VERSION "HNNBNNNYNNNNNNNNNNNNNNNNNNNNNNNNNNNNNNNNNN/4/%%%/4/'%**4NNN///"

NS_ :

BS_:

BU_: BAP_Tester BMS_NV_12V Gateway_Max Klima

BO_ 958 Motor_14: 8 Gateway_Max
 SG_ Motor_14_CRC : 0|8@1+ (1,0) [0|255] ""  Vector__XXX
 SG_ Motor_14_BZ : 8|4@1+ (1,0) [0|15] ""  Vector__XXX
 SG_ MO_StartStopp_Status : 12|2@1+ (1.0,0.0) [0.0|3] ""  Klima
 SG_ MO_StartStopp_Wiederstart : 14|1@1+ (1.0,0.0) [0.0|1] ""  Klima
 SG_ MO_StartStopp_Motorstopp : 15|1@1+ (1.0,0.0) [0.0|1] ""  Klima
 SG_ MO_Freig_Reku : 16|2@1+ (1.0,0.0) [0.0|3] ""  Vector__XXX
 SG_ MO_Kl_75 : 18|1@1+ (1.0,0.0) [0.0|1] ""  Klima
 SG_ MO_Kl_50 : 19|1@1+ (1.0,0.0) [0.0|1] ""  Vector__XXX
 SG_ MO_Gangposition : 20|4@1+ (1.0,0.0) [0.0|15] ""  Vector__XXX
 SG_ MO_StartStopp_Fahrerwunsch : 24|2@1+ (1.0,0.0) [0.0|3] ""  Klima
 SG_ MO_HYB_Fahrbereitschaft : 26|1@1+ (1.0,0.0) [0.0|1] ""  Klima
 SG_ MO_Ext_E_Fahrt_aktiv : 27|1@1+ (1.0,0.0) [0.0|1] ""  Klima
 SG_ MO_Fahrer_bremst : 28|1@1+ (1.0,0.0) [0.0|1] ""  Vector__XXX
 SG_ MO_QBit_Fahrer_bremst : 29|1@1+ (1.0,0.0) [0.0|1] ""  Vector__XXX
 SG_ MO_BLS : 30|1@1+ (1.0,0.0) [0.0|1] ""  Vector__XXX
 SG_ MO_Konsistenz_Bremsped : 31|1@1+ (1.0,0.0) [0.0|1] ""  Vector__XXX
 SG_ MO_Timeout_ESP : 32|1@1+ (1.0,0.0) [0.0|1] ""  Vector__XXX
 SG_ MO_Klima_Eingr : 33|2@1+ (1.0,0.0) [0.0|3] ""  Klima
 SG_ MO_Aussp_Anlass : 35|1@1+ (1.0,0.0) [0.0|1] ""  Vector__XXX
 SG_ MO_Freig_Anlass : 36|1@1+ (1.0,0.0) [0.0|1] ""  Vector__XXX
 SG_ MO_Kuppl_schalter : 37|1@1+ (1.0,0.0) [0.0|1] ""  Vector__XXX
 SG_ MO_Interlock : 38|1@1+ (1.0,0.0) [0.0|1] ""  Vector__XXX
 SG_ MO_Motor_laeuft : 39|1@1+ (1.0,0.0) [0.0|1] ""  Klima
 SG_ MO_Kickdown : 40|1@1+ (1.0,0.0) [0.0|1] ""  Vector__XXX
 SG_ MO_QBit_KL_75 : 41|1@1+ (1.0,0.0) [0.0|1] ""  Vector__XXX
 SG_ MO_EKlKomLeiRed : 42|2@1+ (1.0,0.0) [0.0|3] ""  Klima
 SG_ MO_Handshake_STH : 44|1@1+ (1.0,0.0) [0.0|1] ""  Vector__XXX
 SG_ MO_BKV_Unterdruckwarnung : 45|1@1+ (1.0,0.0) [0.0|1] ""  Vector__XXX
 SG_ MO_Freigabe_Segeln : 46|1@1+ (1.0,0.0) [0.0|1] ""  Vector__XXX
 SG_ MO_PTC_Status : 47|3@1+ (1.0,0.0) [0.0|7] ""  Vector__XXX
 SG_ MO_QBit_Gangposition : 50|1@1+ (1.0,0.0) [0.0|1] ""  Vector__XXX
 SG_ MO_Signalquelle_Gangposition : 51|1@1+ (1.0,0.0) [0.0|1] ""  Vector__XXX
 SG_ MO_Remotestart_Betrieb : 52|1@1+ (1.0,0.0) [0.0|1] ""  Vector__XXX
 SG_ MO_Remotestart_moeglich : 53|1@1+ (1.0,0.0) [0.0|1] ""  Vector__XXX
 SG_ MO_FMAus_aktiv : 55|1@1+ (1.0,0.0) [0.0|1] ""  Vector__XXX
 SG_ MO_FMAus_Startvariante : 56|2@1+ (1.0,0.0) [0.0|3] ""  Vector__XXX
 SG_ MO_BMS_NV_Anf_stuetzen : 58|1@1+ (1.0,0.0) [0.0|1] ""  Vector__XXX
 SG_ MO_Zylinderabschaltung : 59|2@1+ (1.0,0.0) [0.0|3] ""  Vector__XXX
 SG_ MO_HYB_VM_aktiv : 61|1@1+ (1.0,0.0) [0.0|1] ""  Klima
 SG_ MO_StartVorauss_erfuellt : 62|2@1+ (1.0,0.0) [0.0|3] ""  Vector__XXX

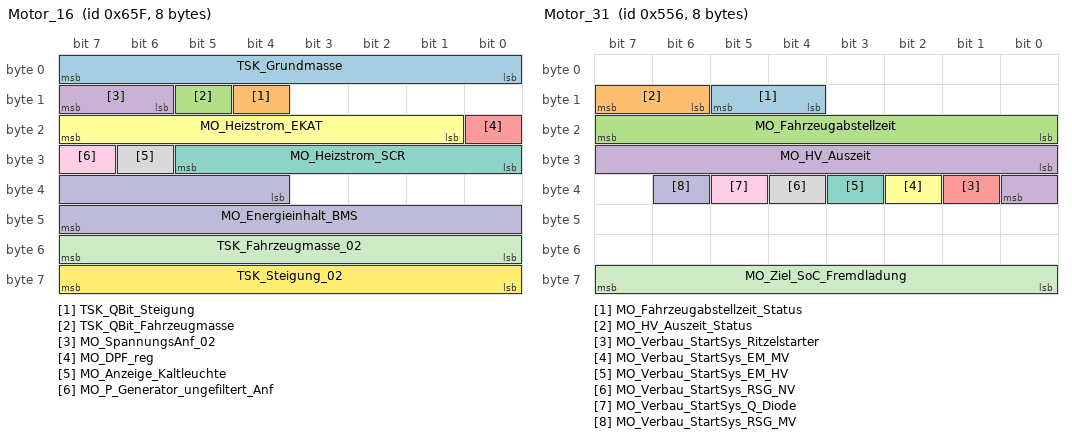
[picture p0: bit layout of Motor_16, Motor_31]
BO_ 1631 Motor_16: 8 Gateway_Max
 SG_ TSK_Grundmasse : 0|8@1+ (32,0) [0|8128] "Unit_KiloGram"  Vector__XXX
 SG_ TSK_QBit_Steigung : 12|1@1+ (1.0,0.0) [0.0|1] ""  Klima
 SG_ TSK_QBit_Fahrzeugmasse : 13|1@1+ (1.0,0.0) [0.0|1] ""  Vector__XXX
 SG_ MO_SpannungsAnf_02 : 14|2@1+ (1.0,0.0) [0.0|3] ""  Vector__XXX
 SG_ MO_DPF_reg : 16|1@1+ (1.0,0.0) [0.0|1] ""  Vector__XXX
 SG_ MO_Heizstrom_EKAT : 17|7@1+ (1,0) [0|126] "Unit_Amper"  Vector__XXX
 SG_ MO_Heizstrom_SCR : 24|6@1+ (1,0) [0|62] "Unit_Amper"  Vector__XXX
 SG_ MO_Anzeige_Kaltleuchte : 30|1@1+ (1.0,0.0) [0.0|1] ""  Vector__XXX
 SG_ MO_P_Generator_ungefiltert_Anf : 31|1@1+ (1.0,0.0) [0.0|1] ""  Vector__XXX
 SG_ MO_Energieinhalt_BMS : 36|12@1+ (25,0) [0|102325] "Unit_WattHour"  Vector__XXX
 SG_ TSK_Fahrzeugmasse_02 : 48|8@1+ (32,0) [0|8128] "Unit_KiloGram"  Vector__XXX
 SG_ TSK_Steigung_02 : 56|8@1+ (0.8,-101.6) [-100.8|101.6] "Unit_PerCent"  Klima

BO_ 1648 Motor_18: 8 Gateway_Max
 SG_ MO_max_Ladedruck : 0|6@1+ (0.1,0) [0.0|6.3] "Unit_Bar"  Vector__XXX
 SG_ MO_ANC_Kennfeld_Anf : 6|2@1+ (1.0,0.0) [0.0|3] ""  Vector__XXX
 SG_ MO_Bremslicht_Reku : 8|1@1+ (1.0,0.0) [0.0|1] ""  Vector__XXX
 SG_ MO_StartStopp_PopUp : 9|2@1+ (1.0,0.0) [0.0|3] ""  Vector__XXX
 SG_ MO1_Sperr_Info_WFS : 11|1@1+ (1.0,0.0) [0.0|1] ""  Vector__XXX
 SG_ MO1_Freigabe_Info_WFS : 12|1@1+ (1.0,0.0) [0.0|1] ""  Vector__XXX
 SG_ MO_EPCL : 13|3@1+ (1.0,0.0) [0.0|7] ""  Vector__XXX
 SG_ MO_Zylabsch_Texte_02 : 16|4@1+ (1.0,0.0) [0.0|15] ""  Vector__XXX
 SG_ MO_Fahrzeugtyp : 20|3@1+ (1.0,0.0) [0.0|7] ""  Vector__XXX
 SG_ MO_NMAX_Schaltanzeige : 23|9@1+ (25,0) [0|12775] "Unit_MinutInver"  Vector__XXX
 SG_ MO_Abstellzeit : 32|8@1+ (8,0) [0|2024] "Unit_Minut"  BMS_NV_12V
 SG_ MO_Abstellzeit_Status : 40|2@1+ (1.0,0.0) [0.0|3] ""  BMS_NV_12V
 SG_ MO1_Freigabe_Verfallsinfo_WFS : 42|1@1+ (1.0,0.0) [0.0|1] ""  Vector__XXX
 SG_ MO_Hybrid_StartStopp_LED : 43|2@1+ (1.0,0.0) [0.0|3] ""  Vector__XXX
 SG_ MO_Fehler_Zylabsch : 45|2@1+ (1.0,0.0) [0.0|3] ""  Vector__XXX
 SG_ MO_Anzahl_Abgesch_Zyl : 47|3@1+ (1.0,0.0) [0.0|7] ""  Vector__XXX
 SG_ MO_Zylabsch_Texte : 50|2@1+ (1.0,0.0) [0.0|3] ""  Vector__XXX
 SG_ MO_Ethanol_BS_Texte : 52|3@1+ (1.0,0.0) [0.0|7] ""  Vector__XXX
 SG_ MO_Drehzahl_Warnung : 55|1@1+ (1.0,0.0) [0.0|1] ""  Vector__XXX
 SG_ MO_obere_Drehzahlgrenze : 56|8@1+ (50,0) [50|12750] "Unit_MinutInver"  Vector__XXX

BO_ 967 Motor_26: 8 Gateway_Max
 SG_ MO_Kuehlerluefter_MUX M  : 0|1@1+ (1.0,0.0) [0.0|1] ""  Klima
 SG_ MO_Kuehlerluefter_1 m0  : 1|7@1+ (1,0) [0|100] "Unit_PerCent"  Klima
 SG_ MO_Kuehlerluefter_2 m1  : 1|7@1+ (1,0) [0|100] "Unit_PerCent"  Klima
 SG_ MO_EFLEX_Lampe : 8|2@1+ (1.0,0.0) [0.0|3] ""  Vector__XXX
 SG_ MO_KJS_nicht_bereit : 10|1@1+ (1.0,0.0) [0.0|1] ""  Vector__XXX
 SG_ MO_ITM_Warnung_Pumpe : 11|1@1+ (1.0,0.0) [0.0|1] ""  Vector__XXX
 SG_ WIV_Anzeige_aktiv : 12|1@1+ (1.0,0.0) [0.0|1] ""  Vector__XXX
 SG_ WIV_Oelmin_Warn : 13|1@1+ (1.0,0.0) [0.0|1] ""  Vector__XXX
 SG_ WIV_Sensorfehler : 14|1@1+ (1.0,0.0) [0.0|1] ""  Vector__XXX
 SG_ WIV_Schieflage : 15|1@1+ (1.0,0.0) [0.0|1] ""  Vector__XXX
 SG_ WIV_Oelstand : 16|4@1+ (12.5,0) [0.0|100.0] "Unit_PerCent"  Vector__XXX
 SG_ MO_Zustand_HWP : 20|2@1+ (1.0,0.0) [0.0|3] ""  Klima
 SG_ OLEV_Systemstoerung : 22|1@1+ (1.0,0.0) [0.0|1] ""  Vector__XXX
 SG_ MO_Oelwarnung_max : 23|1@1+ (1.0,0.0) [0.0|1] ""  Vector__XXX
 SG_ WIV_Oelsystem_aktiv : 24|1@1+ (1.0,0.0) [0.0|1] ""  Vector__XXX
 SG_ WIV_nicht_betriebswarm : 25|1@1+ (1.0,0.0) [0.0|1] ""  Vector__XXX
 SG_ WIV_Ueberfuell_Warn : 26|1@1+ (1.0,0.0) [0.0|1] ""  Vector__XXX
 SG_ WIV_laufender_Motor : 27|1@1+ (1.0,0.0) [0.0|1] ""  Vector__XXX
 SG_ MO_E_Warnungen : 28|4@1+ (1.0,0.0) [0.0|15] ""  Vector__XXX
 SG_ MO_Text_Motorstart : 32|4@1+ (1.0,0.0) [0.0|15] ""  Vector__XXX
 SG_ MO_E_Texte : 36|4@1+ (1.0,0.0) [0.0|15] ""  Vector__XXX
 SG_ WIV_Oeldyn_avl : 40|1@1+ (1.0,0.0) [0.0|1] ""  Vector__XXX
 SG_ MO_Text_Partikelfil_Reg : 41|1@1+ (1,0) [0|1] ""  Vector__XXX
 SG_ OLEV_Oelstand_nicht_vorhanden : 42|1@1+ (1.0,0.0) [0.0|1] ""  Vector__XXX
 SG_ WIV_Oelmenge : 43|5@1+ (125,0) [0|3875] "Unit_MilliLiter"  Vector__XXX
 SG_ MO_Systemlampe : 48|1@1+ (1.0,0.0) [0.0|1] ""  Vector__XXX
 SG_ MO_OBD2_Lampe : 49|1@1+ (1.0,0.0) [0.0|1] ""  Vector__XXX
 SG_ MO_Heissleuchte : 50|1@1+ (1.0,0.0) [0.0|1] ""  Vector__XXX
 SG_ MO_Partikel_Lampe : 51|1@1+ (1.0,0.0) [0.0|1] ""  Vector__XXX
 SG_ MO_RedFahrleistung_Lampe : 52|1@1+ (1.0,0.0) [0.0|1] ""  Klima
 SG_ WIV_Oelstand_nicht_vorhanden : 53|1@1+ (1.0,0.0) [0.0|1] ""  Vector__XXX
 SG_ WIV_nachfuellanzeige_ein : 54|1@1+ (1.0,0.0) [0.0|1] ""  Vector__XXX
 SG_ WIV_Ueberfuell_deaktiv : 55|1@1+ (1.0,0.0) [0.0|1] ""  Vector__XXX
 SG_ WIV_Unterfuell_Warn : 56|1@1+ (1.0,0.0) [0.0|1] ""  Vector__XXX
 SG_ MO_Tankdeckel_Lampe : 57|1@1+ (1.0,0.0) [0.0|1] ""  Vector__XXX
 SG_ MO_Text_Tankdeckelwarn : 58|1@1+ (1.0,0.0) [0.0|1] ""  Vector__XXX
 SG_ MO_Vorglueh_Lampe : 59|1@1+ (1.0,0.0) [0.0|1] ""  Vector__XXX
 SG_ WIV_Oeldr_Warn_Motor : 60|1@1+ (1.0,0.0) [0.0|1] ""  Vector__XXX
 SG_ MO_E_Mode : 61|3@1+ (1.0,0.0) [0.0|7] ""  Vector__XXX

BO_ 1366 Motor_31: 8 Gateway_Max
 SG_ MO_Fahrzeugabstellzeit_Status : 12|2@1+ (1.0,0.0) [0.0|3] ""  Klima
 SG_ MO_HV_Auszeit_Status : 14|2@1+ (1.0,0.0) [0.0|3] ""  Klima
 SG_ MO_Fahrzeugabstellzeit : 16|8@1+ (8,0) [0|2024] "Unit_Minut"  Klima
 SG_ MO_HV_Auszeit : 24|9@1+ (4,0) [0|2036] "Unit_Minut"  Klima
 SG_ MO_Verbau_StartSys_Ritzelstarter : 33|1@1+ (1.0,0.0) [0.0|1] ""  Vector__XXX
 SG_ MO_Verbau_StartSys_EM_MV : 34|1@1+ (1.0,0.0) [0.0|1] ""  Vector__XXX
 SG_ MO_Verbau_StartSys_EM_HV : 35|1@1+ (1.0,0.0) [0.0|1] ""  Vector__XXX
 SG_ MO_Verbau_StartSys_RSG_NV : 36|1@1+ (1.0,0.0) [0.0|1] ""  Vector__XXX
 SG_ MO_Verbau_StartSys_Q_Diode : 37|1@1+ (1.0,0.0) [0.0|1] ""  Vector__XXX
 SG_ MO_Verbau_StartSys_RSG_MV : 38|1@1+ (1.0,0.0) [0.0|1] ""  Vector__XXX
 SG_ MO_Ziel_SoC_Fremdladung : 56|8@1+ (0.4,0) [0.0|100.0] "Unit_PerCent"  Vector__XXX

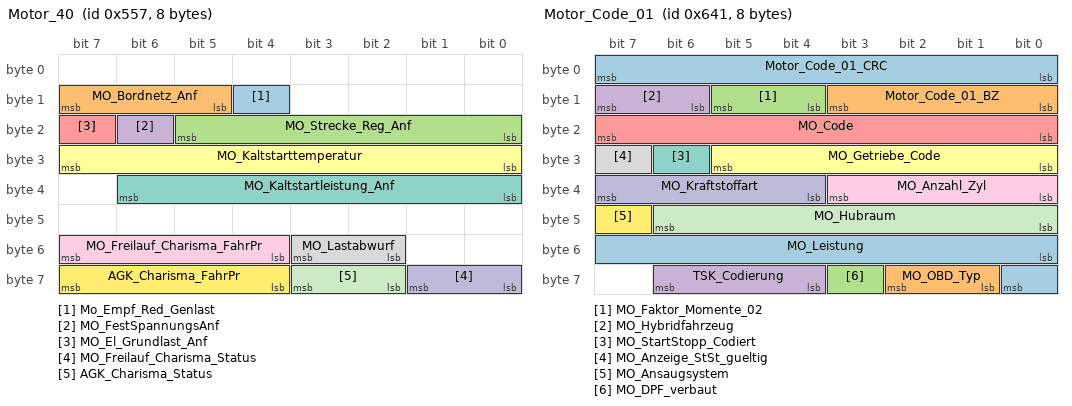
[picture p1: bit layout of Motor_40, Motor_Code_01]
BO_ 1367 Motor_40: 8 Gateway_Max
 SG_ Mo_Empf_Red_Genlast : 12|1@1+ (1.0,0.0) [0.0|1] ""  Vector__XXX
 SG_ MO_Bordnetz_Anf : 13|3@1+ (1.0,0.0) [0.0|7] ""  Vector__XXX
 SG_ MO_Strecke_Reg_Anf : 16|6@1+ (1,0) [0|62] "Unit_KiloMeter"  Vector__XXX
 SG_ MO_FestSpannungsAnf : 22|1@1+ (1.0,0.0) [0.0|1] ""  Vector__XXX
 SG_ MO_El_Grundlast_Anf : 23|1@1+ (1.0,0.0) [0.0|1] ""  Vector__XXX
 SG_ MO_Kaltstarttemperatur : 24|8@1+ (0.5,-40) [-40.0|86.5] "Unit_DegreCelsi"  Vector__XXX
 SG_ MO_Kaltstartleistung_Anf : 32|7@1+ (100,0) [0|12500] "Unit_Watt"  Vector__XXX
 SG_ MO_Lastabwurf : 50|2@1+ (1.0,0.0) [0.0|3] ""  Vector__XXX
 SG_ MO_Freilauf_Charisma_FahrPr : 52|4@1+ (1.0,0.0) [0.0|15] ""  Vector__XXX
 SG_ MO_Freilauf_Charisma_Status : 56|2@1+ (1.0,0.0) [0.0|3] ""  Vector__XXX
 SG_ AGK_Charisma_Status : 58|2@1+ (1.0,0.0) [0.0|3] ""  Vector__XXX
 SG_ AGK_Charisma_FahrPr : 60|4@1+ (1.0,0.0) [0.0|15] ""  Vector__XXX

BO_ 269 Motor_50: 48 Gateway_Max
 SG_ Motor_50_CRC : 0|8@1+ (1,0) [0|255] ""  Vector__XXX
 SG_ Motor_50_BZ : 8|4@1+ (1,0) [0|15] ""  Vector__XXX
 SG_ MO_Mom_Soll_Roh : 12|10@1+ (1,-509) [-509|509] ""  Vector__XXX
 SG_ MO_Mom_Ist_Summe : 22|10@1+ (1,-509) [-509|509] ""  Vector__XXX
 SG_ MO_Mom_Traegheit_Summe : 32|10@1+ (1,-509) [-509|509] ""  Vector__XXX
 SG_ MO_Mom_Soll_gefiltert : 42|10@1+ (1,-509) [-509|509] ""  Vector__XXX
 SG_ MO_Mom_Schub : 52|9@1+ (1,-509) [-509|0] ""  Vector__XXX
 SG_ MO_Status_Normalbetrieb_01 : 61|1@1+ (1.0,0.0) [0.0|1] ""  Vector__XXX
 SG_ MO_erste_Ungenauschwelle : 62|1@1+ (1.0,0.0) [0.0|1] ""  Vector__XXX
 SG_ MO_QBit_Motormomente : 63|1@1+ (1.0,0.0) [0.0|1] ""  Vector__XXX
 SG_ MO_Mom_neg_verfuegbar : 76|9@1+ (1,-509) [-509|0] ""  Vector__XXX
 SG_ MO_Mom_Begr_Fahr : 85|9@1+ (1,0) [0|509] ""  Vector__XXX
 SG_ MO_Mom_Begr_Schalt : 94|10@1+ (1,-509) [-509|509] ""  Vector__XXX
 SG_ MO_Momentenintegral_02 : 104|7@1+ (1,0) [0|100] "Unit_PerCent"  Vector__XXX
 SG_ MO_QBit_Drehzahl_01 : 111|1@1+ (1.0,0.0) [0.0|1] ""  Vector__XXX
 SG_ MO_Drehzahl_01 : 112|16@1+ (0.25,0) [0.00|16383.00] "Unit_MinutInver"  Klima
 SG_ MO_HYB_EMode_Info : 142|2@1+ (1.0,0.0) [0.0|3] ""  Vector__XXX
 SG_ MO_HYB_max_ind_VM_Mom_02 : 144|8@1+ (1.186,0) [0.000|300.058] "Unit_NewtoMeter"  Vector__XXX
 SG_ MO_HYB_Zielzustand : 152|3@1+ (1.0,0.0) [0.0|7] ""  Vector__XXX
 SG_ MO_HYB_Modus_Ankopplung_VM : 155|1@1+ (1.0,0.0) [0.0|1] ""  Vector__XXX
 SG_ MO_HYB_Freigabe_VM_Eingr : 156|2@1+ (1.0,0.0) [0.0|3] ""  Vector__XXX
 SG_ MO_HYB_Sollstatus_K0 : 158|1@1+ (1.0,0.0) [0.0|1] ""  Vector__XXX
 SG_ MO_HYB_Komfortstufe : 159|1@1+ (1.0,0.0) [0.0|1] ""  Vector__XXX
 SG_ MO_HYB_VM_bereit : 160|1@1+ (1.0,0.0) [0.0|1] ""  Vector__XXX
 SG_ MO_HYB_Stoppmodus : 161|1@1+ (1.0,0.0) [0.0|1] ""  Vector__XXX
 SG_ MO_HYB_LowSpeedModus : 162|1@1+ (1.0,0.0) [0.0|1] ""  Vector__XXX
 SG_ MO_HYB_Schaltverhinderung : 163|1@1+ (1.0,0.0) [0.0|1] ""  Vector__XXX
 SG_ MO_HYB_E_Faktor : 164|4@1+ (1.0,0.0) [0.0|15] ""  Vector__XXX
 SG_ MO_HYB_VM_Mom_oE_02 : 168|8@1+ (1.186,-50) [-50.000|250.058] "Unit_NewtoMeter"  Vector__XXX
 SG_ MO_Drehzahl_VM : 176|16@1+ (0.25,0) [0.00|16383.00] "Unit_MinutInver"  Klima
 SG_ MO_EM1_SollDrehzahl : 192|15@1+ (1,-10000) [-10000|22766] "Unit_MinutInver"  Vector__XXX
 SG_ MO_Luftpfad_Verzugszeit_praed : 207|5@1+ (10,0) [10|310] "Unit_MilliSecon"  Vector__XXX
 SG_ MO_EM2_SollDrehzahl : 212|15@1+ (1,-10000) [-10000|22766] "Unit_MinutInver"  Vector__XXX
 SG_ MO_TNW_Min_Strom_Lim : 227|13@1+ (0.5,-2047) [-2047.0|2047.5] "Unit_Amper"  Vector__XXX
 SG_ MO_TNW_Max_Strom_Lim : 240|13@1+ (0.5,-2047) [-2047.0|2047.5] "Unit_Amper"  Vector__XXX

BO_ 332 Motor_54: 32 Gateway_Max
 SG_ Motor_54_CRC : 0|8@1+ (1,0) [0|255] ""  Vector__XXX
 SG_ Motor_54_BZ : 8|4@1+ (1,0) [0|15] ""  Vector__XXX
 SG_ MO_Anforderung_HMS : 12|3@1+ (1.0,0.0) [0.0|7] ""  Vector__XXX
 SG_ FoD_DTC_TSK_GRA : 15|1@1+ (1.0,0.0) [0.0|1] ""  Vector__XXX
 SG_ TSK_vMax_aktuell : 16|8@1+ (1,0) [0|253] "Unit_KiloMeterPerHour"  Vector__XXX
 SG_ ISA_Status : 24|3@1+ (1.0,0.0) [0.0|7] ""  Vector__XXX
 SG_ ISA_Regelung_aktiv : 27|1@1+ (1.0,0.0) [0.0|1] ""  Vector__XXX
 SG_ ISA_Tempolimitwarnung : 28|1@1+ (1.0,0.0) [0.0|1] ""  Vector__XXX
 SG_ MO_Red_El_Fahrleistung : 29|3@1+ (1.0,0.0) [0.0|7] ""  Vector__XXX
 SG_ TSK_Status_EA : 32|3@1+ (1.0,0.0) [0.0|7] ""  Vector__XXX
 SG_ FoD_DTC_TSK_ACC : 35|1@1+ (1.0,0.0) [0.0|1] ""  Vector__XXX
 SG_ TSK_ACC_FoD_Status : 36|2@1+ (1.0,0.0) [0.0|3] ""  Vector__XXX
 SG_ TSK_GRA_FoD_Status : 38|2@1+ (1.0,0.0) [0.0|3] ""  Vector__XXX
 SG_ TSK_vMax_Fahrerassistenz : 40|9@1+ (1,0) [0|510] ""  Vector__XXX
 SG_ TSK_Einheit_vMax_Fahrerassistenz : 49|1@1+ (1.0,0.0) [0.0|1] ""  Vector__XXX
 SG_ TSK_Status_PLA : 50|3@1+ (1.0,0.0) [0.0|7] ""  Vector__XXX
 SG_ TSK_aktives_System : 53|3@1+ (1.0,0.0) [0.0|7] ""  Vector__XXX
 SG_ TSK_erhoehter_Fahrwiderstand : 56|1@1+ (1.0,0.0) [0.0|1] ""  Vector__XXX
 SG_ TSK_Anf_Antriebsmoment : 57|1@1+ (1.0,0.0) [0.0|1] ""  Vector__XXX
 SG_ TSK_Status_ARA : 58|3@1+ (1.0,0.0) [0.0|7] ""  Vector__XXX
 SG_ TSK_Status_IPA : 61|3@1+ (1.0,0.0) [0.0|7] ""  Vector__XXX
 SG_ TSK_aktives_System_02 : 64|4@1+ (1.0,0.0) [0.0|15] ""  Vector__XXX
 SG_ TSK_Status_RHP : 68|3@1+ (1.0,0.0) [0.0|7] ""  Vector__XXX
 SG_ MO_Kuppl_betaetigt : 72|1@1+ (1.0,0.0) [0.0|1] ""  Vector__XXX
 SG_ MO_QBit_Kuppl_betaetigt : 73|1@1+ (1.0,0.0) [0.0|1] ""  Vector__XXX
 SG_ MO_Klima_Regelmodus : 74|2@1+ (1.0,0.0) [0.0|3] ""  Klima
 SG_ MO_Fahrbereitschaft : 76|2@1+ (1.0,0.0) [0.0|3] ""  Vector__XXX
 SG_ MO_Freilauf_Info : 78|2@1+ (1.0,0.0) [0.0|3] ""  Vector__XXX
 SG_ CE_FlgLnchCtlPreCnd : 80|1@1+ (1.0,0.0) [0.0|1] ""  Vector__XXX
 SG_ MO_Krit_Heckobjekt : 81|3@1+ (1.0,0.0) [0.0|7] ""  Vector__XXX
 SG_ MO_NGS_Gangpos : 84|3@1+ (1.0,0.0) [0.0|7] ""  Vector__XXX
 SG_ MO_Freilauf_Status : 87|3@1+ (1.0,0.0) [0.0|7] ""  Vector__XXX
 SG_ MO_EBoost_verf_praed : 90|2@1+ (1.0,0.0) [0.0|3] ""  Vector__XXX
 SG_ MO_Heckspoiler_Anf : 92|1@1+ (1.0,0.0) [0.0|1] ""  Vector__XXX
 SG_ MO_eLaunch_verf : 93|2@1+ (1.0,0.0) [0.0|3] ""  Vector__XXX
 SG_ MO_Positionierung_aktiv : 95|1@1+ (1.0,0.0) [0.0|1] ""  Vector__XXX
 SG_ MO_Veto_Launchcontrol : 96|1@1+ (1.0,0.0) [0.0|1] ""  Vector__XXX
 SG_ MO_Startwunsch : 100|1@1+ (1.0,0.0) [0.0|1] ""  Vector__XXX
 SG_ MO_LaunchControl : 101|1@1+ (1.0,0.0) [0.0|1] ""  Vector__XXX
 SG_ MO_UBE_Hybrid_Reserve : 102|10@1+ (5,0) [0|5110] "Unit_WattHour"  Vector__XXX
 SG_ OBDProtocol_req : 112|8@1+ (1.0,0.0) [0.0|255] ""  BMS_NV_12V,Klima
 SG_ OBD_Calc_Load_Val : 128|8@1+ (0.39215686274509803,0) [0E-17|99.99999999999999765] "Unit_PerCent"  BMS_NV_12V,Klima
 SG_ OBD_Eng_Cool_Temp : 136|8@1+ (1,-40) [-40|215] "Unit_DegreCelsi"  BMS_NV_12V,Klima
 SG_ OBD_Abs_Throttle_Pos : 144|8@1+ (0.39215686274509803,0) [0E-17|99.99999999999999765] "Unit_PerCent"  BMS_NV_12V,Klima
 SG_ OBD_Abs_Load_Val : 152|16@1+ (0.39215686274509803,0) [0E-17|25699.99999999999939605] "Unit_PerCent"  BMS_NV_12V,Klima
 SG_ OBD_Abs_Pedal_Pos : 168|8@1+ (0.39215686274509803,0) [0E-17|99.99999999999999765] "Unit_PerCent"  BMS_NV_12V,Klima
 SG_ MO_Servicemodus : 176|4@1+ (1.0,0.0) [0.0|15] ""  Vector__XXX
 SG_ OBD_ClearMem_Inhibit : 183|1@1+ (1.0,0.0) [0.0|1] ""  BMS_NV_12V
 SG_ OBD_Sperrung_Kaltstart_Denom : 184|1@1+ (1.0,0.0) [0.0|1] ""  BMS_NV_12V
 SG_ MO_QBit_Aussen_Temp : 185|1@1+ (1.0,0.0) [0.0|1] ""  Klima
 SG_ OBD_Sperrung_IUMPR : 186|1@1+ (1.0,0.0) [0.0|1] ""  BMS_NV_12V,Klima
 SG_ OBD_Kaltstart_Denominator : 187|1@1+ (1.0,0.0) [0.0|1] ""  BMS_NV_12V,Klima
 SG_ OBD_Minimum_Trip : 188|1@1+ (1.0,0.0) [0.0|1] ""  BMS_NV_12V,Klima
 SG_ OBD_Driving_Cycle : 189|1@1+ (1.0,0.0) [0.0|1] ""  BMS_NV_12V,Klima
 SG_ OBD_Warm_Up_Cycle : 190|1@1+ (1.0,0.0) [0.0|1] ""  BMS_NV_12V,Klima
 SG_ OBD_Normed_Trip : 191|1@1+ (1.0,0.0) [0.0|1] ""  BMS_NV_12V,Klima
 SG_ MO_EMG_Min_Leistung : 192|11@1+ (100,-102200) [-102200|102300] "Unit_Watt"  Vector__XXX
 SG_ MO_EMG_Max_Leistung : 203|11@1+ (100,-102200) [-102200|102300] "Unit_Watt"  Vector__XXX
 SG_ MO_MVEM_MinLeistung_MVVerbrauch : 214|10@1+ (50,-10500) [-10500|40500] "Unit_Watt"  Vector__XXX
 SG_ MO_MVEM_MaxLeistung_MVVerbrauch : 224|10@1+ (50,-10500) [-10500|40500] "Unit_Watt"  Vector__XXX
 SG_ MO_UBE_Reserve : 238|10@1+ (5,0) [0|5110] "Unit_WattHour"  Vector__XXX
 SG_ OBD_Aussen_Temp_gef : 248|8@1+ (1,-40) [-40|213] "Unit_DegreCelsi"  BMS_NV_12V

BO_ 553 Motor_54_SOK_Signatur: 4 Gateway_Max
 SG_ SOK_Motor_54_Signatur : 0|32@1+ (1,0) [0|4294967295] ""  Klima

BO_ 190 Motor_56: 48 Gateway_Max
 SG_ Motor_56_CRC : 0|8@1+ (1,0) [0|255] ""  Vector__XXX
 SG_ Motor_56_BZ : 8|4@1+ (1,0) [0|15] ""  Vector__XXX
 SG_ MO_EM1_MinDrehzahl : 12|14@1+ (2,-10000) [-10000|22764] "Unit_MinutInver"  Vector__XXX
 SG_ MO_EM1_MaxDrehzahl : 26|14@1+ (2,-10000) [-10000|22764] "Unit_MinutInver"  Vector__XXX
 SG_ MO_EM1_DynLimit_AR : 40|8@1+ (1,0) [0|254] "Unit_NewtoMeter"  Vector__XXX
 SG_ MO_EM1_Periode_AR : 48|8@1+ (0.001953125,0) [0E-9|0.496093750] "Unit_Secon"  Vector__XXX
 SG_ MO_EM1_SollMoment : 56|12@1+ (0.5,-1023) [-1023.0|1023.5] "Unit_NewtoMeter"  Vector__XXX
 SG_ MO_EM1_Sollmodus : 68|4@1+ (1.0,0.0) [0.0|15] ""  Vector__XXX
 SG_ MO_EM1_Min_Leistung : 72|14@1+ (100,-819000) [-819000|819100] "Unit_Watt"  Vector__XXX
 SG_ MO_EM1_Max_Leistung : 86|14@1+ (100,-819000) [-819000|819100] "Unit_Watt"  Vector__XXX
 SG_ MO_EM1_Min_Strom_Lim : 100|13@1+ (0.5,-2047) [-2047.0|2047.5] "Unit_Amper"  Vector__XXX
 SG_ MO_EM1_Max_Strom_Lim : 113|13@1+ (0.5,-2047) [-2047.0|2047.5] "Unit_Amper"  Vector__XXX
 SG_ MO_EM1_AR_Anf : 126|3@1+ (1.0,0.0) [0.0|7] ""  Vector__XXX
 SG_ MO_EM1_Kp_AR : 129|9@1+ (0.00390625,0) [0E-8|1.99218750] "Unit_NewtoMeterPerRPM"  Vector__XXX
 SG_ MO_EM1_SollSpannung : 138|12@1+ (0.5,0) [0.0|2047.0] "Unit_Volt"  Vector__XXX
 SG_ MO_CluEng_Set : 150|2@1+ (1.0,0.0) [0.0|3] ""  Vector__XXX
 SG_ MO_EM2_MinDrehzahl : 156|14@1+ (2,-10000) [-10000|22764] "Unit_MinutInver"  Vector__XXX
 SG_ MO_EM2_MaxDrehzahl : 170|14@1+ (2,-10000) [-10000|22764] "Unit_MinutInver"  Vector__XXX
 SG_ MO_EM2_DynLimit_AR : 184|8@1+ (1,0) [0|254] "Unit_NewtoMeter"  Vector__XXX
 SG_ MO_EM2_Periode_AR : 192|8@1+ (0.001953125,0) [0E-9|0.496093750] "Unit_Secon"  Vector__XXX
 SG_ MO_EM2_SollMoment : 200|12@1+ (0.5,-1023) [-1023.0|1023.5] "Unit_NewtoMeter"  Vector__XXX
 SG_ MO_EM2_Sollmodus : 212|4@1+ (1.0,0.0) [0.0|15] ""  Vector__XXX
 SG_ MO_EM2_Min_Leistung : 216|14@1+ (100,-819000) [-819000|819100] "Unit_Watt"  Vector__XXX
 SG_ MO_EM2_Max_Leistung : 230|14@1+ (100,-819000) [-819000|819100] "Unit_Watt"  Vector__XXX
 SG_ MO_EM2_Min_Strom_Lim : 244|13@1+ (0.5,-2047) [-2047.0|2047.5] "Unit_Amper"  Vector__XXX
 SG_ MO_EM2_Max_Strom_Lim : 257|13@1+ (0.5,-2047) [-2047.0|2047.5] "Unit_Amper"  Vector__XXX
 SG_ MO_EM2_AR_Anf : 270|3@1+ (1.0,0.0) [0.0|7] ""  Vector__XXX
 SG_ MO_EM2_Kp_AR : 273|9@1+ (0.00390625,0) [0E-8|1.99218750] "Unit_NewtoMeterPerRPM"  Vector__XXX
 SG_ MO_EM2_SollSpannung : 282|12@1+ (0.5,0) [0.0|2047.0] "Unit_Volt"  Vector__XXX
 SG_ MO_CluAxs_Set : 294|2@1+ (1.0,0.0) [0.0|3] ""  Vector__XXX
 SG_ MO_DC_Max_Strom_HV : 296|8@1+ (0.2,0) [0.0|50.8] "Unit_Amper"  Vector__XXX
 SG_ MO_DC_SollSpannung_HV : 304|8@1+ (2,0) [0|508] "Unit_Volt"  Vector__XXX
 SG_ MO_EM1_Max_Moment : 312|12@1+ (0.5,-1023) [-1023.0|1023.5] "Unit_NewtoMeter"  Vector__XXX
 SG_ MO_EM1_Min_Moment : 324|12@1+ (0.5,-1023) [-1023.0|1023.5] "Unit_NewtoMeter"  Vector__XXX
 SG_ MO_EM2_Max_Moment : 336|12@1+ (0.5,-1023) [-1023.0|1023.5] "Unit_NewtoMeter"  Vector__XXX
 SG_ MO_EM2_Min_Moment : 348|12@1+ (0.5,-1023) [-1023.0|1023.5] "Unit_NewtoMeter"  Vector__XXX
 SG_ SOK_MO_SollMoment_Signatur : 360|24@1+ (1,0) [0|16777215] "Unit_None"  Vector__XXX

BO_ 1601 Motor_Code_01: 8 Gateway_Max
 SG_ Motor_Code_01_CRC : 0|8@1+ (1,0) [0|255] ""  Vector__XXX
 SG_ Motor_Code_01_BZ : 8|4@1+ (1,0) [0|15] ""  Vector__XXX
 SG_ MO_Faktor_Momente_02 : 12|2@1+ (1,0) [1|3] "Unit_NewtoMeter"  Vector__XXX
 SG_ MO_Hybridfahrzeug : 14|2@1+ (1.0,0.0) [0.0|3] ""  Klima
 SG_ MO_Code : 16|8@1+ (1,0) [0|255] ""  Vector__XXX
 SG_ MO_Getriebe_Code : 24|6@1+ (1.0,0.0) [0.0|63] ""  Vector__XXX
 SG_ MO_StartStopp_Codiert : 30|1@1+ (1.0,0.0) [0.0|1] ""  Vector__XXX
 SG_ MO_Anzeige_StSt_gueltig : 31|1@1+ (1.0,0.0) [0.0|1] ""  Vector__XXX
 SG_ MO_Anzahl_Zyl : 32|4@1+ (1.0,0.0) [0.0|15] ""  Vector__XXX
 SG_ MO_Kraftstoffart : 36|4@1+ (1.0,0.0) [0.0|15] ""  Vector__XXX
 SG_ MO_Hubraum : 40|7@1+ (0.1,0) [0.0|12.7] "Unit_Liter"  Vector__XXX
 SG_ MO_Ansaugsystem : 47|1@1+ (1.0,0.0) [0.0|1] ""  Vector__XXX
 SG_ MO_Leistung : 48|9@1+ (1,0) [0|511] "Unit_KiloWatt"  Vector__XXX
 SG_ MO_OBD_Typ : 57|2@1+ (1.0,0.0) [0.0|3] ""  BMS_NV_12V,Klima
 SG_ MO_DPF_verbaut : 59|1@1+ (1.0,0.0) [0.0|1] ""  Vector__XXX
 SG_ TSK_Codierung : 60|3@1+ (1.0,0.0) [0.0|7] ""  Vector__XXX

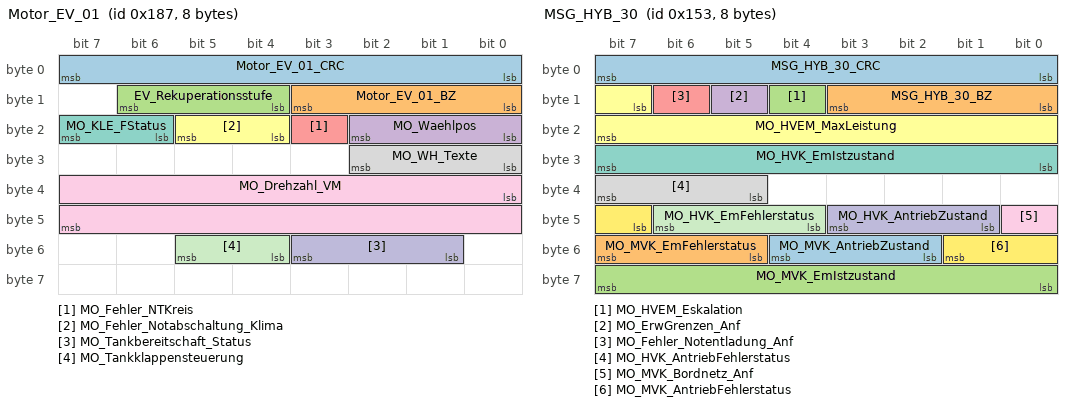
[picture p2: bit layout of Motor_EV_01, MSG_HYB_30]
BO_ 391 Motor_EV_01: 8 Gateway_Max
 SG_ Motor_EV_01_CRC : 0|8@1+ (1,0) [0|255] ""  Vector__XXX
 SG_ Motor_EV_01_BZ : 8|4@1+ (1,0) [0|15] ""  Vector__XXX
 SG_ EV_Rekuperationsstufe : 12|3@1+ (1.0,0.0) [0.0|7] ""  Vector__XXX
 SG_ MO_Waehlpos : 16|3@1+ (1.0,0.0) [0.0|7] ""  Vector__XXX
 SG_ MO_Fehler_NTKreis : 19|1@1+ (1.0,0.0) [0.0|1] ""  Vector__XXX
 SG_ MO_Fehler_Notabschaltung_Klima : 20|2@1+ (1.0,0.0) [0.0|3] ""  Vector__XXX
 SG_ MO_KLE_FStatus : 22|2@1+ (1.0,0.0) [0.0|3] ""  Klima
 SG_ MO_WH_Texte : 24|3@1+ (1.0,0.0) [0.0|7] ""  Vector__XXX
 SG_ MO_Drehzahl_VM : 32|16@1+ (0.25,0) [0.00|16383.00] "Unit_MinutInver"  BMS_NV_12V
 SG_ MO_Tankbereitschaft_Status : 49|3@1+ (1.0,0.0) [0.0|7] ""  Vector__XXX
 SG_ MO_Tankklappensteuerung : 52|2@1+ (1.0,0.0) [0.0|3] ""  Vector__XXX

BO_ 339 MSG_HYB_30: 8 Gateway_Max
 SG_ MSG_HYB_30_CRC : 0|8@1+ (1,0) [0|255] ""  Vector__XXX
 SG_ MSG_HYB_30_BZ : 8|4@1+ (1,0) [0|15] ""  Vector__XXX
 SG_ MO_HVEM_Eskalation : 12|1@1+ (1.0,0.0) [0.0|1] ""  Vector__XXX
 SG_ MO_ErwGrenzen_Anf : 13|1@1+ (1.0,0.0) [0.0|1] ""  Vector__XXX
 SG_ MO_Fehler_Notentladung_Anf : 14|1@1+ (1.0,0.0) [0.0|1] ""  Vector__XXX
 SG_ MO_HVEM_MaxLeistung : 15|9@1+ (50,0) [0|25450] "Unit_Watt"  Klima
 SG_ MO_HVK_EmIstzustand : 24|8@1+ (1.0,0.0) [0.0|255] ""  Vector__XXX
 SG_ MO_HVK_AntriebFehlerstatus : 37|3@1+ (1.0,0.0) [0.0|7] ""  Vector__XXX
 SG_ MO_MVK_Bordnetz_Anf : 40|1@1+ (1.0,0.0) [0.0|1] ""  Vector__XXX
 SG_ MO_HVK_AntriebZustand : 41|3@1+ (1.0,0.0) [0.0|7] ""  Vector__XXX
 SG_ MO_HVK_EmFehlerstatus : 44|3@1+ (1.0,0.0) [0.0|7] ""  Vector__XXX
 SG_ MO_MVK_AntriebFehlerstatus : 47|3@1+ (1.0,0.0) [0.0|7] ""  Vector__XXX
 SG_ MO_MVK_AntriebZustand : 50|3@1+ (1.0,0.0) [0.0|7] ""  Vector__XXX
 SG_ MO_MVK_EmFehlerstatus : 53|3@1+ (1.0,0.0) [0.0|7] ""  Vector__XXX
 SG_ MO_MVK_EmIstzustand : 56|8@1+ (1.0,0.0) [0.0|255] ""  Vector__XXX

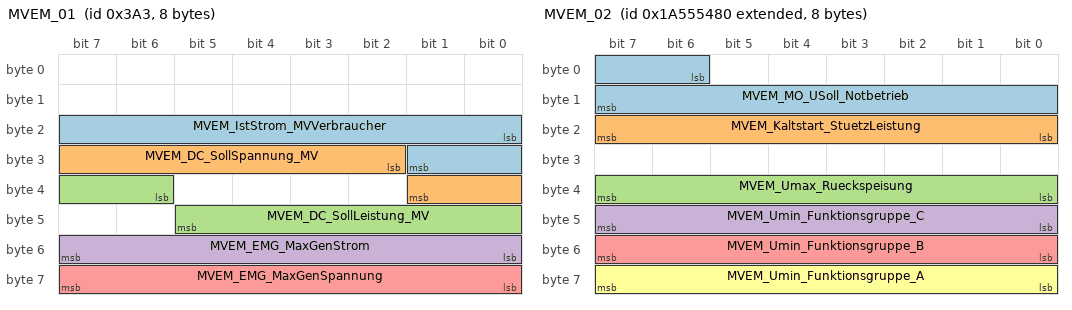
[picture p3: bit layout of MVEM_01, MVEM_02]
BO_ 931 MVEM_01: 8 Gateway_Max
 SG_ MVEM_IstStrom_MVVerbraucher : 16|10@1+ (1,-511) [-511|510] "Unit_Amper"  Vector__XXX
 SG_ MVEM_DC_SollSpannung_MV : 26|8@1+ (0.25,0) [0.00|63.25] "Unit_Volt"  Vector__XXX
 SG_ MVEM_DC_SollLeistung_MV : 38|8@1+ (25,-6325) [-6325|0] "Unit_Watt"  Vector__XXX
 SG_ MVEM_EMG_MaxGenStrom : 48|8@1+ (2,0) [0|506] "Unit_Amper"  Vector__XXX
 SG_ MVEM_EMG_MaxGenSpannung : 56|8@1+ (0.25,0) [0.00|63.25] "Unit_Volt"  Vector__XXX

BO_ 2589283456 MVEM_02: 8 Gateway_Max
 SG_ MVEM_MO_USoll_Notbetrieb : 6|10@1+ (0.0625,0) [0.0000|63.8125] "Unit_Volt"  Vector__XXX
 SG_ MVEM_Kaltstart_StuetzLeistung : 16|8@1+ (20,0) [0|5060] "Unit_Watt"  Vector__XXX
 SG_ MVEM_Umax_Rueckspeisung : 32|8@1+ (0.25,0) [0.00|63.25] "Unit_Volt"  Vector__XXX
 SG_ MVEM_Umin_Funktionsgruppe_C : 40|8@1+ (0.25,0) [0.00|63.25] "Unit_Volt"  Vector__XXX
 SG_ MVEM_Umin_Funktionsgruppe_B : 48|8@1+ (0.25,0) [0.00|63.25] "Unit_Volt"  Vector__XXX
 SG_ MVEM_Umin_Funktionsgruppe_A : 56|8@1+ (0.25,0) [0.00|63.25] "Unit_Volt"  Vector__XXX

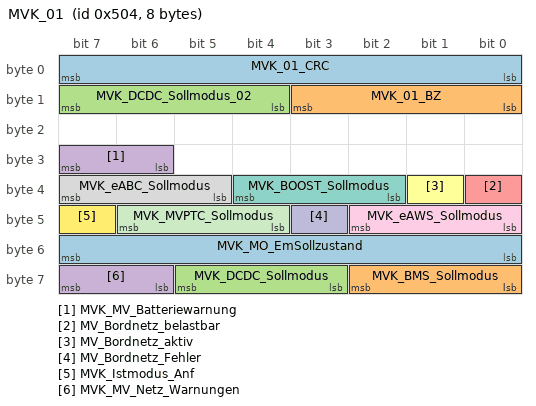
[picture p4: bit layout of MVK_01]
BO_ 1284 MVK_01: 8 Gateway_Max
 SG_ MVK_01_CRC : 0|8@1+ (1,0) [0|255] ""  Vector__XXX
 SG_ MVK_01_BZ : 8|4@1+ (1,0) [0|15] ""  Vector__XXX
 SG_ MVK_DCDC_Sollmodus_02 : 12|4@1+ (1.0,0.0) [0.0|15] ""  Vector__XXX
 SG_ MVK_MV_Batteriewarnung : 30|2@1+ (1.0,0.0) [0.0|3] ""  Vector__XXX
 SG_ MV_Bordnetz_belastbar : 32|1@1+ (1.0,0.0) [0.0|1] ""  Vector__XXX
 SG_ MV_Bordnetz_aktiv : 33|1@1+ (1.0,0.0) [0.0|1] ""  Vector__XXX
 SG_ MVK_BOOST_Sollmodus : 34|3@1+ (1.0,0.0) [0.0|7] ""  Vector__XXX
 SG_ MVK_eABC_Sollmodus : 37|3@1+ (1.0,0.0) [0.0|7] ""  Vector__XXX
 SG_ MVK_eAWS_Sollmodus : 40|3@1+ (1.0,0.0) [0.0|7] ""  Vector__XXX
 SG_ MV_Bordnetz_Fehler : 43|1@1+ (1.0,0.0) [0.0|1] ""  Vector__XXX
 SG_ MVK_MVPTC_Sollmodus : 44|3@1+ (1.0,0.0) [0.0|7] ""  Vector__XXX
 SG_ MVK_Istmodus_Anf : 47|1@1+ (1.0,0.0) [0.0|1] ""  Vector__XXX
 SG_ MVK_MO_EmSollzustand : 48|8@1+ (1.0,0.0) [0.0|255] ""  Vector__XXX
 SG_ MVK_BMS_Sollmodus : 56|3@1+ (1.0,0.0) [0.0|7] ""  Vector__XXX
 SG_ MVK_DCDC_Sollmodus : 59|3@1+ (1.0,0.0) [0.0|7] ""  Vector__XXX
 SG_ MVK_MV_Netz_Warnungen : 62|2@1+ (1.0,0.0) [0.0|3] ""  Vector__XXX

CM_ BO_ 1648 "Kombischnittstelle";
CM_ BO_ 967 "MQB - vorher Motor_06 / Umbenennung wg. ID-Wechsel";
CM_ BO_ 1601 "ab MQB mit CRC-8";
CM_ BO_ 339 "CAN-Botschaft";

CM_ SG_ 958 MO_Aussp_Anlass "Das Signal zeigt an, ob die Wiederholstartsperre aktiv ist. D. h. eine Ansteuerung des Anlassers wird auch bei erfüllten Startvoraussetzungen (HS: Interlock betätigt bzw. AT: P/N eingelegt und Bremse betätigt) nicht erfolgen.";
CM_ SG_ 958 MO_BKV_Unterdruckwarnung "Über die Unterdruckwarnung signalisiert das MSG dem ESP, dass kein ausreichender Unterdruck für den BKV zur Verfügung gestellt werden kann.";
CM_ SG_ 958 MO_BLS "Ungefiltertes Rohsignal des Bremslichtschalters, nur wenn HW-Eingang bestückt und ausgewertet wird. Bei Motoren ohne genutzten HW-Eingang wird kein Ersatzwert (bspw. SW-Signal über CAN) ausgegeben!
Bei AUDI muss das Signal wg. Bremslichtfunktion immer be";
CM_ SG_ 958 MO_BMS_NV_Anf_stuetzen "Garantierte Unterstützung des Zusatzspeichers ist erforderlich. Zusatzspeicher muss an das Versorgungsnezt angebunden werden. ";
CM_ SG_ 958 MO_EKlKomLeiRed "Anforderung an die Klimasteuerung, die Leistungsaufnahme des E-Kompressors bei schlechtem SOC und in bestimmten Fahrsituationen zu begrenzen. (Das bereits bestehende Signal 'Klimakompressor aus' als stets umzusetzende Anforderung bleibt unverändert besteh";
CM_ SG_ 958 MO_Ext_E_Fahrt_aktiv "Funktionsrückmeldung zum erw. E-Fahr-Betrieb über Lampe/LED im E-Mode-Taster";
CM_ SG_ 958 MO_Fahrer_bremst "Redundante Bremsinformation vom Motor.

MLB:
AUDI D4: Zykluszeit: 10ms (siehe Zykluszeit schnell/Cycletime Fast)
Im AUDI B8 wird in diesem Bit der Wert der ESP-CAN-Information 'ESP_Fahrer_bremst' ausgegeben.

Achtung:
Reduktion der Zykluszeit Motor";
CM_ SG_ 958 MO_FMAus_aktiv "Das Signal gibt Rückmeldung ob Freilauf Motor aus aktiv ist. Beleibt auch 0km/h (unterhalb der StartStopp Schwelle) weiterhin aktiv.";
CM_ SG_ 958 MO_FMAus_Startvariante "Startvariante beim Motorstart aus der Freilauf-Motor-AUS Phase";
CM_ SG_ 958 MO_Freig_Anlass "Bit wird gesetzt, wenn der Motor beim Automatikstart gestartet werden darf (Motorstillstand, Emissionsmaßnahmen sind erfüllt).";
CM_ SG_ 958 MO_Freig_Reku "Empfehlung des Motor-SG's zur Spannungsabsenkung/-anhebung für den Rekuperationsbetrieb";
CM_ SG_ 958 MO_Freigabe_Segeln "Freigabebit des Segelbetriebs im Getriebe. Bedingt durch bestimmte Diagnosen und Adaptionen des MSGs, die nur im Schub möglich sind, darf nicht jede Schubphase für einen Segelbetrieb genutzt werden. Eine Freigabe bleibt auch außerhalb einer Schubphase bes";
CM_ SG_ 958 MO_Gangposition "MLB:
Stellung des Wählhebels in der Schaltgasse des Handschaltgetriebes.
MLBevo: 
Ausweitung der Bedienung auch auf Automatikgetriebe;
Routing des Signals GE_Fahrstufe: 
1. Position_R (dez. 6) auf MO_Gangposition: Gang_R (dez. 13) wegen Entfall Signa";
CM_ SG_ 958 MO_Handshake_STH "Es gilt: Signalspec MO_Handshake v1.0

Handshake zwischen MSG und STH. Wenn das MSG die EKP aufgrund einer STH-Anforderung ansteuert und kein Fehlereintrag bzgl. EKP/KPE/NDR vorliegt, wird das Bit gesetzt.";
CM_ SG_ 958 MO_HYB_Fahrbereitschaft "Signal steuert u.a. in der Lenkhilfe zusammen mit weiteren Informationen den Modewechsel in den 'Drivemode'
Grüne Anzeige im Kombiinstrument zur Signalisierung der Bereitschaft des Hybridsystems.";
CM_ SG_ 958 MO_HYB_VM_aktiv "0 = VMotor wird nicht aktiv gehalten (nVM < n_min und keine LL-Regelung aktiv)
1 = VMotor aktiv (ab der ersten Einspritzung; gilt auch für Schubbetrieb, wenn VMotor spätestens durch LLRegelung befeuert würde)
Verwendet zur Bestimmung des Ist-Zustandes";
CM_ SG_ 958 MO_Interlock "Das Motorsteuergerät gibt die Information aus, ab wann der Kupplungsschalter durch das Motorsteuergerät als getreten gesehen wird.
Bei Systemen für Start Stopp muss das Interlocksignal für einen Start durch das MSG generiert werden, sobald der Schalthebe";
CM_ SG_ 958 MO_Kickdown "Es gilt: Signalspec MO_Kickdown v1.0";
CM_ SG_ 958 MO_Kl_50 "Klemme 50: Startausführung durch Ritzelstarter

MLB: nicht von allen Motoren gesendet
MQB/MLBevo: gesendet von allen Motoren";
CM_ SG_ 958 MO_Kl_75 "Klemme X
";
CM_ SG_ 958 MO_Klima_Eingr "Eingriffe des Motor bei der Klima";
CM_ SG_ 958 MO_Konsistenz_Bremsped "MLB:

AUDI D4: Zykluszeit: 10ms (siehe Zykluszeit schnell/Cycletime Fast)
Siehe 'Funktionsspezifikation Bremslichtinfo B8'

Achtung:
Reduktion der Zykluszeit Motor_03 auf 10ms geplant.
Projektabhängig soll künftig mit 10ms gesendet werden.
Empfäng";
CM_ SG_ 958 MO_Kuppl_schalter "MLB:
Das Motorsteuergerät gibt die Information aus, ab wann der Kupplungsschalter durch das Motorsteuergerät als getreten gesehen wird
0x0: Schalter sagt betätigt (Ausgekuppelt)
0x1: Schalter sagt nicht betätigt (Eingekuppelt)

MQB:
Nur Handschalter";
CM_ SG_ 958 MO_Motor_laeuft "Das Motorsteuergerät gibt die Information aus, ab wann der Motor verbrennungsbedingt autark läuft und durch zuschaltbare Nebenaggregate mechanisch belastbar ist (z.B. durch Generator, Klimakompressor, etc.).

Die 'Motor läuft' Information wird ausgegebe";
CM_ SG_ 958 MO_PTC_Status "Status-Rückmeldung vom MSG zum aktuellen PTC-Status (stufiges PTC, Relais am MSG). Bei Ansteuerung eines stufigen PTC durch ein anderes SG beschreibt das Signal die vom MSG freigegebene PTC-Stufe.";
CM_ SG_ 958 MO_QBit_Fahrer_bremst "MLB:
AUDI D4: Zykluszeit: 10ms (siehe Zykluszeit schnell/Cycletime Fast)

Achtung:
Reduktion der Zykluszeit Motor_03 auf 10ms geplant.
Projektabhängig soll künftig mit 10ms gesendet werden.
Empfänger die in weiteren Konzern-Projekten eingesetzt werd";
CM_ SG_ 958 MO_QBit_Gangposition "Qualitätsbit zum Signal MO_Gangposition";
CM_ SG_ 958 MO_QBit_KL_75 "Q - Bit für das KL 75 Signal zur Vermeidung der fehlerhaften Erkennung von Motorstarts. 
Wird auf 1 gesetzt, solange das Motorsteuergerät KL15 = AUS erkannt hat.";
CM_ SG_ 958 MO_Remotestart_Betrieb "Das MSG ist für den Remotestart-Betrieb bereit. Nach Empfang der Motorstartanforderung für RSt-Betrieb durch BCM wird der Fahrzeugmotor gestartet und solange der Motor läuft, bleibt dieses Bit aktiv. Dieses Signal ist nur zur Verwendung durch das BCM zur ";
CM_ SG_ 958 MO_Remotestart_moeglich "Wenn Bit gesetzt, würde das MSG bei entsprechender Anforderung durch das BCM den Remotestartbetrieb einleiten, d.h. das MSG ist remotestartfähig und es liegen aktuell keine relevanten Fehler oder andere Abbruchgründe vor.";
CM_ SG_ 958 MO_Signalquelle_Gangposition "Signalquelle des Signals MO_Gangposition
0: Signalquelle Gangpositionssensor
1: Signalquelle Modellwert (v/n)";
CM_ SG_ 958 MO_StartStopp_Fahrerwunsch "Fahreraktivität Start/Stop";
CM_ SG_ 958 MO_StartStopp_Motorstopp "Motor-Stopp durch Start/Stopp-Koordinator
HYBRID:
Wenn MO_Hybridfahrzeug = 1 gilt:
Verbrennungsmotor durch Hybrid-Koordinator im MSG ausgeschaltet. 
Die definierten Start/Stopp-Signale beziehen sich nur auf den Verbrennungsmotor!";
CM_ SG_ 958 MO_StartStopp_Status "Aktivitätsstatus Start/Stopp-Koordinator
HYBRID:
Wenn MO_Hybridfahrzeug = 1 gilt:
Signal bezieht sich nur auf den Verbrennungsmotor, nicht auf den Hybridantrieb
";
CM_ SG_ 958 MO_StartStopp_Wiederstart "Motorwiederstart durch Start/Stopp-Koordinator
HYBRID:
Wenn MO_Hybridfahrzeug =1 gilt:
Warnung vor Spannungseinbruch beim Zustart des Verbrennungsmotors. 
-nicht relevant, da derzeit kein Start über 12V-Starter geplant-
Dieses Signal wird nur vom Hyb";
CM_ SG_ 958 MO_StartVorauss_erfuellt "Dient der Fallunterscheidung bei ZAT-Betätigung im Zustand 'KL15 ein' (bei nicht gesetztem Signal folgt KL15 aus, bei gesetztem Signal folgt setzen KL50-Anf.)

0: Signal nicht bedient 
1: Voraussetzungen zur Antriebsstrangaktivierung / Startvoraussetzu";
CM_ SG_ 958 MO_Timeout_ESP "500 ms Timeout auf Bremsen-Botschaft ist >= 1 mal aufgelaufen, Löschen des Bits nach Neustart (KL15).

MLB:
AUDI D4: Zykluszeit: 10ms (siehe Zykluszeit schnell/Cycletime Fast)

Achtung:
Reduktion der Zykluszeit Motor_03 auf 10ms geplant.
Projektabh";
CM_ SG_ 958 MO_Zylinderabschaltung "Status Zylinderabschaltung Motor";
CM_ SG_ 958 Motor_14_CRC "Ab MQB und MLBevo:
'Berechnung siehe Lastenheft 'End-to-End Kommunikationsabsicherung'

Endwerte siehe Begleitdokument 'S-PDU Kennungsfolgen'";

CM_ SG_ 1631 MO_Anzeige_Kaltleuchte "Fahrleistungseinschänkungen aus dem Motor-Abgasmanagement zur Anzeige als Lampe ohne Hinweistext im Kombiinstrument";
CM_ SG_ 1631 MO_DPF_reg "Regeneration Diesel-Partikel-Filter";
CM_ SG_ 1631 MO_Energieinhalt_BMS "Restenergieinhalt der Traktionsbatterie, beeinflusst durch Fahrstrategie und weiteren Faktoren der Antriebssteuerung.";
CM_ SG_ 1631 MO_Heizstrom_EKAT "Aktuelle Gesamtstromaufnahme des E-Katalysators";
CM_ SG_ 1631 MO_Heizstrom_SCR "Aktuelle Gesamtstromaufnahme der Tank-, Fördermodul- und Leitungsheizung des SCR-Systems";
CM_ SG_ 1631 MO_P_Generator_ungefiltert_Anf "Bei Empfang der Anforderung soll der Sender BEM_P_Generator ungefiltert befüllen.";
CM_ SG_ 1631 MO_SpannungsAnf_02 "Forderung des Motor-SG's zur Spannungsanhebung";
CM_ SG_ 1631 TSK_Fahrzeugmasse_02 "Neue Definition ab D4
Fahrzeugmasse in kg. Das Signal dient der Anpassung der Sollbeschleunigung vom ACC


";
CM_ SG_ 1631 TSK_Grundmasse "Fahrzeuggrundmasse in kg. Das Signal dient der Anpassung der Sollbeschleunigung vom ACC

Hinweis: Ehemaliger Fehlerwert 0x7F wird senderseitig nicht unterstützt. Diesen Wert aus Kompatibilitätsgründen nicht neu belegen!";
CM_ SG_ 1631 TSK_Steigung_02 "Steigung in % Berg. Das Signal dient der Anpassung der Sollbeschleunigung vom ACC

Positive Werte > bergauf; 
Negative Werte < bergab

Fehler: Die Steigung aufgrund eines Fehlers (mit KD-Fehlereintrag) nicht mehr berechnet werden";

CM_ SG_ 1648 MO1_Freigabe_Info_WFS "WFS-Freigabeinformation";
CM_ SG_ 1648 MO1_Freigabe_Verfallsinfo_WFS "WFS-Freigabeverfallsinformation";
CM_ SG_ 1648 MO1_Sperr_Info_WFS "WFS-Sperrinformation";
CM_ SG_ 1648 MO_Abstellzeit "Abstelldauer nach letztem KL15 aus

Hinweis: 
Ehemaliger Fehlerwert 0xFF wird senderseitig nicht unterstützt. 
Diesen Wert aus Kompatibilitätsgründen nicht neu belegen!";
CM_ SG_ 1648 MO_Abstellzeit_Status "Statusinformation zur Abstellzeit
0: Die dem Status zugeordnete Variable konnte noch nicht berechnet werden. 
1: Die dem Status zugehörige Variable wurde korrekt berechnet. 
2: Der Wert der zugehörigen Variablen ist nur ein Minimalwert. 
3: Der Wert d";
CM_ SG_ 1648 MO_ANC_Kennfeld_Anf "Anforderung ANC Kennfeldumschaltung";
CM_ SG_ 1648 MO_Anzahl_Abgesch_Zyl "Gibt die Anzahl der abgeschalteten Zylinder an. In Übergangszuständen wird der Zielbetriebszustand angezeigt.";
CM_ SG_ 1648 MO_Bremslicht_Reku "Bremslicht (ggf. bei Rekuperation durch E-Motor) wird angesteuert";
CM_ SG_ 1648 MO_Drehzahl_Warnung "Warnhinweis zum Kombi im Fall einer fehlerbehafteten Drehzahlbegrenzung";
CM_ SG_ 1648 MO_EPCL "Die Anforderung der EPC-Lampe vom MSG ans Kombi soll durch das Bus-Signal MO_EPCL gemäß folgender Logik erfolgen:
MO_EPCL = 0 dez -> EPC Lampe aus, kein Text
MO_EPCL = 1 dez -> gelbe EPC-Symbolik, Text „Antrieb: Störung! Bitte Service aufsuchen“
MO_EPC";
CM_ SG_ 1648 MO_Ethanol_BS_Texte "Ethanol Brennstoff-Texte im Kombi

0 = kein Text
1 = E85 Warm_Up
2 = FlexFuel Warnung 3.Stufe (Too cold for ethanol)
3 = Warmfahrempfehlung MQB / FlexFuel Warnung 1.Stufe (Refuel with gasoline)
4 = FlexFuel Warnung 2. Stufe (Refuel with gasoline)
5";
CM_ SG_ 1648 MO_Fahrzeugtyp "Unterscheidet die Fahrzeugtypen bzgl. der Antriebsart";
CM_ SG_ 1648 MO_Fehler_Zylabsch "Fehlerstatus der Funktion Zylinderabschaltung ";
CM_ SG_ 1648 MO_Hybrid_StartStopp_LED "Ansteuerung der Funktions-LED der Hybrid Taste bzw. Start/Stop Deaktivierungstaste.
Der Start/Stopp-Master (derzeit im MSG) (oder ein künftiger Hybrid-Master) soll die Ansteuerung senden.";
CM_ SG_ 1648 MO_max_Ladedruck "maximal möglicher Ladedruck (zur Anpassung des Anzeigebereichs bei absoluter Ladedruckanzeige)";
CM_ SG_ 1648 MO_NMAX_Schaltanzeige "Maximaldrehzahl für Schaltanzeige";
CM_ SG_ 1648 MO_obere_Drehzahlgrenze "obere Drehzahlgrenze des Motors";
CM_ SG_ 1648 MO_StartStopp_PopUp "Das Signal zeigt an, ob der StSt-Status mittels Deaktivierungstaster geändert wurde. Ein Wechsel auf die Werte 01 oder 10 löst im Kombi ein entsprechendes PopUp aus. Bei einem Statuswechsel durch andere Signalquellen (z.B. Charisma, fehlerbedingte Abschal";
CM_ SG_ 1648 MO_Zylabsch_Texte "Zylinderabschaltung mode in Kombi, fuer Zylinderabschaltung";
CM_ SG_ 1648 MO_Zylabsch_Texte_02 "ZAS-Anzeige für den Fahrer im Kombi
0: kein ZAS (generell keinerlei ZAS-Anzeigen)  (Init für nicht ZAS-Motor)
1: ZAS im Vollmotorbetrieb  (Init für ZAS-Motor)
2: ZAS im Abschaltbetrieb: 1 Zyl aktiv
3: ZAS im Abschaltbetrieb: 2 Zyl aktiv
4: ZAS im Abs";

CM_ SG_ 967 MO_E_Mode "Anforderung der E-Mode Statusanzeige";
CM_ SG_ 967 MO_E_Texte "Anforderung von Hinweistexten des E-Systems separat für HEV/BEV bzw. erweiterbar für PHEV";
CM_ SG_ 967 MO_E_Warnungen "Anforderung von Warnanzeigen des E-Systems separat für HEV/BEV bzw. erweiterbar für PHEV";
CM_ SG_ 967 MO_EFLEX_Lampe "Um ein Starten mit E100 zu ermöglichen, wird Kraftstoff ggf. vorgeheizt. Das Signal dient der Anzeige des Heizungsstatus.

Heizung aus -> Lampe aus
Heizung ein -> Lampe ein
Heizung ein und Startversuch -> Lampe blinkend
Heizung nicht möglich -> Lampe";
CM_ SG_ 967 MO_Heissleuchte "Ansteuerung der Kühlwassertemperatur-Heißleuchte (Sensor nur noch am Motorsteuergerät): Temperaturschaltschwellen mit Hysterese (bei VW D1/Colorado Kombi derzeit noch nicht genutzt).";
CM_ SG_ 967 MO_ITM_Warnung_Pumpe "Textanzeige: 'Motor sofort abstellen, geschaltete Wasserpumpe defekt / klemmt'";
CM_ SG_ 967 MO_KJS_nicht_bereit "Dieses Signal zeigen einen Fehler der Kühlerjalousie mit unbekannter Stellung der Lamellen. ";
CM_ SG_ 967 MO_Kuehlerluefter_1 "Ansteuertastverhaeltnis (PWM) der Kuehlerluefterendstufe 1";
CM_ SG_ 967 MO_Kuehlerluefter_2 "Ansteuertastverhaeltnis (PWM) der Kuehlerluefterendstufe 2";
CM_ SG_ 967 MO_Kuehlerluefter_MUX "Multiplexer für das Signal 'MO_Kuehlerlüfter'";
CM_ SG_ 967 MO_OBD2_Lampe "OBD bzw. MIL-Lampe wird vom Motorsteuergerät angesteuert, die Information im Signal GE_OBD_Status wird vom Motorsteuergerät an das Kombi weitergereicht";
CM_ SG_ 967 MO_Oelwarnung_max "Ölstandswarnung mit der Aufforderung zum Ölwechsel.
Hintergrund: Bei Kraftstoffeintrag (B20) ins Öl verbleibt der RME-Anteil irreversibel im Öl.";
CM_ SG_ 967 MO_Partikel_Lampe "Partikelfilter-Lampe wird eingeschaltet";
CM_ SG_ 967 MO_RedFahrleistung_Lampe "Ansteuerung der Turtle-Mode Lampe für E-Traktion Fahrzeuge";
CM_ SG_ 967 MO_Systemlampe "EGas Systemlampe (EPC) oder Vorglühlampe im Kombi, Kombi steuert immer gleiche
LED an, nur über Ziffernblatt wird die EPC von der Vorglühlampe differenziert";
CM_ SG_ 967 MO_Tankdeckel_Lampe "Ansteuerung Tankdeckel-Warnlampe Kombiinstrument (nur Ottomotoren) z.Zt. Vorhalt VW";
CM_ SG_ 967 MO_Text_Motorstart "Anzeigetexte für Start/Stopp und Motor-Start
0xB Fehler_Kupplungsschalter nur für PAG-MLB";
CM_ SG_ 967 MO_Text_Partikelfil_Reg "Über dieses Bit im Kombi wird ein Klartextanzeige erzeugt werden: 'Partikelfilter benötigt Regeneration'.
";
CM_ SG_ 967 MO_Text_Tankdeckelwarn "Textbit der Tankdeckelwarnung, z.Zt. Vorhalt VW";
CM_ SG_ 967 MO_Vorglueh_Lampe "Vorglühlampe im Kombi, Kombi steuert immer gleiche LED an. 
Mit Einführung des Einheits-Kombis sind getrennte Signalwege für Vorglühlampe und EPCL notwendig.";
CM_ SG_ 967 MO_Zustand_HWP "Rückmeldung des  Ansteuerzustand der Hauptwasserpumpe an das Klima-SG .
Der Zustand 'HWP fördert' wird übermittelt, wenn die Schaufeln der Hauptwasserpumpe frei drehen können und die Motordrehzahl und damit die Wasserpumpendrehzahl größer als Null ist. B";
CM_ SG_ 967 OLEV_Oelstand_nicht_vorhanden "Kein aktueller Ölstand vorhanden";
CM_ SG_ 967 OLEV_Systemstoerung "Systemstörung im Ölsystem";
CM_ SG_ 967 WIV_Anzeige_aktiv "Peilstabsanzeigefunktion aktiv";
CM_ SG_ 967 WIV_laufender_Motor "Messung bei laufendem Motor nicht möglich";
CM_ SG_ 967 WIV_nachfuellanzeige_ein "Steuert das Aufblenden der Nachfüllanzeige im Kombi, nach Klemme 15 ein und geöffneter Motorhaube";
CM_ SG_ 967 WIV_nicht_betriebswarm "Motor nicht betriebswarm, Messung ungenau";
CM_ SG_ 967 WIV_Oeldr_Warn_Motor "Löst im Kombiinstrument die rote Prio1-Öldruckwarnung (inkl. 3xBeep) aus.
nur MLB: die Warnauslösung erfolgt nur bei gleichzeitig gesetztem 'WIV_Enable_Oeldr_Motor'";
CM_ SG_ 967 WIV_Oeldyn_avl "Ölstand aus dynamischer Messung vorhanden";
CM_ SG_ 967 WIV_Oelmenge "Ölmenge zwischen Min und Max";
CM_ SG_ 967 WIV_Oelmin_Warn "Signal gibt an wenn der Ölstand die Min-Schwelle unterschritten hat";
CM_ SG_ 967 WIV_Oelstand "8 Segmente zur Balkenanzeige des Ölstands";
CM_ SG_ 967 WIV_Oelstand_nicht_vorhanden "Kein aktueller Ölstand vorhanden";
CM_ SG_ 967 WIV_Oelsystem_aktiv "Gesamtölsystem aktiv (entspricht Ölsensor verbaut) und das Ölstand-Untermenu im MMI aktiv";
CM_ SG_ 967 WIV_Schieflage "Fahrzeug steht nicht waagerecht, Messung ungenau";
CM_ SG_ 967 WIV_Sensorfehler "Ölstand/Öltemperatursensor (TOG) defekt";
CM_ SG_ 967 WIV_Ueberfuell_deaktiv "Unterdrückung der Warnung im Kombi die durch Signal WIV_Ueberfuel_Warn ausgelöst wird";
CM_ SG_ 967 WIV_Ueberfuell_Warn "Ölstand hat die Überfüllschwelle überschritten";
CM_ SG_ 967 WIV_Unterfuell_Warn "Ölstand hat die Unterfüllschwelle unterschritten";

CM_ SG_ 1366 MO_Fahrzeugabstellzeit "Zeit seit letzter Fahrbereitschaft.";
CM_ SG_ 1366 MO_Fahrzeugabstellzeit_Status "Status Fahrzeugabstellzeit";
CM_ SG_ 1366 MO_HV_Auszeit "Zeit seit letzter Hochvoltaktivität.";
CM_ SG_ 1366 MO_HV_Auszeit_Status "Status HV-Auszeit.";
CM_ SG_ 1366 MO_Verbau_StartSys_EM_HV "Signal zeigt an, welche Komponenten des Startsystemes verbaut sind.
Verbau E-Maschine HV";
CM_ SG_ 1366 MO_Verbau_StartSys_EM_MV "Signal zeigt an, welche Komponenten des Startsystemes verbaut sind.
Verbau E-Maschine MV z.B. 48V";
CM_ SG_ 1366 MO_Verbau_StartSys_Q_Diode "Signal zeigt an, welche Komponenten des Startsystemes verbaut sind.
Verbau Q_Diode";
CM_ SG_ 1366 MO_Verbau_StartSys_Ritzelstarter "Signal zeigt an, welche Komponenten des Startsystemes verbaut sind.
Verbau Ritzel Starter";
CM_ SG_ 1366 MO_Verbau_StartSys_RSG_MV "Signal zeigt an, welche Komponenten des Startsystemes verbaut sind.
Verbau Riemen Starter Generator MV z.B. 48V";
CM_ SG_ 1366 MO_Verbau_StartSys_RSG_NV "Signal zeigt an, welche Komponenten des Startsystemes verbaut sind.
Verbau Riemen Starter Generator NV z.B. 12V";
CM_ SG_ 1366 MO_Ziel_SoC_Fremdladung "Auf diesen SoC soll MHEV-Speicher geladen werden, wenn ein Ladegerät erkannt ist.";

CM_ SG_ 1367 AGK_Charisma_FahrPr "Aktuelles Fahrprogramm des Charisma-Teilnehmers Abgasklappen

AGK_Charisma_FahrPr =
0x01 comfort
0x02 auto
0x03 dynamic (Ist-Eigenschaft)";
CM_ SG_ 1367 AGK_Charisma_Status "AGK_Charisma_Status =
0x00 Init
0x01 verfügbar
0x02 nicht verfügbar
0x03 asynchron durch Fahrerwunsch (Teilnehmer-Zustände)
";
CM_ SG_ 1367 MO_Bordnetz_Anf "Das Signal stellt Anforderungen an das Bordnetz:
Initial wird es für die Regeneration in der Abgasnachbehandlung verwendet.";
CM_ SG_ 1367 MO_El_Grundlast_Anf "Anforderung Erzeugung einer elektrischen Grundlast";
CM_ SG_ 1367 Mo_Empf_Red_Genlast "Zur Verbesserung der Motorperformance spricht das Motorsteuergerät eine Empfehlung zur Reduzierung der Generatorlast aus.
Unter Berücksichtigung der Bordnetzstabilität kann das Bordnetzmanagement dieser Empfehlung Folge leisten und auf eine minimal mögli";
CM_ SG_ 1367 MO_FestSpannungsAnf "Anforderung einer ungeregelten Sollspannung vom NVEM";
CM_ SG_ 1367 MO_Freilauf_Charisma_FahrPr "MLBevo: Aktuelles Fahrprogramm des Charisma-Teilnehmers (siehe Systemlastenheft Drive Select)";
CM_ SG_ 1367 MO_Freilauf_Charisma_Status "Charisma Systemstatus des Charisma-Teilnehmers";
CM_ SG_ 1367 MO_Kaltstartleistung_Anf "Motorstartleistungsanforderung basierend auf der gesendeten Kaltstarttemperatur";
CM_ SG_ 1367 MO_Kaltstarttemperatur "Temperatur bei dem Kaltstart erfolgen soll";
CM_ SG_ 1367 MO_Lastabwurf "Übernahme des Signals 'MO7_Lastabwurf' aus PQ-Datenfestlegung";
CM_ SG_ 1367 MO_Strecke_Reg_Anf "Zur Verbesserung des Kat/DPF Heizens und Regenerieren prognostiziert das Motorsteuergerät eine Voraussage in welchen Streckenhorizont eine mögliche Regeneration ansteht.";

CM_ SG_ 269 MO_Drehzahl_01 "Im Fehlerfall wird die Motordrehzahl über die Nockenwellendrehzahl als Ersatzgrösse ausgegeben

Bei Parallelhybrid: Getriebeeingangsdrehzahl (=E-Maschinen Drehzahl)

Hinweis: 
Ehemaliger Fehlerwert 0xFFFF wird senderseitig nicht unterstützt. 
Diesen";
CM_ SG_ 269 MO_Drehzahl_VM "Motordrehzahl des Verbrennungsmotors

für OBD freeze frame

Hinweis: 
Ehemaliger Fehlerwert 0xFFFF wird senderseitig nicht unterstützt. 
Diesen Wert aus Kompatibilitätsgründen nicht neu belegen!";
CM_ SG_ 269 MO_EM1_SollDrehzahl "E-Maschinen Soll-Drehzahl";
CM_ SG_ 269 MO_EM2_SollDrehzahl "E-Maschinen Soll-Drehzahl";
CM_ SG_ 269 MO_erste_Ungenauschwelle "Zusätzliche Ungenauigkeit (zur Grundungenauigkeit). Motormomente ungenau >8% (kleinste Ungenauschwelle)
";
CM_ SG_ 269 MO_HYB_E_Faktor "Signed Nibble, verwendet vom GSG zur Interpolation zwischen VMKennfeld und dem Rekuperations-Grenzkennfeld (negative Werte des E-Faktors) bzw. dem Boost-Grenzkennfeld (positive Werte des E-Faktors).
0000 = VM-Kennfeld (keine Interpolation)
0001..0111 = ";
CM_ SG_ 269 MO_HYB_EMode_Info "Hybrid-Mode der Motorsteuerung zur Beeinflussung der Schaltkennfelder im Getriebe. Nicht-Hybridfahrzeuge senden den Initwert.";
CM_ SG_ 269 MO_HYB_Freigabe_VM_Eingr "Hybridsteuerung zeigt an, ob der VM beim Ankoppeln nicht anbrennen darf bzw. anbrennen soll.
";
CM_ SG_ 269 MO_HYB_Komfortstufe "Hybridsteuerung zeigt Startkomfort(-wunsch) an";
CM_ SG_ 269 MO_HYB_LowSpeedModus "MSG legt fest:
0 = klassisches Ausrollen/Anfahren mit N_mot >= N_Leerlauf_VM
1 = elektr. Ausrollen/Anfahren mit geschl. Triebstrang mit N_mot < N_Leerlauf_VM";
CM_ SG_ 269 MO_HYB_max_ind_VM_Mom_02 "inneres maximal mögliches VM-Moment bei einer Drehzahl (z.B. Rauchbegrenzung oder Fehlerfall).";
CM_ SG_ 269 MO_HYB_Modus_Ankopplung_VM "Hybridsteuerung zeigt an, auf welche Weise  der VM angekoppelt werden soll.";
CM_ SG_ 269 MO_HYB_Schaltverhinderung "Schaltungen werden an den DZ-Grenzen (Nullgas-Schaltdrehzahl und Kickdown-Schaltdrehzahl) ausgeführt.";
CM_ SG_ 269 MO_HYB_Sollstatus_K0 "Zusatzinformation zu MO_HYB_Zielzustand, die den  Zielzustand  mit geschlossener bzw. nicht offener K0  weiter differenziert in  die Unterstatus  'schlupfend 'und 'geschlossen'. Zur  Darstellung von asynchronen Ankopplungsvorgängen wie asynchronem Schmier";
CM_ SG_ 269 MO_HYB_Stoppmodus "Hybridsteuerung zeigt an, auf welche Weise gestoppt werden soll.";
CM_ SG_ 269 MO_HYB_VM_bereit "Hybridspezifisches Signal zum VKM-Status beim Ankoppeln,
VKM ist brennbereit";
CM_ SG_ 269 MO_HYB_VM_Mom_oE_02 "Verbrenner-Fahrmoment abzüglich Verbrenner-Verlustmoment. Vorzeichenbehaftet. Für Benutzung in Getriebe-Schaltstrategie";
CM_ SG_ 269 MO_HYB_Zielzustand "Ziel-Betriebszustand des Hybriden, definiert die gewünschten Status der K0 und der Getriebekupplungen.
Der Zielzustand  gibt dabei u.a. an, ob der VM angekoppelt ist oder nicht. Er beinhaltet nicht die Information, ob der VM tatsächlich einspritzt und an";
CM_ SG_ 269 MO_Luftpfad_Verzugszeit_praed "Aktuelle Verzugszeit des luftführenden Systems im Motor, welche dem Getriebe bereitgestellt wird, um reduzierende Momenteneingriffe einer Hochschaltung entsprechend dieser Zeit zu prädizieren.";
CM_ SG_ 269 MO_Mom_Begr_Fahr "Einheitenloser Wert! Faktor in MO_Faktor_Momente (CAN V6.x) bzw. MO_Faktor_Momente_02 (CAN V7.x und höher) in Motor_Code_01 beachten!

Bei aktueller Drehzahl quasistationär (nach ca. 3…5 s) max. mögliches Getriebeeingangsmoment (Summe aus Verbrennungsmo";
CM_ SG_ 269 MO_Mom_Begr_Schalt "Einheitenloser Wert! Faktor in MO_Faktor_Momente (CAN V6.x) bzw. MO_Faktor_Momente_02 (CAN V7.x/8.x) in Motor_Code_01 beachten!

Bei aktueller Drehzahl kurzfristig (ca. 100..200 ms) für momentenerhöhende Getriebeeingriffe max. zur Verfügung stehendes Ge";
CM_ SG_ 269 MO_Mom_Ist_Summe "Einheitenloser Wert! Faktor in MO_Faktor_Momente_02 in Motor_Code_01 beachten!

Ist-Moment als Summe aus Verbrennungsmotor und E-Motor (bei Hybrid-Konzepten) incl. allen Eingriffen und Korrekturen

In Fahrzeugen mit einer Antriebsachse bzw. mit mechan";
CM_ SG_ 269 MO_Mom_neg_verfuegbar "Einheitenloser Wert! Faktor in MO_Faktor_Momente (CAN V6.x) bzw. MO_Faktor_Momente_02 (CAN V7.x) in Motor_Code_01 beachten!

Bei aktueller Drehzahl im nächsten Task (bei CAN-Übertragung z.B. 10ms) tatsächlich verfügbares negatives Moment (Summe aus Verl";
CM_ SG_ 269 MO_Mom_Schub "Einheitenloser Wert! Faktor in MO_Faktor_Momente_02 in Motor_Code_01 beachten!

Moment das sich einstellt, wenn der Fahrer 0% Fahrpedal gibt; bei konventionellen Projekten = alle Verluste (mechanische Reibung und sonstige Verluste) des Verbrennungsmotor";
CM_ SG_ 269 MO_Mom_Soll_gefiltert "Einheitenloser Wert! Faktor in MO_Faktor_Momente_02 in Motor_Code_01 beachten!

MO_Mom_Soll_Roh nach Fahrverhaltensfilter, begrenzt nach oben mit MO_Mom_Begr_dyn, Einrechnung der plausibilisierten Bremsen-Eingriffe; ohne Getriebe-Schalt-Eingriffe, ohne ";
CM_ SG_ 269 MO_Mom_Soll_Roh "Einheitenloser Wert! Faktor in MO_Faktor_Momente_02 in Motor_Code_01 beachten!

Momentenanforderung aus Fahrpedal bzw. von ACC/GRA bzw. aus dem Leerlaufregler (quasistatischer Anteil) bzw. aus Rekuperationsanforderung; keine Begrenzungen, keine Filterun";
CM_ SG_ 269 MO_Mom_Traegheit_Summe "Einheitenloser Wert! Faktor in MO_Faktor_Momente (CAN V6.x) bzw. MO_Faktor_Momente_02 (CAN V7.x) in Motor_Code_01 beachten!

Moment, das zur Beschleunigung der trägen Massen aufgewendet wird bzw. frei wird; Summen aus Anteilen für Verbrennungsmotor und ";
CM_ SG_ 269 MO_Momentenintegral_02 "100  %  entspricht volle Verfügbarkeit aktuell vorhanden. 0 % entspricht Integral bis Limit gefüllt, erhöhender Eingriff kann aktuell nicht berücksichtigt werden oder aufgrund eines Fehlers nicht verfügbar
";
CM_ SG_ 269 MO_QBit_Drehzahl_01 "AUDI D4: Zykluszeit: 10ms (siehe Zykluszeit schnell/Cycletime Fast)

Achtung:
Reduktion der Zykluszeit Motor_03 auf 10ms geplant.
Projektabhängig soll künftig mit 10ms gesendet werden.
Empfänger die in weiteren Konzern-Projekten eingesetzt werden müs";
CM_ SG_ 269 MO_QBit_Motormomente "AUDI D4: Zykluszeit: 10ms (siehe Zykluszeit schnell/Cycletime Fast)

Ungenaue Momentenangaben, weil die Momente aus Ersatzwerten berechnet wurden (z.B. HFM ausgefallen). Qualifizierungsbit für die Motormomente.

Achtung:
Reduktion der Zykluszeit Moto";
CM_ SG_ 269 MO_Status_Normalbetrieb_01 "Das Motorsteuergerät sendet das Informationsbit, wenn die Initialisierungsphase des Steuergerätes abgeschlossen ist. Zusätzlich muss die Klemme 15 eingeschalten sein und eine applizierbare Mindestdrehzahlschwelle (Kennlinie in Abh. von der Kühlwassertempe";
CM_ SG_ 269 MO_TNW_Max_Strom_Lim "maximal zulässiger HV-Strom, der von dem TNW (Traktionsnetzwandler) im motorischen Betrieb aufgenommen werden darf; Abregelstrom zum Einhalten der HV-Systemgrenzen (Bauteilschutz)";
CM_ SG_ 269 MO_TNW_Min_Strom_Lim "minimal zulässiger HV-Strom, der von dem TNW (Traktionsnetzwandler) im generatorischen Betrieb abgegeben werden darf (betragsmäßig maximal aber i.d.R. negativ, daher ‚Min‘); Abregelstrom zum Einhalten der HV-Systemgrenzen (Bauteilschutz)";
CM_ SG_ 269 Motor_50_BZ "4bit Botschaftszähler, wird mit jeder Sendebotschaft inkrementiert";
CM_ SG_ 269 Motor_50_CRC "Für MLB:
Berechnung siehe Lastenheft 'Kommunikationsabsicherung für FlexRay und CAN'
Ab MQB und MLBevo:
Berechnung siehe Lastenheft 'End-to-End Kommunikationsabsicherung'

Endwerte siehe Begleitdokument 'S-PDU Kennungsfolgen'";

CM_ SG_ 332 CE_FlgLnchCtlPreCnd "Launch Control: status of combustion engine preconditions";
CM_ SG_ 332 FoD_DTC_TSK_ACC "DTC ist entweder bereits eingetragen oder wird eingetragen, sobald die zugehörige FOD Funktion freigeschaltet wird.";
CM_ SG_ 332 FoD_DTC_TSK_GRA "DTC ist entweder bereits eingetragen oder wird eingetragen, sobald die zugehörige FoD Funktion freigeschaltet wird.";
CM_ SG_ 332 ISA_Regelung_aktiv "Signalisiert, dass die Regelung zur Überführung der Fahrzeuggeschwindigkeit auf ein gültiges Tempolimit der Funktion Intelligent Speed Assist (ISA) aktiv ist.";
CM_ SG_ 332 ISA_Status "Signalisiert den Status der Funktion Intelligent Speed Assist (ISA). Der Status zeigt an, ob ISA Tempolimits übernimmt und einregelt. Dabei wird unterschieden, ob es sich um eine globale Aktivierung/Deaktivierung der Funktion, oder um eine temporäre Einsc";
CM_ SG_ 332 ISA_Tempolimitwarnung "Signal zur Ausgabe einer Warnung an den Fahrer, wenn bei aktiviertem Intelligent Speed Assit (ISA) das gültige Tempolimit überschritten wird.";
CM_ SG_ 332 MO_Anforderung_HMS "Halteanforderung vom Motor an HMS";
CM_ SG_ 332 MO_EBoost_verf_praed "Zeigt an, ob für eine im Projekt definierte Zeit (max. 10s) E-Boost in Höhe von EM1_maxPred_Moment verfügbar sein wird.

0 - Init_oder_nicht_verfügbar
1 - EBoost_kurzzeit_verfügbar (~3Sek.)
2 - EBoost_langzeit_verfügbar (~10Sek)";
CM_ SG_ 332 MO_eLaunch_verf "Zeigt an, ob aus Antriebssicht E-Launch verfügbar ist.";
CM_ SG_ 332 MO_EMG_Max_Leistung "zugeteilte elektrische Leistung für den motorischen Betrieb;
elektrische Leistung zur Berechnung eines momentan möglichen maximalen Moments";
CM_ SG_ 332 MO_EMG_Min_Leistung "zugeteilte elektrische Leistung für den generatorischen Betrieb;
elektrische Leistung zur Berechnung eines momentan möglichen minimalen Moments";
CM_ SG_ 332 MO_Fahrbereitschaft "Das Signal MO_Fahrbereitschaft zeigt in mehreren Stufen an, ob der Motor in einem anfahrbereiten Zustand ist.";
CM_ SG_ 332 MO_Freilauf_Info "Freilauf Informationssignal vom Motorsteuergerät zum Getriebesteuergerät. Das Motorsteuergerät kann über dieses Signal den Freilauf freigeben, verhindern bzw. explizit anfordern.";
CM_ SG_ 332 MO_Freilauf_Status "Freilauf-Status-Signal vom Frailauf-Master an aktive Freilauf-Teilnehmer. In diesem Signal zeigt der Freilauf-Master an, welchen aktuellen Status die Freilauf-Betriebsstrategie hat.";
CM_ SG_ 332 MO_Heckspoiler_Anf "Anforderung den Heckspoiler zur Ladeluft- bzw. Motorraumkühlung auszufahren.";
CM_ SG_ 332 MO_Klima_Regelmodus "Anforderung an Klima SG zur Regelungsanpassung der HV Klimakomponenten bei bestimmten Umweltbedingungen";
CM_ SG_ 332 MO_Krit_Heckobjekt "Beschreibt die Kritikalität des hinter einem in der Spur fahrenden Fahrzeuges";
CM_ SG_ 332 MO_Kuppl_betaetigt "Das Motorsteuergerät gibt eine plausibilisierte Information aus, ob die Kupplung betätigt oder nicht betätigt wurde.";
CM_ SG_ 332 MO_LaunchControl "Signalisierung einer verfügbaren LaunchControl Funktion ans Kombiinstrument";
CM_ SG_ 332 MO_MVEM_MaxLeistung_MVVerbrauch "Einzuhaltende Max-Grenze der Leistungsaufnahme bzw. -abgabe der 48V-Verbraucher (inkl 48V-DC/DC-Wandler) im 48V-Netz. Für Begrenzung der Leistungsaufnahme der MV-Verbraucher vorgesehen.

Verbrauch - positiv";
CM_ SG_ 332 MO_MVEM_MinLeistung_MVVerbrauch "Einzuhaltende Min-Grenze der Leistungsaufnahme bzw. -abgabe der 48V-Verbraucher (inkl 48V-DC/DC-Wandler) im 48V-Netz. Für Anforderung einer Leistungsaufnahme der MV-Verbraucher vorgesehen. 
 
Verbrauch - positiv
Rückspeisung - negativ";
CM_ SG_ 332 MO_NGS_Gangpos "Gang- bzw. Neutralinformation des erweiterten Neutralgangsensors. Bedingt durch den eingeschränkten Erfassungssbereich des Sensors sind die Ganginformationen als eingelegt bzw. fast eingelegt/vorausgewählt zu interpretieren (nur Handschalter)";
CM_ SG_ 332 MO_Positionierung_aktiv "Zeigt an, dass die Motorpositionierung mit Hilfe des Riemenstartergenerator momentan aktiv ist.";
CM_ SG_ 332 MO_QBit_Aussen_Temp "QBit der Aussentemperatur. Gesetzt bei Ersatzwert, Init oder Fehler.";
CM_ SG_ 332 MO_QBit_Kuppl_betaetigt "Q - Bit für das Signal Kupplung betätigt";
CM_ SG_ 332 MO_Red_El_Fahrleistung "Anzeige einer eingeschränkten Fahrleistung";
CM_ SG_ 332 MO_Servicemodus "Ausgabe aktiver Service-Mode";
CM_ SG_ 332 MO_Startwunsch "o	Setzen bei Erfüllung der kompletten Fahrerbedienhandlung (z.B. Zündanlasstaster + Bremse + Fahrstufe P/N [klassisch] oder Fahrstufe D/R + Bremse [MEB]), je nach Fahrzeug z.T. bereits vor oder immer erst nach Einschalten der Klemme 15;
o	Rücksetzen bei ";
CM_ SG_ 332 MO_UBE_Hybrid_Reserve "Seitens Antrieb in einem (P)HEV erforderliche Energiereserve der HV-Batterie, die den Fußpunkt der „Usable Battery Energy“ (BMS_UBE) verschiebt. Die Reserve dient der Darstellung von Hybrid-Grundfunktionen (z.B. Start/Stopp, elektrisch Kriechen,usw.) unte";
CM_ SG_ 332 MO_UBE_Reserve "Seitens Antrieb erforderliche Energiereserve der HV-Batterie, die den Fußpunkt der „Usable Battery Energy“ (BMS_UBE) verschiebt. Die Reserve dient der Gewährleistung von Sicherheitsfunktionen und ggf. Emissionierungsmaßnahmen unterhalb des Fahrbetriebs im";
CM_ SG_ 332 MO_Veto_Launchcontrol "Veto des Motor-Steuergeräts bzgl. der Aktivierung der Launch-Control";
CM_ SG_ 332 Motor_54_BZ "4bit Botschaftszähler, wird mit jeder Sendebotschaft inkrementiert";
CM_ SG_ 332 Motor_54_CRC "Für MLB:
Berechnung siehe Lastenheft 'Kommunikationsabsicherung für FlexRay und CAN'
Ab MQB und MLBevo:
Berechnung siehe Lastenheft 'End-to-End Kommunikationsabsicherung'

Endwerte siehe Begleitdokument 'S-PDU Kennungsfolgen'";
CM_ SG_ 332 OBD_Abs_Load_Val "Absolute Load Value

Übertragung von Meßgrößen an das Getriebesteuergerät für Freeze Frame Abspeicherung bei Getriebefehlern

PID $43 Absolute Load Value; 0 .. 25700%  mit 100/255 %/bit";
CM_ SG_ 332 OBD_Abs_Pedal_Pos "Absolute Pedal Position

Übertragung von Meßgrößen an das Getriebesteuergerät für Freeze Frame Abspeicherung bei Getriebefehlern

PID $49 Accelerator Pedal Position D; 0 .. 100% mit 100/255 %/bit";
CM_ SG_ 332 OBD_Abs_Throttle_Pos "Absolute Throttle Position

Übertragung von Meßgrößen an das Getriebesteuergerät für Freeze Frame Abspeicherung bei Getriebefehlern

PID $11 Absolute Throttle Position; 0 .. 100% mit 100/255 %/bit";
CM_ SG_ 332 OBD_Aussen_Temp_gef "Gefilterte Aussentemperatur vom Motor für OBD Funktionen.";
CM_ SG_ 332 OBD_Calc_Load_Val "Calculated Load Value

Übertragung von Meßgrößen an das Getriebesteuergerät für Freeze Frame Abspeicherung bei Getriebefehlern

PID $04 Calculated Load Value; 0 .. 100% mit 100/255 % per bit
";
CM_ SG_ 332 OBD_ClearMem_Inhibit "Bei FSP_Loeschen_zulässig müssen alle OBD-ECUs im Gesamtfahrzeug einen Service 04hex Request (Ereignisspeicher löschen) korrekt ausführen. 

In MLB-, MLBevo-, MQB-Fahrzeugkonzepten muss der MIL-Master/Motorsteuergerät bei Kl.15 ein, projektabhängig, kon";
CM_ SG_ 332 OBD_Driving_Cycle "Signalisierung Driving Cycle Qualifizierung - Trigger Ignition Cycle Counter";
CM_ SG_ 332 OBD_Eng_Cool_Temp "Engine Coolant Temperature

Übertragung von Meßgrößen an das Getriebesteuergerät für Freeze Frame Abspeicherung bei Getriebefehlern

PID $05 Engine Coolant Temperature; -40 .. +215°C mit 1°C/bit und 40°C Offset";
CM_ SG_ 332 OBD_Kaltstart_Denominator "Bestimmte Diagnosen werden nur unter Kaltstartbedingungen durchgeführt, der entsprechende Denominator bei IUMPR-pflichtigen Systemen wird anhand dieses vom MSG gebildeten Signals inkrementiert. (Entspricht EVAP-Denominator)";
CM_ SG_ 332 OBD_Minimum_Trip "Grundlage OBD-Gesetz CCR 1968.2 (d)(4.3) Denominator Specifications
Bildung des General Denominator 'Normed Trip':
 600 sec. (kumulativ) Zeit nach Motorstart
 300 sec. (kumulativ) mit Fahrzeuggeschwindigkeit > 25 mph (40 km/h)
 30 sec. (kontinuierlich";
CM_ SG_ 332 OBD_Normed_Trip "Gesetzlich definierte 'Normed Condition' erfüllt, 'General Denominator' darf erhöht werden";
CM_ SG_ 332 OBD_Sperrung_IUMPR "Wenn der General Denominator auf Grund eines Fehlers in den Eingangsgrößen gesperrt wird, wird diese Information über Bussystem als OBD-Statusinformation OBD_Sperrung_IUMPR für andere OBD-Steuergeräte bereitgestellt. 

Das MSG (MIL-Master) setzt dieses ";
CM_ SG_ 332 OBD_Sperrung_Kaltstart_Denom "Information vom MIL Master, dass die Bildung des EVAP Denominators  im Motor nicht möglich ist und damit der noECM-Denominator gesperrt werden darf.";
CM_ SG_ 332 OBD_Warm_Up_Cycle "Mit dem Warm-Up-Cycle wird der zentrale Verlernzähler vom Gateway inkrementiert";
CM_ SG_ 332 OBDProtocol_req "Der PrimaryOBDECU_MILMaster stellt allen PrimaryOBDECUnoMILMaster über das Bussignal [OBDProtocol_req], das für das Fahrzeug zu verwendende OBD-Diagnoseprotokoll bereit.";
CM_ SG_ 332 TSK_ACC_FoD_Status "Information, ob die TSK-ACC-Funktion freigeschaltet ist oder nicht.";
CM_ SG_ 332 TSK_aktives_System "Anzeige der in der TSK-Längsführung aktiven Funktion";
CM_ SG_ 332 TSK_aktives_System_02 "Anzeige der in der TSK-Längsführung aktiven Funktion";
CM_ SG_ 332 TSK_Anf_Antriebsmoment "Das Signal zeigt an, ob die TSK-Laengsregelung aktuell Antriebsmoment anfordert, zur Verwendung in der ASR/EDS-Funktion";
CM_ SG_ 332 TSK_Einheit_vMax_Fahrerassistenz "Einheit zu Signal TSK_vMax_Fahrerassistenz";
CM_ SG_ 332 TSK_erhoehter_Fahrwiderstand "Rueckmeldung vom Triebstrangkoordinator, dass eine große Reglerdifferenz detektiert wurde. Soll ermoeglichen, einen ggfs. unbekannten Fahrwiderstand am Boden zu erkennen.";
CM_ SG_ 332 TSK_GRA_FoD_Status "Information, ob die TSK-GRA-Funktion freigeschaltet ist oder nicht.";
CM_ SG_ 332 TSK_Status_ARA "Funktionsstatus des Triebstrangkoordinators für den Anhängerrangierassistenten";
CM_ SG_ 332 TSK_Status_EA "Funktionsstatus des Triebstrangkoordinators für den Anforderer Emergency Assist";
CM_ SG_ 332 TSK_Status_IPA "Funktionsstatus des Triebstrangkoordinators für die Längsführung des Einparkassistenten";
CM_ SG_ 332 TSK_Status_PLA "Funktionsstatus des Triebstrangkoordinators für den Speedlimiter des Parkassistenten";
CM_ SG_ 332 TSK_Status_RHP "Functional status of the drive train coordinator for the longitudinal guidance of the rush hour pilot.";
CM_ SG_ 332 TSK_vMax_aktuell "Im aktuellen Betriebszustand global gültige Geschwindigkeitslimitierung.";
CM_ SG_ 332 TSK_vMax_Fahrerassistenz "maximale Sollgeschwindigkeit für GRA/ACC/Limiter
Hinweis: Signal ist mit Signal TSK_Einheit_vMax_Fahrerassistenz zu interpretieren.  Das Signal wird abwechselnd in km/h und mph gesendet.";

CM_ SG_ 553 SOK_Motor_54_Signatur "Signatur im Rahmen der durch SOK geschützten Broadcast-Kommunikation

Geschützte Funktion: ORU
Geschützte Botschaft: Motor_54";

CM_ SG_ 190 MO_CluAxs_Set "Sollzustand der Kupplung an der elektrischen Hinterachse";
CM_ SG_ 190 MO_CluEng_Set "Sollzustand der Trennkupplung im TQ250";
CM_ SG_ 190 MO_DC_Max_Strom_HV "Abregelgrenze: maximal freigegebener Strom auf der Hochvolt-Seite im Tiefsetzbetrieb (Strom aus dem Traktionsnetz ins Bordnetz)";
CM_ SG_ 190 MO_DC_SollSpannung_HV "Sollwert für die Traktionsnetzspannung im Hochsetzbetrieb vom Bordnetz ins Traktionsnetz
vorgehaltenes Signal; wird in PQ35/PL71 nicht berücksichtigt";
CM_ SG_ 190 MO_EM1_AR_Anf "Anforderung der Anti-Ruckel Funktion auf der E-Maschine

0: aus
1: nicht belegt
2: D2T2 Regelung
3: Referenzdrehzahl Regelung
4: interne Referenzdrehzahlregelung";
CM_ SG_ 190 MO_EM1_DynLimit_AR "Auslöseschwelle für dynamische Ruckeldämpfung

Der Momentenwert ergibt sich aus der Multiplikation mit dem Faktor MO_EM1_Faktor_AR_Momente (Skalierung Wertebereich und Auflösung).";
CM_ SG_ 190 MO_EM1_Kp_AR "dynamischer Verstärkungsfaktor zur Umrechnung Drehzahlschwingung in Eingriffsmoment";
CM_ SG_ 190 MO_EM1_Max_Leistung "zugeteilte elektrische Leistung für den motorischen Betrieb; elektrische Leistung zur Berechnung eines momentan möglichen maximalen Moments und einer momentan möglichen maximalen mechanischen Leistung";
CM_ SG_ 190 MO_EM1_Max_Moment "maximal erlaubtes positives (motorisches) Moment der E-Maschine aus Hybridstrategie";
CM_ SG_ 190 MO_EM1_Max_Strom_Lim "maximal zulässiger HV-Strom, der von der LE im motorischen Betrieb aufgenommen werden darf; Abregelstrom zur Begrenzung des maximalen Moments im motorischen Betrieb";
CM_ SG_ 190 MO_EM1_MaxDrehzahl "Maximale E-Maschinen-Drehzahl";
CM_ SG_ 190 MO_EM1_Min_Leistung "zugeteilte elektrische Leistung für den generatorischen Betrieb (betragsmäßig maximal aber i.d.R. negativ, daher ‚Min‘);; elektrische Leistung zur Berechnung eines momentan möglichen minimalen Moments und einer momentan möglichen minimalen mechanischen Le";
CM_ SG_ 190 MO_EM1_Min_Moment "maximal erlaubtes negatives (generatorisches) Moment der E-Maschine aus Hybridstrategie";
CM_ SG_ 190 MO_EM1_Min_Strom_Lim "minimal zulässiger HV-Strom, der von der LE im generatorischen Betrieb abgegeben werden darf (betragsmäßig maximal aber i.d.R. negativ, daher ‚Min‘); Abregelstrom zur Begrenzung des minimalen Moments im generatorischen Betrieb";
CM_ SG_ 190 MO_EM1_MinDrehzahl "Minimale E-Maschinen-Drehzahl";
CM_ SG_ 190 MO_EM1_Periode_AR "Zeitkonstante (Periodendauer) der Ruckelschwingung (abhängig vom Gang und ggf. elektrischem/hybridischem Fahren) ";
CM_ SG_ 190 MO_EM1_Sollmodus "Werte:
  Anforderung der Betriebsart der E-Maschine
0: Standby; Kommunikation aktiv; aktiver Kurzschluss
1: Momentenregelung
2: Drehzahlregelung (interner Regelkreis)
3: Spannungsregelung
4: Drehzahlregelung (externer Regelkreis)
5: nicht verfügbar";
CM_ SG_ 190 MO_EM1_SollMoment "E-Maschinen Soll-Moment vom Hybridcontroller";
CM_ SG_ 190 MO_EM1_SollSpannung "E-Maschinen Soll-Spannung";
CM_ SG_ 190 MO_EM2_AR_Anf "Anforderung der Anti-Ruckel Funktion auf der E-Maschine

0: aus
1: nicht belegt
2: D2T2 Regelung
3: Referenzdrehzahl Regelung
4: interne Referenzdrehzahlregelung";
CM_ SG_ 190 MO_EM2_DynLimit_AR "Auslöseschwelle für dynamische Ruckeldämpfung

Der Momentenwert ergibt sich aus der Multiplikation mit dem Faktor MO_EM2_Faktor_AR_Momente (Skalierung Wertebereich und Auflösung).";
CM_ SG_ 190 MO_EM2_Kp_AR "dynamischer Verstärkungsfaktor zur Umrechnung Drehzahlschwingung in Eingriffsmoment";
CM_ SG_ 190 MO_EM2_Max_Leistung "zugeteilte elektrische Leistung für den motorischen Betrieb; elektrische Leistung zur Berechnung eines momentan möglichen maximalen Moments und einer momentan möglichen maximalen mechanischen Leistung";
CM_ SG_ 190 MO_EM2_Max_Moment "maximal erlaubtes positives (motorisches) Moment der E-Maschine aus Hybridstrategie";
CM_ SG_ 190 MO_EM2_Max_Strom_Lim "maximal zulässiger HV-Strom, der von der LE im motorischen Betrieb aufgenommen werden darf; Abregelstrom zur Begrenzung des maximalen Moments im motorischen Betrieb";
CM_ SG_ 190 MO_EM2_MaxDrehzahl "Maximale E-Maschinen-Drehzahl";
CM_ SG_ 190 MO_EM2_Min_Leistung "zugeteilte elektrische Leistung für den generatorischen Betrieb (betragsmäßig maximal aber i.d.R. negativ, daher ‚Min‘);; elektrische Leistung zur Berechnung eines momentan möglichen minimalen Moments und einer momentan möglichen minimalen mechanischen Le";
CM_ SG_ 190 MO_EM2_Min_Moment "maximal erlaubtes negatives (generatorisches) Moment der E-Maschine aus Hybridstrategie";
CM_ SG_ 190 MO_EM2_Min_Strom_Lim "minimal zulässiger HV-Strom, der von der LE im generatorischen Betrieb abgegeben werden darf (betragsmäßig maximal aber i.d.R. negativ, daher ‚Min‘); Abregelstrom zur Begrenzung des minimalen Moments im generatorischen Betrieb";
CM_ SG_ 190 MO_EM2_MinDrehzahl "Minimale E-Maschinen-Drehzahl";
CM_ SG_ 190 MO_EM2_Periode_AR "Zeitkonstante (Periodendauer) der Ruckelschwingung (abhängig vom Gang und ggf. elektrischem/hybridischem Fahren) ";
CM_ SG_ 190 MO_EM2_Sollmodus "Werte:
  Anforderung der Betriebsart der E-Maschine
0: Standby; Kommunikation aktiv; aktiver Kurzschluss
1: Momentenregelung
2: Drehzahlregelung (interner Regelkreis)
3: Spannungsregelung
4: Drehzahlregelung (externer Regelkreis)
5: nicht verfügbar";
CM_ SG_ 190 MO_EM2_SollMoment "E-Maschinen Soll-Moment vom Hybridcontroller";
CM_ SG_ 190 MO_EM2_SollSpannung "E-Maschinen Soll-Spannung";
CM_ SG_ 190 Motor_56_BZ "4bit Botschaftszähler, wird mit jeder Sendebotschaft inkrementiert";
CM_ SG_ 190 Motor_56_CRC "Für MLB:
Berechnung siehe Lastenheft 'Kommunikationsabsicherung für FlexRay und CAN'
Ab MQB und MLBevo:
Berechnung siehe Lastenheft 'End-to-End Kommunikationsabsicherung'

Endwerte siehe Begleitdokument 'S-PDU Kennungsfolgen'";
CM_ SG_ 190 SOK_MO_SollMoment_Signatur "Signatur im Rahmen der durch SOK geschützen Broadcast-Kommunikation

Geschützte Signale: MO_EM1_SollMoment, MO_EM2_SollMoment";

CM_ SG_ 1601 MO_Ansaugsystem "Art des Ansaugsystems des Verbrennungsmotors";
CM_ SG_ 1601 MO_Anzahl_Zyl "Zylinderzahl des Verbrennungsmotors";
CM_ SG_ 1601 MO_Anzeige_StSt_gueltig "Zeigt die Gültigkeit der neuen StSt-Anzeigesignale an, MO_Anzeige_StSt_Text und  MO_Anzeige_Symbol. Mo_Text_Motorstart 1..5 sind zu ignorieren.";
CM_ SG_ 1601 MO_Code "Motorcodierinformation Version 16 (Details siehe Anhang)";
CM_ SG_ 1601 MO_DPF_verbaut "Verbauinformation Diesel-Partikel-Filter
";
CM_ SG_ 1601 MO_Faktor_Momente_02 "Dieses Signal schaltet den Wertebereich aller Momente vom Motor, Getriebe, TSK, Bremse ... um! Die Momente besitzen somit einen variablen Wertebereich, weil sich durch den Faktor die Momente sowohl in Auflösung als auch Maximalwerten ändert.

0x0 nicht ";
CM_ SG_ 1601 MO_Getriebe_Code "Getriebecodierung des Motors";
CM_ SG_ 1601 MO_Hubraum "Hubraum des Verbrennungsmotors";
CM_ SG_ 1601 MO_Hybridfahrzeug "Anhand dieses Signals plausibilisiert die Lenkhilfe das Bit Fahrbereitschaft.

Im Projekt Cayenne PHEV (und ggf. auch VW526 PHEV) ist aus Gründen der Abwärtskompatibilität der Wert '2' zu senden.";
CM_ SG_ 1601 MO_Kraftstoffart "Primärkraftstoff zum Antrieb des Fahrzeugs";
CM_ SG_ 1601 MO_Leistung "Nennleistung des Verbrennungsmotors

Im reinen E-Fahrzeug (BEV): Ausgabe der elektrischen Systemleistung";
CM_ SG_ 1601 MO_OBD_Typ "Abgastyp OBD
Hinweis: In Fahrzeugen mit dem Zielmarkt China und einer Zertifizierung ab China 6 muss auf dem Signal 'MO_OBD_Typ' der Wert 'US_OBD' gesendet werden.";
CM_ SG_ 1601 MO_StartStopp_Codiert "Funktion StartStopp im aktuellen Klemmenzyklus verbaut";
CM_ SG_ 1601 Motor_Code_01_CRC "Für MLB:
'Berechnung siehe Lastenheft 'Kommunikationsabsicherung für FlexRay und CAN''

Ab MQB und MLBevo:
'Berechnung siehe Lastenheft 'End-to-End Kommunikationsabsicherung''

Endwerte siehe Begleitdokument 'S-PDU Kennungsfolgen'";
CM_ SG_ 1601 TSK_Codierung "Information über den plausibilisierten Codierungszustand des Triebstrangskoordinators auf ACC oder GRA.";

CM_ SG_ 391 EV_Rekuperationsstufe "Im Kombi anzuzeigende Rekuperationsstufe";
CM_ SG_ 391 MO_Drehzahl_VM "Motordrehzahl des Verbrennungsmotors

für OBD freeze frame

Hinweis: 
Ehemaliger Fehlerwert 0xFFFF wird senderseitig nicht unterstützt. 
Diesen Wert aus Kompatibilitätsgründen nicht neu belegen!";
CM_ SG_ 391 MO_Fehler_Notabschaltung_Klima "Das Signal dient der schnellen Abschaltung der Klimakomponenten (EKK, HV-Heizung) durch den HV-Koordinator (MSG) nach einem HV-Interlock Ereignis.";
CM_ SG_ 391 MO_Fehler_NTKreis "Fehlerstatus Niedertemperaturkreis";
CM_ SG_ 391 MO_KLE_FStatus "Fehlerstatus der Kühlerlüfterelektronik";
CM_ SG_ 391 MO_Tankbereitschaft_Status "Meldung der Tankbereitschaft";
CM_ SG_ 391 MO_Tankklappensteuerung "Ansteuerungsanforderung der Tankklappe";
CM_ SG_ 391 MO_Waehlpos "Wählhebelposition (im VW120/7 und MQB BEV ist der Wählhebel am HCAN mit Master Motor-SG angeschlossen)

(wenn das Signal zusätzlich in Botschaft MSG_HYB_03 verortet ist, gilt: Signal nur in der CAN-Welt PQ35/25 zu verwenden, da dort am ACAN die Wählhebe";
CM_ SG_ 391 MO_WH_Texte "Fahrerhinweise für das Kombi";
CM_ SG_ 391 Motor_EV_01_BZ "Fehlende Beschreibung (Import)";
CM_ SG_ 391 Motor_EV_01_CRC "Für MLB:
'Berechnung siehe Lastenheft 'Kommunikationsabsicherung für FlexRay und CAN''

Ab MQB und MLBevo:
'Berechnung siehe Lastenheft 'End-to-End Kommunikationsabsicherung''

Endwerte siehe Begleitdokument 'S-PDU Kennungsfolgen'";

CM_ SG_ 339 MO_ErwGrenzen_Anf "temporäre Anforderung erweiterter Leistungsgrenzen
0 = normaler Betrieb angefordert
1 = erweiterte Leistungsgrenzen angefordert
BMS und EMS liefern ggf. erweiterte Leistungsgrenzen, um VKM-Start auch unter schwierigen Bedingungen gewährleisten zu könne";
CM_ SG_ 339 MO_Fehler_Notentladung_Anf "Aufforderung zur schnellstmöglichen Entladeung des HV-Zwischenkreises aufgrund Crash-Erkennung / Abriss Pilotlinie";
CM_ SG_ 339 MO_HVEM_Eskalation "Eskalationsbit, mit diesem zusammen darf MO_HVEM_MaxLeistung < der minimal angeforderten Leistung sein und ist durch das HVEM durch Ergreifung aller Eskalationsmaßnahmen umzusetzen (Bei neg. Ladebilanz z.B. im Leerlauf nötig, um die HVBatt vor Entladung e";
CM_ SG_ 339 MO_HVEM_MaxLeistung "Maximal zulässige Leistung, die das HVEM einzustellen hat. 
Ohne Eskalationsbit ist diese Anforderung >= der Minimal benötigten Leistung des HVEM

Hinweis: Ehemaliger Fehlerwert 0x1FF wird senderseitig nicht unterstützt. Diesen Wert aus Kompatibilitäts";
CM_ SG_ 339 MO_HVK_AntriebFehlerstatus "aktueller Fehlerstatus des Antriebs
0: Komponente IO (keine HVK relevanter Fehler)
1 - 5: reserve
6: Keine Komponentenfunktion (Aus)
7: Init";
CM_ SG_ 339 MO_HVK_AntriebZustand "Aktueller Zustand des Antriebs:
0 : Antrieb_AUS               
1 : Antrieb_Startphase        
2 : E-Fahren                  
3 : Hybrid-Fahren             
4 : reserve                   
5 : reserve                   
6 : Keine_Komponentenfunktion ";
CM_ SG_ 339 MO_HVK_EmFehlerstatus "aktueller Fehlerstatus des elektrischen Antriebes (E-Maschine und PWR)

0: Komponente IO (keine HVK relevanter Fehler)
1: Eingeschränkter Betrieb wg. Teilbetrieb
2: reserve
3: Eingeschr_KompFkt_Interlock
4 - 5: reserve
6: Keine Komponentenfunktion ";
CM_ SG_ 339 MO_HVK_EmIstzustand "Aktueller Istzustand der Elm_State
0 : HvOff              
1 : HvStbyReq          
2 : HvStbyOk         
3 : HvBattOnReq        
4 : HvBattOnOk       
10 : HvOnIdle          
18 : HvOnDrvReq        
19 : HvOnDrvOk       
20 : HvOnDrvRdy          ";
CM_ SG_ 339 MO_MVK_AntriebFehlerstatus "aktueller Fehlerstatus des Antriebs
0: Komponente IO (keine MVK relevanter Fehler)
1 - 5: reserve
6: Keine Komponentenfunktion (Aus)
7: Init";
CM_ SG_ 339 MO_MVK_AntriebZustand "Aktueller Zustand des Antriebs:
0 : Antrieb_AUS               
1 : Antrieb_Startphase        
2 : FreilaufMotorAus                  
3 : reserve             
4 : reserve                   
5 : reserve                   
6 : Keine_Komponentenfunktio";
CM_ SG_ 339 MO_MVK_Bordnetz_Anf "Explizite Anforderung des Motors zur Aktivierung bzw. Aufrechterhaltung des Mittelvolt-Bordnetzes für die Ausführung von Motorfunktionen";
CM_ SG_ 339 MO_MVK_EmFehlerstatus "aktueller Fehlerstatus der elektrischen Maschine (RSG)

0: Komponente IO (keine MVK relevanter Fehler)
1: Eingeschränkter Betrieb wg. Teilbetrieb
2: reserve
3 - 5: reserve
6: Keine Komponentenfunktion (Aus)
7: Init";
CM_ SG_ 339 MO_MVK_EmIstzustand "Aktueller Istzustand der Elm_State
0 : MvOff              
1 : MvStbyReq          
2 : MvStbyOk         
3 : MvBattOnReq        
4 : MvBattOnOk       
10 : MvOnIdle          
18 : MvOnDrvReq        
19 : MvOnDrvOk       
20 : MvOnDrv           
";
CM_ SG_ 339 MSG_HYB_30_BZ "BZ für die Botschaft MSG_HYB_30";
CM_ SG_ 339 MSG_HYB_30_CRC "CRC für die Botschaft MSG_HYB_30";

CM_ SG_ 931 MVEM_DC_SollLeistung_MV "Soll-Leistung des DC/DC-Wandlers Höherspannungsseitig (48V-seitig).

Hochsetzen - negativ";
CM_ SG_ 931 MVEM_DC_SollSpannung_MV "Soll-Ausgangspannung des DC/DC-Wandlers MV-Spannungssseitig (48V-seitig).";
CM_ SG_ 931 MVEM_EMG_MaxGenSpannung "max. Spannung des 48V-RSG im generatorischen Betrieb.";
CM_ SG_ 931 MVEM_EMG_MaxGenStrom "Maximaler Strom des RSGs im spannungsgeregeltem Betrieb. ";
CM_ SG_ 931 MVEM_IstStrom_MVVerbraucher "Iststrom-Aufnahme der 48V-Verbraucher (inkl 48V-DC/DC-Wandler) im 48V-Netz

Verbrauch - positiv
Rückspeisung - negativ";

CM_ SG_ 2589283456 MVEM_Kaltstart_StuetzLeistung "Maximal verfügbare Stützleistung für den folgenden Motorkaltstart (48V).";
CM_ SG_ 2589283456 MVEM_MO_USoll_Notbetrieb "Im eingeschränkten Betrieb des 48V Systems und Fehlerfälle der 48V Batterie.";
CM_ SG_ 2589283456 MVEM_Umax_Rueckspeisung "Systeme, die rückspeisefähig sind, müssen vor Erreichen der oberen Spannungsgrenze ihren Leistungsbedarf dynamisch abregeln.";
CM_ SG_ 2589283456 MVEM_Umin_Funktionsgruppe_A "Systeme der Funktionsgruppe A müssen bei Unterschreitung der Spannungsgrenze ihren Leistungsbedarf dynamisch abregeln.";
CM_ SG_ 2589283456 MVEM_Umin_Funktionsgruppe_B "Systeme der Funktionsgruppe B müssen bei Unterschreitung der Spannungsgrenze ihren Leistungsbedarf dynamisch abregeln.";
CM_ SG_ 2589283456 MVEM_Umin_Funktionsgruppe_C "Systeme der Funktionsgruppe C müssen bei Unterschreitung der Spannungsgrenze ihren Leistungsbedarf dynamisch abregeln.";

CM_ SG_ 1284 MV_Bordnetz_aktiv "Signalisiert ein aktives MV-Bordnetz. MV-Schütze geschlossen.";
CM_ SG_ 1284 MV_Bordnetz_belastbar "Signalisierung vom MVEM das das 48V Bordnetz vollständig belastbar ist  >5 Watt";
CM_ SG_ 1284 MV_Bordnetz_Fehler "Status ob im  MV-Netz ein Fehler detektiert wurde.";
CM_ SG_ 1284 MVK_01_BZ "4bit Botschaftszähler, wird mit jeder Sendebotschaft inkrementiert";
CM_ SG_ 1284 MVK_01_CRC "Für MLB:
Berechnung siehe Lastenheft 'Kommunikationsabsicherung für FlexRay und CAN'
Ab MQB und MLBevo:
Berechnung siehe Lastenheft 'End-to-End Kommunikationsabsicherung'

Endwerte siehe Begleitdokument 'S-PDU Kennungsfolgen'";
CM_ SG_ 1284 MVK_BMS_Sollmodus "Angeforderter Sollmodus der MV-Batterie:
0 : MV_Off                                
1 : MV_On (HS geschlossen)                
2 : nicht belegbar                        
3 : nicht belegbar                        
4 : nicht belegbar 
5 : nicht belegb";
CM_ SG_ 1284 MVK_BOOST_Sollmodus "Sollmodus eBooster auf 48V
0 : keine Freigabe
1 : Freigabe
2 : nicht belegbar
3 : nicht belegbar
4 : nicht belegbar
5 : nicht belegbar
6 : nicht belegbar
7 : Init   (CAN-Initialisierung)   

Info: 'nicht belegbar' d.h. Sollmodus nicht relevant f";
CM_ SG_ 1284 MVK_DCDC_Sollmodus "angeforderte Soll-Betriebsart des 48V DC/DC-Wandlers: 
0: Standby; Kommunikation aktiv
1: MvOn (48V-Netz ist aktiv)
2: Tiefsetzen (48V --> BN 14,4V)
3: Hochsetzen (BN 14,4V --> 48V)
4: Startunterstuetzung_48V (Stützung des 48V-BN im Startvorgang)
5:";
CM_ SG_ 1284 MVK_DCDC_Sollmodus_02 "Angeforderte Soll-Betriebsart des 48V DC/DC-Wandlers: 
0: Standby; Kommunikation aktiv
1: MvOn (48V-Netz ist aktiv)
2: Tiefsetzen (48V --> BN12)
3: Hochsetzen (BN12 --> 48V)
4: Startunterstuetzung_48V (Stützung des 48V-BN im Startvorgang)
5: nicht v";
CM_ SG_ 1284 MVK_eABC_Sollmodus "Sollmodus eABC auf 48V
0 : keine Freigabe
1 : Freigabe
2 : nicht belegbar
3 : nicht belegbar
4 : nicht belegbar
5 : nicht belegbar
6 : nicht belegbar
7 : Init   (CAN-Initialisierung)   

Info: 'nicht belegbar' d.h. Sollmodus nicht relevant für M";
CM_ SG_ 1284 MVK_eAWS_Sollmodus "Sollmodus eAWS auf 48V
0 : keine Freigabe
1 : Freigabe
2 : nicht belegbar
3 : nicht belegbar
4 : nicht belegbar
5 : nicht belegbar
6 : nicht belegbar
7 : Init   (CAN-Initialisierung)   

Info: 'nicht belegbar' d.h. Sollmodus nicht relevant für M";
CM_ SG_ 1284 MVK_Istmodus_Anf "MVK-Anforderung an alle 48V-Komponenten deren Istmodus im schnellen Zyklus (Inhibitzeit) zu senden.";
CM_ SG_ 1284 MVK_MO_EmSollzustand "Anforderung vom MVK Sollzustand der Elm_State
0 = MvOff              
1 = MvStbyReq          
2 = MvStbyWait         
3 = MvBattOnReq        
4 = MvBattOnWait       
10 = MvOnIdle          
18 = MvOnDrvReq        
19 = MvOnDrvWait       
20 = MvO";
CM_ SG_ 1284 MVK_MV_Batteriewarnung "Kundenwarnung aufgrund eines Batteriefehlers";
CM_ SG_ 1284 MVK_MV_Netz_Warnungen "Anforderung Warnung/Fehler MV-System im Kombi
0: Keine Warnung/Init
1:Anforderung_Anzeige_Warnung_MV-Netz (gelbes Symbol)
2:Anforderung_Anzeige_Fehler_MV-Netz (rotes Symbol)
3:Anforderung_Anzeige_Warnung_Kein_Wiederstart_möglich";
CM_ SG_ 1284 MVK_MVPTC_Sollmodus "Sollmodus MV-PTC
0 : keine Freigabe
1 : Freigabe
2 : nicht belegbar
3 : nicht belegbar
4 : nicht belegbar
5 : nicht belegbar
6 : nicht belegbar
7 : Init   (CAN-Initialisierung)   

Info: 'nicht belegbar' d.h. Sollmodus nicht relevant für MVK";
BA_DEF_REL_ BU_SG_REL_  "GenSigTimeoutTime" INT 0 65535;
BA_DEF_ BO_  "DiagRequest" ENUM "No", "Yes";
BA_DEF_ BO_  "DiagResponse" ENUM "No", "Yes";
BA_DEF_ BO_  "DiagState" ENUM "No", "Yes";
BA_DEF_ BO_  "GenMsgChkConstant" HEX 0 4095;
BA_DEF_ BO_  "GenMsgCycleTime" INT 0 65535;
BA_DEF_ BO_  "GenMsgCycleTimeFast" INT 0 65535;
BA_DEF_ BO_  "GenMsgDelayTime" INT 0 100000;
BA_DEF_ BO_  "GenMsgILSupport" ENUM "No", "Yes";
BA_DEF_ BO_  "GenMsgNrOfRepetition" INT 0 100;
BA_DEF_ BO_  "GenMsgPDUConstants" STRING;
BA_DEF_ BO_  "GenMsgSendType" ENUM "Cyclic", "not_used", "not_used", "not_used", "not_used", "not_used", "not_used", "IfActive", "NoMsgSendType";
BA_DEF_ BO_  "GenMsgStartDelayTime" INT 0 100000;
BA_DEF_ BO_  "NmMessage" ENUM "No", "Yes";
BA_DEF_ BO_  "NmhMessage" ENUM "No", "Yes";
BA_DEF_ BO_  "MsgType" ENUM "Application", "NM ", "NMH", "TP2.0", "ISO-TP ", "BAP", "EID", "KS", "XCP_PRE_CONFIGURED", "XCP_RUNTIME_CONFIGURED";
BA_DEF_ BO_  "VAGTP20_API" HEX 0 255;
BA_DEF_ BO_  "VAGTP20_DynConnection" ENUM "No", "Yes";
BA_DEF_ BO_  "VAGTP20_DynSetup" ENUM "No", "Yes";
BA_DEF_ BO_  "VAGTP20_StatConnection" ENUM "No", "Yes";
BA_DEF_ BO_  "CANFD_BRS" ENUM "0", "1";
BA_DEF_ BO_  "VFrameFormat" ENUM "StandardCAN", "ExtendedCAN", "reserved", "reserved", "reserved", "reserved", "reserved", "reserved", "reserved", "reserved", "reserved", "reserved", "reserved", "reserved", "StandardCAN_FD", "ExtendedCAN_FD";
BA_DEF_ SG_  "GenSigActiveRepetitions" INT -2147483648 2147483647;
BA_DEF_ SG_  "GenSigInactiveValue" INT -2147483648 2147483647;
BA_DEF_ SG_  "GenSigSendType" ENUM "Cyclic", "OnWrite", "OnWriteWithRepetition", "OnChange", "OnChangeWithRepetition", "IfActive", "IfActiveWithRepetition", "NoSigSendType", "OnChangeAndIfActive", "OnChangeAndIfActiveWithRepetition";
BA_DEF_ SG_  "GenSigStartValue" INT -2147483648 2147483647;
BA_DEF_ SG_  "NWM-WakeupAllowed" ENUM "No", "Yes";
BA_DEF_ SG_  "GenSigFuncType" ENUM "NoFunction", "MsgCounter", "CRC-8", "XOR", "XOR-2", "DatedBit", "SW-Kl15", "CHK", "Constant", "Protocol", "CRC-8-SAE_J1850", "CRC-32", "DataLength", "DataID", "MsgCounter16", "SOK-Signatur", "Cluster";
BA_DEF_ SG_  "GenSigSwitchedByIgnition" ENUM "No", "Yes";
BA_DEF_ SG_  "Fehlerwert" HEX 0 2147483647;
BA_DEF_ SG_  "GenSigMissingSourceValue" HEX 0 2147483647;
BA_DEF_DEF_REL_  "GenSigTimeoutTime" 0;
BA_DEF_DEF_  "DiagRequest" "No";
BA_DEF_DEF_  "DiagResponse" "No";
BA_DEF_DEF_  "DiagState" "No";
BA_DEF_DEF_  "GenMsgChkConstant" 0;
BA_DEF_DEF_  "GenMsgCycleTime" 0;
BA_DEF_DEF_  "GenMsgCycleTimeFast" 0;
BA_DEF_DEF_  "GenMsgDelayTime" 0;
BA_DEF_DEF_  "GenMsgILSupport" "No";
BA_DEF_DEF_  "GenMsgNrOfRepetition" 0;
BA_DEF_DEF_  "GenMsgPDUConstants" "";
BA_DEF_DEF_  "GenMsgSendType" "NoMsgSendType";
BA_DEF_DEF_  "GenMsgStartDelayTime" 0;
BA_DEF_DEF_  "NmMessage" "No";
BA_DEF_DEF_  "NmhMessage" "No";
BA_DEF_DEF_  "MsgType" "Application";
BA_DEF_DEF_  "VAGTP20_API" 0;
BA_DEF_DEF_  "VAGTP20_DynConnection" "No";
BA_DEF_DEF_  "VAGTP20_DynSetup" "No";
BA_DEF_DEF_  "VAGTP20_StatConnection" "No";
BA_DEF_DEF_  "CANFD_BRS" "1";
BA_DEF_DEF_  "VFrameFormat" "StandardCAN";
BA_DEF_DEF_  "GenSigActiveRepetitions" 0;
BA_DEF_DEF_  "GenSigInactiveValue" 0;
BA_DEF_DEF_  "GenSigSendType" "NoSigSendType";
BA_DEF_DEF_  "GenSigStartValue" 0;
BA_DEF_DEF_  "NWM-WakeupAllowed" "No";
BA_DEF_DEF_  "GenSigFuncType" "NoFunction";
BA_DEF_DEF_  "GenSigSwitchedByIgnition" "Yes";
BA_DEF_DEF_  "Fehlerwert" 0;
BA_DEF_DEF_  "GenSigMissingSourceValue" 0;
BA_ "GenMsgCycleTime" BO_ 958 100;
BA_ "GenMsgDelayTime" BO_ 958 10;
BA_ "GenMsgILSupport" BO_ 958 1;
BA_ "GenMsgPDUConstants" BO_ 958 "0x1f,0x28,0xc6,0x85,0xe6,0xf8,0xb0,0x19,0x5b,0x64,0x35,0x21,0xe4,0xf7,0x9c,0x24";
BA_ "GenMsgSendType" BO_ 958 0;
BA_ "VFrameFormat" BO_ 958 14;
BA_ "GenMsgCycleTime" BO_ 1631 500;
BA_ "GenMsgILSupport" BO_ 1631 1;
BA_ "GenMsgSendType" BO_ 1631 0;
BA_ "VFrameFormat" BO_ 1631 14;
BA_ "GenMsgCycleTime" BO_ 1648 500;
BA_ "GenMsgDelayTime" BO_ 1648 20;
BA_ "GenMsgILSupport" BO_ 1648 1;
BA_ "GenMsgSendType" BO_ 1648 0;
BA_ "VFrameFormat" BO_ 1648 14;
BA_ "GenMsgCycleTime" BO_ 967 100;
BA_ "GenMsgILSupport" BO_ 967 1;
BA_ "GenMsgSendType" BO_ 967 0;
BA_ "VFrameFormat" BO_ 967 14;
BA_ "GenMsgCycleTime" BO_ 1366 1000;
BA_ "GenMsgILSupport" BO_ 1366 1;
BA_ "GenMsgSendType" BO_ 1366 0;
BA_ "VFrameFormat" BO_ 1366 14;
BA_ "GenMsgCycleTime" BO_ 1367 500;
BA_ "GenMsgDelayTime" BO_ 1367 50;
BA_ "GenMsgILSupport" BO_ 1367 1;
BA_ "GenMsgSendType" BO_ 1367 0;
BA_ "VFrameFormat" BO_ 1367 14;
BA_ "GenMsgCycleTime" BO_ 269 10;
BA_ "GenMsgILSupport" BO_ 269 1;
BA_ "GenMsgPDUConstants" BO_ 269 "0x0f,0x67,0x6e,0x8a,0xa9,0xae,0x23,0x22,0x77,0x4d,0xf9,0xd0,0x81,0x51,0x9c,0x80";
BA_ "GenMsgSendType" BO_ 269 0;
BA_ "VFrameFormat" BO_ 269 14;
BA_ "GenMsgCycleTime" BO_ 332 100;
BA_ "GenMsgDelayTime" BO_ 332 10;
BA_ "GenMsgILSupport" BO_ 332 1;
BA_ "GenMsgPDUConstants" BO_ 332 "0x16,0x35,0x59,0x15,0x9a,0x2a,0x97,0xb8,0x0e,0x4e,0x30,0xcc,0xb3,0x07,0x01,0xad";
BA_ "GenMsgSendType" BO_ 332 0;
BA_ "VFrameFormat" BO_ 332 14;
BA_ "GenMsgCycleTime" BO_ 553 100;
BA_ "GenMsgDelayTime" BO_ 553 10;
BA_ "GenMsgSendType" BO_ 553 0;
BA_ "VFrameFormat" BO_ 553 14;
BA_ "GenMsgCycleTime" BO_ 190 10;
BA_ "GenMsgILSupport" BO_ 190 1;
BA_ "GenMsgPDUConstants" BO_ 190 "0x18,0x71,0x10,0x8d,0xd7,0xaa,0xb0,0x78,0xac,0x12,0xae,0x0c,0xdd,0xf1,0x85,0x68";
BA_ "GenMsgSendType" BO_ 190 0;
BA_ "VFrameFormat" BO_ 190 14;
BA_ "GenMsgChkConstant" BO_ 1601 71;
BA_ "GenMsgCycleTime" BO_ 1601 1000;
BA_ "GenMsgILSupport" BO_ 1601 1;
BA_ "GenMsgPDUConstants" BO_ 1601 "0x47,0x47,0x47,0x47,0x47,0x47,0x47,0x47,0x47,0x47,0x47,0x47,0x47,0x47,0x47,0x47";
BA_ "GenMsgSendType" BO_ 1601 0;
BA_ "VFrameFormat" BO_ 1601 14;
BA_ "GenMsgCycleTime" BO_ 391 100;
BA_ "GenMsgDelayTime" BO_ 391 40;
BA_ "GenMsgILSupport" BO_ 391 1;
BA_ "GenMsgPDUConstants" BO_ 391 "0x7f,0xed,0x17,0xc2,0x7c,0xeb,0x44,0x21,0x01,0xfa,0xdb,0x15,0x4a,0x6b,0x23,0x05";
BA_ "GenMsgSendType" BO_ 391 0;
BA_ "VFrameFormat" BO_ 391 14;
BA_ "GenMsgCycleTime" BO_ 339 200;
BA_ "GenMsgDelayTime" BO_ 339 10;
BA_ "GenMsgILSupport" BO_ 339 1;
BA_ "GenMsgPDUConstants" BO_ 339 "0x03,0x13,0x23,0x7a,0x40,0x51,0x68,0xba,0xa8,0xbe,0x55,0x02,0x11,0x31,0x76,0xec";
BA_ "GenMsgSendType" BO_ 339 0;
BA_ "VFrameFormat" BO_ 339 14;
BA_ "GenMsgCycleTime" BO_ 931 100;
BA_ "GenMsgILSupport" BO_ 931 1;
BA_ "GenMsgSendType" BO_ 931 0;
BA_ "GenMsgStartDelayTime" BO_ 931 10;
BA_ "VFrameFormat" BO_ 931 14;
BA_ "GenMsgCycleTime" BO_ 2589283456 500;
BA_ "GenMsgILSupport" BO_ 2589283456 1;
BA_ "GenMsgSendType" BO_ 2589283456 0;
BA_ "VFrameFormat" BO_ 2589283456 15;
BA_ "GenMsgCycleTime" BO_ 1284 100;
BA_ "GenMsgDelayTime" BO_ 1284 10;
BA_ "GenMsgILSupport" BO_ 1284 1;
BA_ "GenMsgPDUConstants" BO_ 1284 "0x03,0x63,0x3e,0x04,0xf9,0xb4,0x4f,0x32,0x25,0x56,0x1e,0xc1,0x83,0xfa,0x31,0x97";
BA_ "GenMsgSendType" BO_ 1284 0;
BA_ "VFrameFormat" BO_ 1284 14;
BA_ "GenSigSendType" SG_ 958 MO_Aussp_Anlass 3;
BA_ "GenSigSwitchedByIgnition" SG_ 958 MO_Aussp_Anlass 0;
BA_ "GenSigSendType" SG_ 958 MO_BKV_Unterdruckwarnung 0;
BA_ "GenSigSwitchedByIgnition" SG_ 958 MO_BKV_Unterdruckwarnung 0;
BA_ "GenSigSendType" SG_ 958 MO_BLS 3;
BA_ "GenSigSwitchedByIgnition" SG_ 958 MO_BLS 0;
BA_ "GenSigSendType" SG_ 958 MO_BMS_NV_Anf_stuetzen 3;
BA_ "GenSigSwitchedByIgnition" SG_ 958 MO_BMS_NV_Anf_stuetzen 0;
BA_ "GenSigSendType" SG_ 958 MO_EKlKomLeiRed 0;
BA_ "GenSigSwitchedByIgnition" SG_ 958 MO_EKlKomLeiRed 0;
BA_ "GenSigSendType" SG_ 958 MO_Ext_E_Fahrt_aktiv 3;
BA_ "NWM-WakeupAllowed" SG_ 958 MO_Ext_E_Fahrt_aktiv 1;
BA_ "GenSigSwitchedByIgnition" SG_ 958 MO_Ext_E_Fahrt_aktiv 0;
BA_ "GenSigSendType" SG_ 958 MO_Fahrer_bremst 3;
BA_ "GenSigSwitchedByIgnition" SG_ 958 MO_Fahrer_bremst 0;
BA_ "GenSigSendType" SG_ 958 MO_FMAus_aktiv 3;
BA_ "GenSigSwitchedByIgnition" SG_ 958 MO_FMAus_aktiv 0;
BA_ "GenSigSendType" SG_ 958 MO_FMAus_Startvariante 3;
BA_ "GenSigSwitchedByIgnition" SG_ 958 MO_FMAus_Startvariante 0;
BA_ "GenSigSendType" SG_ 958 MO_Freig_Anlass 3;
BA_ "GenSigSwitchedByIgnition" SG_ 958 MO_Freig_Anlass 0;
BA_ "GenSigSendType" SG_ 958 MO_Freig_Reku 0;
BA_ "GenSigSwitchedByIgnition" SG_ 958 MO_Freig_Reku 0;
BA_ "GenSigSendType" SG_ 958 MO_Freigabe_Segeln 0;
BA_ "GenSigSwitchedByIgnition" SG_ 958 MO_Freigabe_Segeln 0;
BA_ "GenSigSendType" SG_ 958 MO_Gangposition 3;
BA_ "GenSigStartValue" SG_ 958 MO_Gangposition 14;
BA_ "GenSigSwitchedByIgnition" SG_ 958 MO_Gangposition 0;
BA_ "Fehlerwert" SG_ 958 MO_Gangposition 15;
BA_ "GenSigSendType" SG_ 958 MO_Handshake_STH 0;
BA_ "GenSigSwitchedByIgnition" SG_ 958 MO_Handshake_STH 0;
BA_ "GenSigSendType" SG_ 958 MO_HYB_Fahrbereitschaft 0;
BA_ "GenSigSwitchedByIgnition" SG_ 958 MO_HYB_Fahrbereitschaft 0;
BA_ "GenSigSendType" SG_ 958 MO_HYB_VM_aktiv 3;
BA_ "GenSigSwitchedByIgnition" SG_ 958 MO_HYB_VM_aktiv 0;
BA_ "GenSigSendType" SG_ 958 MO_Interlock 3;
BA_ "GenSigSwitchedByIgnition" SG_ 958 MO_Interlock 0;
BA_ "GenSigSendType" SG_ 958 MO_Kickdown 3;
BA_ "GenSigSwitchedByIgnition" SG_ 958 MO_Kickdown 0;
BA_ "GenSigSendType" SG_ 958 MO_Kl_50 3;
BA_ "GenSigSwitchedByIgnition" SG_ 958 MO_Kl_50 0;
BA_ "GenSigSendType" SG_ 958 MO_Kl_75 3;
BA_ "GenSigSwitchedByIgnition" SG_ 958 MO_Kl_75 0;
BA_ "GenSigSendType" SG_ 958 MO_Klima_Eingr 3;
BA_ "GenSigSwitchedByIgnition" SG_ 958 MO_Klima_Eingr 0;
BA_ "GenSigSendType" SG_ 958 MO_Konsistenz_Bremsped 3;
BA_ "GenSigSwitchedByIgnition" SG_ 958 MO_Konsistenz_Bremsped 0;
BA_ "GenSigSendType" SG_ 958 MO_Kuppl_schalter 3;
BA_ "GenSigSwitchedByIgnition" SG_ 958 MO_Kuppl_schalter 0;
BA_ "GenSigSendType" SG_ 958 MO_Motor_laeuft 3;
BA_ "GenSigSwitchedByIgnition" SG_ 958 MO_Motor_laeuft 0;
BA_ "GenSigSendType" SG_ 958 MO_PTC_Status 0;
BA_ "GenSigSwitchedByIgnition" SG_ 958 MO_PTC_Status 0;
BA_ "GenSigSendType" SG_ 958 MO_QBit_Fahrer_bremst 3;
BA_ "GenSigStartValue" SG_ 958 MO_QBit_Fahrer_bremst 1;
BA_ "GenSigSwitchedByIgnition" SG_ 958 MO_QBit_Fahrer_bremst 0;
BA_ "GenSigSendType" SG_ 958 MO_QBit_Gangposition 3;
BA_ "GenSigStartValue" SG_ 958 MO_QBit_Gangposition 1;
BA_ "GenSigSwitchedByIgnition" SG_ 958 MO_QBit_Gangposition 0;
BA_ "GenSigSendType" SG_ 958 MO_QBit_KL_75 3;
BA_ "GenSigStartValue" SG_ 958 MO_QBit_KL_75 1;
BA_ "GenSigSwitchedByIgnition" SG_ 958 MO_QBit_KL_75 0;
BA_ "GenSigSendType" SG_ 958 MO_Remotestart_Betrieb 3;
BA_ "GenSigSwitchedByIgnition" SG_ 958 MO_Remotestart_Betrieb 0;
BA_ "GenSigSendType" SG_ 958 MO_Remotestart_moeglich 0;
BA_ "GenSigSwitchedByIgnition" SG_ 958 MO_Remotestart_moeglich 0;
BA_ "GenSigSendType" SG_ 958 MO_Signalquelle_Gangposition 0;
BA_ "GenSigSwitchedByIgnition" SG_ 958 MO_Signalquelle_Gangposition 0;
BA_ "GenSigSendType" SG_ 958 MO_StartStopp_Fahrerwunsch 0;
BA_ "GenSigSwitchedByIgnition" SG_ 958 MO_StartStopp_Fahrerwunsch 0;
BA_ "GenSigSendType" SG_ 958 MO_StartStopp_Motorstopp 3;
BA_ "GenSigSwitchedByIgnition" SG_ 958 MO_StartStopp_Motorstopp 0;
BA_ "GenSigSendType" SG_ 958 MO_StartStopp_Status 0;
BA_ "GenSigSwitchedByIgnition" SG_ 958 MO_StartStopp_Status 0;
BA_ "GenSigSendType" SG_ 958 MO_StartStopp_Wiederstart 3;
BA_ "GenSigSwitchedByIgnition" SG_ 958 MO_StartStopp_Wiederstart 0;
BA_ "GenSigSendType" SG_ 958 MO_StartVorauss_erfuellt 3;
BA_ "GenSigStartValue" SG_ 958 MO_StartVorauss_erfuellt 1;
BA_ "GenSigSwitchedByIgnition" SG_ 958 MO_StartVorauss_erfuellt 0;
BA_ "GenSigSendType" SG_ 958 MO_Timeout_ESP 3;
BA_ "GenSigSwitchedByIgnition" SG_ 958 MO_Timeout_ESP 0;
BA_ "GenSigSendType" SG_ 958 MO_Zylinderabschaltung 3;
BA_ "GenSigSwitchedByIgnition" SG_ 958 MO_Zylinderabschaltung 0;
BA_ "GenSigSendType" SG_ 958 Motor_14_BZ 0;
BA_ "GenSigFuncType" SG_ 958 Motor_14_BZ 1;
BA_ "GenSigSwitchedByIgnition" SG_ 958 Motor_14_BZ 0;
BA_ "GenSigSendType" SG_ 958 Motor_14_CRC 0;
BA_ "GenSigFuncType" SG_ 958 Motor_14_CRC 2;
BA_ "GenSigSwitchedByIgnition" SG_ 958 Motor_14_CRC 0;
BA_ "GenSigSendType" SG_ 1631 MO_Anzeige_Kaltleuchte 0;
BA_ "GenSigSwitchedByIgnition" SG_ 1631 MO_Anzeige_Kaltleuchte 0;
BA_ "GenSigSendType" SG_ 1631 MO_DPF_reg 0;
BA_ "GenSigSwitchedByIgnition" SG_ 1631 MO_DPF_reg 0;
BA_ "GenSigSendType" SG_ 1631 MO_Energieinhalt_BMS 0;
BA_ "GenSigStartValue" SG_ 1631 MO_Energieinhalt_BMS 4094;
BA_ "GenSigSwitchedByIgnition" SG_ 1631 MO_Energieinhalt_BMS 0;
BA_ "Fehlerwert" SG_ 1631 MO_Energieinhalt_BMS 4095;
BA_ "GenSigSendType" SG_ 1631 MO_Heizstrom_EKAT 0;
BA_ "GenSigSwitchedByIgnition" SG_ 1631 MO_Heizstrom_EKAT 0;
BA_ "Fehlerwert" SG_ 1631 MO_Heizstrom_EKAT 127;
BA_ "GenSigSendType" SG_ 1631 MO_Heizstrom_SCR 0;
BA_ "GenSigSwitchedByIgnition" SG_ 1631 MO_Heizstrom_SCR 0;
BA_ "Fehlerwert" SG_ 1631 MO_Heizstrom_SCR 63;
BA_ "GenSigSendType" SG_ 1631 MO_P_Generator_ungefiltert_Anf 0;
BA_ "GenSigSwitchedByIgnition" SG_ 1631 MO_P_Generator_ungefiltert_Anf 0;
BA_ "GenSigSendType" SG_ 1631 MO_SpannungsAnf_02 0;
BA_ "GenSigSwitchedByIgnition" SG_ 1631 MO_SpannungsAnf_02 0;
BA_ "GenSigSendType" SG_ 1631 TSK_Fahrzeugmasse_02 0;
BA_ "GenSigSwitchedByIgnition" SG_ 1631 TSK_Fahrzeugmasse_02 0;
BA_ "Fehlerwert" SG_ 1631 TSK_Fahrzeugmasse_02 255;
BA_ "GenSigSendType" SG_ 1631 TSK_Grundmasse 0;
BA_ "GenSigSwitchedByIgnition" SG_ 1631 TSK_Grundmasse 0;
BA_ "GenSigSendType" SG_ 1631 TSK_QBit_Fahrzeugmasse 0;
BA_ "GenSigStartValue" SG_ 1631 TSK_QBit_Fahrzeugmasse 1;
BA_ "GenSigSwitchedByIgnition" SG_ 1631 TSK_QBit_Fahrzeugmasse 0;
BA_ "GenSigSendType" SG_ 1631 TSK_QBit_Steigung 0;
BA_ "GenSigStartValue" SG_ 1631 TSK_QBit_Steigung 1;
BA_ "GenSigSwitchedByIgnition" SG_ 1631 TSK_QBit_Steigung 0;
BA_ "GenSigSendType" SG_ 1631 TSK_Steigung_02 0;
BA_ "GenSigSwitchedByIgnition" SG_ 1631 TSK_Steigung_02 0;
BA_ "Fehlerwert" SG_ 1631 TSK_Steigung_02 255;
BA_ "GenSigSendType" SG_ 1648 MO1_Freigabe_Info_WFS 3;
BA_ "GenSigSwitchedByIgnition" SG_ 1648 MO1_Freigabe_Info_WFS 0;
BA_ "GenSigSendType" SG_ 1648 MO1_Freigabe_Verfallsinfo_WFS 3;
BA_ "GenSigSwitchedByIgnition" SG_ 1648 MO1_Freigabe_Verfallsinfo_WFS 0;
BA_ "GenSigSendType" SG_ 1648 MO1_Sperr_Info_WFS 3;
BA_ "GenSigSwitchedByIgnition" SG_ 1648 MO1_Sperr_Info_WFS 0;
BA_ "GenSigSendType" SG_ 1648 MO_Abstellzeit 0;
BA_ "GenSigStartValue" SG_ 1648 MO_Abstellzeit 254;
BA_ "GenSigSwitchedByIgnition" SG_ 1648 MO_Abstellzeit 0;
BA_ "GenSigSendType" SG_ 1648 MO_Abstellzeit_Status 0;
BA_ "GenSigSwitchedByIgnition" SG_ 1648 MO_Abstellzeit_Status 0;
BA_ "GenSigSendType" SG_ 1648 MO_ANC_Kennfeld_Anf 3;
BA_ "GenSigSwitchedByIgnition" SG_ 1648 MO_ANC_Kennfeld_Anf 0;
BA_ "GenSigSendType" SG_ 1648 MO_Anzahl_Abgesch_Zyl 3;
BA_ "GenSigSwitchedByIgnition" SG_ 1648 MO_Anzahl_Abgesch_Zyl 0;
BA_ "GenSigSendType" SG_ 1648 MO_Bremslicht_Reku 3;
BA_ "GenSigSwitchedByIgnition" SG_ 1648 MO_Bremslicht_Reku 0;
BA_ "GenSigSendType" SG_ 1648 MO_Drehzahl_Warnung 0;
BA_ "GenSigSwitchedByIgnition" SG_ 1648 MO_Drehzahl_Warnung 0;
BA_ "GenSigSendType" SG_ 1648 MO_EPCL 3;
BA_ "GenSigSwitchedByIgnition" SG_ 1648 MO_EPCL 0;
BA_ "GenSigSendType" SG_ 1648 MO_Ethanol_BS_Texte 0;
BA_ "GenSigSwitchedByIgnition" SG_ 1648 MO_Ethanol_BS_Texte 0;
BA_ "GenSigSendType" SG_ 1648 MO_Fahrzeugtyp 0;
BA_ "GenSigFuncType" SG_ 1648 MO_Fahrzeugtyp 8;
BA_ "GenSigSwitchedByIgnition" SG_ 1648 MO_Fahrzeugtyp 0;
BA_ "GenSigSendType" SG_ 1648 MO_Fehler_Zylabsch 0;
BA_ "GenSigSwitchedByIgnition" SG_ 1648 MO_Fehler_Zylabsch 0;
BA_ "GenSigSendType" SG_ 1648 MO_Hybrid_StartStopp_LED 3;
BA_ "GenSigSwitchedByIgnition" SG_ 1648 MO_Hybrid_StartStopp_LED 0;
BA_ "GenSigSendType" SG_ 1648 MO_max_Ladedruck 0;
BA_ "GenSigFuncType" SG_ 1648 MO_max_Ladedruck 8;
BA_ "GenSigSwitchedByIgnition" SG_ 1648 MO_max_Ladedruck 0;
BA_ "GenSigSendType" SG_ 1648 MO_NMAX_Schaltanzeige 3;
BA_ "GenSigSwitchedByIgnition" SG_ 1648 MO_NMAX_Schaltanzeige 0;
BA_ "GenSigSendType" SG_ 1648 MO_obere_Drehzahlgrenze 0;
BA_ "GenSigSwitchedByIgnition" SG_ 1648 MO_obere_Drehzahlgrenze 0;
BA_ "GenSigSendType" SG_ 1648 MO_StartStopp_PopUp 3;
BA_ "GenSigSwitchedByIgnition" SG_ 1648 MO_StartStopp_PopUp 0;
BA_ "GenSigSendType" SG_ 1648 MO_Zylabsch_Texte 0;
BA_ "GenSigSwitchedByIgnition" SG_ 1648 MO_Zylabsch_Texte 0;
BA_ "GenSigSendType" SG_ 1648 MO_Zylabsch_Texte_02 3;
BA_ "GenSigSwitchedByIgnition" SG_ 1648 MO_Zylabsch_Texte_02 0;
BA_ "GenSigSendType" SG_ 967 MO_E_Mode 0;
BA_ "GenSigSwitchedByIgnition" SG_ 967 MO_E_Mode 0;
BA_ "GenSigSendType" SG_ 967 MO_E_Texte 0;
BA_ "GenSigSwitchedByIgnition" SG_ 967 MO_E_Texte 0;
BA_ "GenSigSendType" SG_ 967 MO_E_Warnungen 0;
BA_ "GenSigSwitchedByIgnition" SG_ 967 MO_E_Warnungen 0;
BA_ "GenSigSendType" SG_ 967 MO_EFLEX_Lampe 0;
BA_ "GenSigSwitchedByIgnition" SG_ 967 MO_EFLEX_Lampe 0;
BA_ "GenSigSendType" SG_ 967 MO_Heissleuchte 0;
BA_ "GenSigSwitchedByIgnition" SG_ 967 MO_Heissleuchte 0;
BA_ "GenSigSendType" SG_ 967 MO_ITM_Warnung_Pumpe 0;
BA_ "GenSigSwitchedByIgnition" SG_ 967 MO_ITM_Warnung_Pumpe 0;
BA_ "GenSigSendType" SG_ 967 MO_KJS_nicht_bereit 0;
BA_ "GenSigSwitchedByIgnition" SG_ 967 MO_KJS_nicht_bereit 0;
BA_ "Fehlerwert" SG_ 967 MO_KJS_nicht_bereit 1;
BA_ "GenSigStartValue" SG_ 967 MO_Kuehlerluefter_1 126;
BA_ "GenSigSwitchedByIgnition" SG_ 967 MO_Kuehlerluefter_1 0;
BA_ "Fehlerwert" SG_ 967 MO_Kuehlerluefter_1 127;
BA_ "GenSigStartValue" SG_ 967 MO_Kuehlerluefter_2 126;
BA_ "GenSigSwitchedByIgnition" SG_ 967 MO_Kuehlerluefter_2 0;
BA_ "Fehlerwert" SG_ 967 MO_Kuehlerluefter_2 127;
BA_ "GenSigSendType" SG_ 967 MO_Kuehlerluefter_MUX 0;
BA_ "GenSigSwitchedByIgnition" SG_ 967 MO_Kuehlerluefter_MUX 0;
BA_ "GenSigSendType" SG_ 967 MO_OBD2_Lampe 0;
BA_ "GenSigSwitchedByIgnition" SG_ 967 MO_OBD2_Lampe 0;
BA_ "GenSigSendType" SG_ 967 MO_Oelwarnung_max 0;
BA_ "GenSigSwitchedByIgnition" SG_ 967 MO_Oelwarnung_max 0;
BA_ "GenSigSendType" SG_ 967 MO_Partikel_Lampe 0;
BA_ "GenSigSwitchedByIgnition" SG_ 967 MO_Partikel_Lampe 0;
BA_ "GenSigSendType" SG_ 967 MO_RedFahrleistung_Lampe 0;
BA_ "GenSigSwitchedByIgnition" SG_ 967 MO_RedFahrleistung_Lampe 0;
BA_ "GenSigSendType" SG_ 967 MO_Systemlampe 0;
BA_ "GenSigSwitchedByIgnition" SG_ 967 MO_Systemlampe 0;
BA_ "GenSigSendType" SG_ 967 MO_Tankdeckel_Lampe 0;
BA_ "GenSigSwitchedByIgnition" SG_ 967 MO_Tankdeckel_Lampe 0;
BA_ "GenSigSendType" SG_ 967 MO_Text_Motorstart 0;
BA_ "GenSigSwitchedByIgnition" SG_ 967 MO_Text_Motorstart 0;
BA_ "GenSigSendType" SG_ 967 MO_Text_Partikelfil_Reg 0;
BA_ "GenSigSwitchedByIgnition" SG_ 967 MO_Text_Partikelfil_Reg 0;
BA_ "GenSigSendType" SG_ 967 MO_Text_Tankdeckelwarn 0;
BA_ "GenSigSwitchedByIgnition" SG_ 967 MO_Text_Tankdeckelwarn 0;
BA_ "GenSigSendType" SG_ 967 MO_Vorglueh_Lampe 0;
BA_ "GenSigSwitchedByIgnition" SG_ 967 MO_Vorglueh_Lampe 0;
BA_ "GenSigSendType" SG_ 967 MO_Zustand_HWP 0;
BA_ "GenSigStartValue" SG_ 967 MO_Zustand_HWP 1;
BA_ "GenSigSwitchedByIgnition" SG_ 967 MO_Zustand_HWP 0;
BA_ "GenSigSendType" SG_ 967 OLEV_Oelstand_nicht_vorhanden 0;
BA_ "GenSigSwitchedByIgnition" SG_ 967 OLEV_Oelstand_nicht_vorhanden 0;
BA_ "GenSigSendType" SG_ 967 OLEV_Systemstoerung 0;
BA_ "GenSigSwitchedByIgnition" SG_ 967 OLEV_Systemstoerung 0;
BA_ "GenSigSendType" SG_ 967 WIV_Anzeige_aktiv 0;
BA_ "GenSigSwitchedByIgnition" SG_ 967 WIV_Anzeige_aktiv 0;
BA_ "GenSigSendType" SG_ 967 WIV_laufender_Motor 0;
BA_ "GenSigSwitchedByIgnition" SG_ 967 WIV_laufender_Motor 0;
BA_ "GenSigSendType" SG_ 967 WIV_nachfuellanzeige_ein 0;
BA_ "GenSigSwitchedByIgnition" SG_ 967 WIV_nachfuellanzeige_ein 0;
BA_ "GenSigSendType" SG_ 967 WIV_nicht_betriebswarm 0;
BA_ "GenSigSwitchedByIgnition" SG_ 967 WIV_nicht_betriebswarm 0;
BA_ "GenSigSendType" SG_ 967 WIV_Oeldr_Warn_Motor 0;
BA_ "GenSigSwitchedByIgnition" SG_ 967 WIV_Oeldr_Warn_Motor 0;
BA_ "GenSigSendType" SG_ 967 WIV_Oeldyn_avl 0;
BA_ "GenSigSwitchedByIgnition" SG_ 967 WIV_Oeldyn_avl 0;
BA_ "GenSigSendType" SG_ 967 WIV_Oelmenge 0;
BA_ "GenSigSwitchedByIgnition" SG_ 967 WIV_Oelmenge 0;
BA_ "GenSigSendType" SG_ 967 WIV_Oelmin_Warn 0;
BA_ "GenSigSwitchedByIgnition" SG_ 967 WIV_Oelmin_Warn 0;
BA_ "GenSigSendType" SG_ 967 WIV_Oelstand 0;
BA_ "GenSigSwitchedByIgnition" SG_ 967 WIV_Oelstand 0;
BA_ "GenSigSendType" SG_ 967 WIV_Oelstand_nicht_vorhanden 0;
BA_ "GenSigSwitchedByIgnition" SG_ 967 WIV_Oelstand_nicht_vorhanden 0;
BA_ "GenSigSendType" SG_ 967 WIV_Oelsystem_aktiv 0;
BA_ "GenSigSwitchedByIgnition" SG_ 967 WIV_Oelsystem_aktiv 0;
BA_ "GenSigSendType" SG_ 967 WIV_Schieflage 0;
BA_ "GenSigSwitchedByIgnition" SG_ 967 WIV_Schieflage 0;
BA_ "GenSigSendType" SG_ 967 WIV_Sensorfehler 0;
BA_ "GenSigSwitchedByIgnition" SG_ 967 WIV_Sensorfehler 0;
BA_ "GenSigSendType" SG_ 967 WIV_Ueberfuell_deaktiv 0;
BA_ "GenSigSwitchedByIgnition" SG_ 967 WIV_Ueberfuell_deaktiv 0;
BA_ "GenSigSendType" SG_ 967 WIV_Ueberfuell_Warn 0;
BA_ "GenSigSwitchedByIgnition" SG_ 967 WIV_Ueberfuell_Warn 0;
BA_ "GenSigSendType" SG_ 967 WIV_Unterfuell_Warn 0;
BA_ "GenSigSwitchedByIgnition" SG_ 967 WIV_Unterfuell_Warn 0;
BA_ "GenSigSendType" SG_ 1366 MO_Fahrzeugabstellzeit 0;
BA_ "GenSigStartValue" SG_ 1366 MO_Fahrzeugabstellzeit 254;
BA_ "GenSigSwitchedByIgnition" SG_ 1366 MO_Fahrzeugabstellzeit 0;
BA_ "Fehlerwert" SG_ 1366 MO_Fahrzeugabstellzeit 255;
BA_ "GenSigSendType" SG_ 1366 MO_Fahrzeugabstellzeit_Status 0;
BA_ "GenSigSwitchedByIgnition" SG_ 1366 MO_Fahrzeugabstellzeit_Status 0;
BA_ "GenSigSendType" SG_ 1366 MO_HV_Auszeit 0;
BA_ "GenSigStartValue" SG_ 1366 MO_HV_Auszeit 510;
BA_ "GenSigSwitchedByIgnition" SG_ 1366 MO_HV_Auszeit 0;
BA_ "Fehlerwert" SG_ 1366 MO_HV_Auszeit 511;
BA_ "GenSigSendType" SG_ 1366 MO_HV_Auszeit_Status 0;
BA_ "GenSigSwitchedByIgnition" SG_ 1366 MO_HV_Auszeit_Status 0;
BA_ "GenSigSendType" SG_ 1366 MO_Verbau_StartSys_EM_HV 0;
BA_ "GenSigSwitchedByIgnition" SG_ 1366 MO_Verbau_StartSys_EM_HV 0;
BA_ "GenSigSendType" SG_ 1366 MO_Verbau_StartSys_EM_MV 0;
BA_ "GenSigSwitchedByIgnition" SG_ 1366 MO_Verbau_StartSys_EM_MV 0;
BA_ "GenSigSendType" SG_ 1366 MO_Verbau_StartSys_Q_Diode 0;
BA_ "GenSigSwitchedByIgnition" SG_ 1366 MO_Verbau_StartSys_Q_Diode 0;
BA_ "GenSigSendType" SG_ 1366 MO_Verbau_StartSys_Ritzelstarter 0;
BA_ "GenSigSwitchedByIgnition" SG_ 1366 MO_Verbau_StartSys_Ritzelstarter 0;
BA_ "GenSigSendType" SG_ 1366 MO_Verbau_StartSys_RSG_MV 0;
BA_ "GenSigSwitchedByIgnition" SG_ 1366 MO_Verbau_StartSys_RSG_MV 0;
BA_ "GenSigSendType" SG_ 1366 MO_Verbau_StartSys_RSG_NV 0;
BA_ "GenSigSwitchedByIgnition" SG_ 1366 MO_Verbau_StartSys_RSG_NV 0;
BA_ "GenSigSendType" SG_ 1366 MO_Ziel_SoC_Fremdladung 0;
BA_ "GenSigStartValue" SG_ 1366 MO_Ziel_SoC_Fremdladung 254;
BA_ "GenSigSwitchedByIgnition" SG_ 1366 MO_Ziel_SoC_Fremdladung 0;
BA_ "GenSigSendType" SG_ 1367 AGK_Charisma_FahrPr 3;
BA_ "GenSigSwitchedByIgnition" SG_ 1367 AGK_Charisma_FahrPr 0;
BA_ "GenSigSendType" SG_ 1367 AGK_Charisma_Status 3;
BA_ "GenSigSwitchedByIgnition" SG_ 1367 AGK_Charisma_Status 0;
BA_ "GenSigSendType" SG_ 1367 MO_Bordnetz_Anf 3;
BA_ "GenSigSwitchedByIgnition" SG_ 1367 MO_Bordnetz_Anf 0;
BA_ "GenSigSendType" SG_ 1367 MO_El_Grundlast_Anf 3;
BA_ "GenSigSwitchedByIgnition" SG_ 1367 MO_El_Grundlast_Anf 0;
BA_ "GenSigSendType" SG_ 1367 Mo_Empf_Red_Genlast 3;
BA_ "GenSigSwitchedByIgnition" SG_ 1367 Mo_Empf_Red_Genlast 0;
BA_ "GenSigSendType" SG_ 1367 MO_FestSpannungsAnf 3;
BA_ "GenSigSwitchedByIgnition" SG_ 1367 MO_FestSpannungsAnf 0;
BA_ "GenSigSendType" SG_ 1367 MO_Freilauf_Charisma_FahrPr 3;
BA_ "GenSigSwitchedByIgnition" SG_ 1367 MO_Freilauf_Charisma_FahrPr 0;
BA_ "GenSigSendType" SG_ 1367 MO_Freilauf_Charisma_Status 3;
BA_ "GenSigSwitchedByIgnition" SG_ 1367 MO_Freilauf_Charisma_Status 0;
BA_ "GenSigSendType" SG_ 1367 MO_Kaltstartleistung_Anf 0;
BA_ "GenSigStartValue" SG_ 1367 MO_Kaltstartleistung_Anf 126;
BA_ "GenSigSwitchedByIgnition" SG_ 1367 MO_Kaltstartleistung_Anf 0;
BA_ "Fehlerwert" SG_ 1367 MO_Kaltstartleistung_Anf 127;
BA_ "GenSigSendType" SG_ 1367 MO_Kaltstarttemperatur 0;
BA_ "GenSigStartValue" SG_ 1367 MO_Kaltstarttemperatur 254;
BA_ "GenSigSwitchedByIgnition" SG_ 1367 MO_Kaltstarttemperatur 0;
BA_ "Fehlerwert" SG_ 1367 MO_Kaltstarttemperatur 255;
BA_ "GenSigSendType" SG_ 1367 MO_Lastabwurf 3;
BA_ "GenSigSwitchedByIgnition" SG_ 1367 MO_Lastabwurf 0;
BA_ "GenSigSendType" SG_ 1367 MO_Strecke_Reg_Anf 0;
BA_ "GenSigStartValue" SG_ 1367 MO_Strecke_Reg_Anf 63;
BA_ "GenSigSwitchedByIgnition" SG_ 1367 MO_Strecke_Reg_Anf 0;
BA_ "GenSigSendType" SG_ 269 MO_Drehzahl_01 0;
BA_ "GenSigSwitchedByIgnition" SG_ 269 MO_Drehzahl_01 0;
BA_ "GenSigSendType" SG_ 269 MO_Drehzahl_VM 0;
BA_ "GenSigSwitchedByIgnition" SG_ 269 MO_Drehzahl_VM 0;
BA_ "GenSigSendType" SG_ 269 MO_EM1_SollDrehzahl 0;
BA_ "GenSigStartValue" SG_ 269 MO_EM1_SollDrehzahl 32767;
BA_ "GenSigSwitchedByIgnition" SG_ 269 MO_EM1_SollDrehzahl 0;
BA_ "GenSigSendType" SG_ 269 MO_EM2_SollDrehzahl 0;
BA_ "GenSigStartValue" SG_ 269 MO_EM2_SollDrehzahl 32767;
BA_ "GenSigSwitchedByIgnition" SG_ 269 MO_EM2_SollDrehzahl 0;
BA_ "GenSigSendType" SG_ 269 MO_erste_Ungenauschwelle 0;
BA_ "GenSigSwitchedByIgnition" SG_ 269 MO_erste_Ungenauschwelle 0;
BA_ "GenSigSendType" SG_ 269 MO_HYB_E_Faktor 0;
BA_ "GenSigSwitchedByIgnition" SG_ 269 MO_HYB_E_Faktor 0;
BA_ "GenSigSendType" SG_ 269 MO_HYB_EMode_Info 0;
BA_ "GenSigSwitchedByIgnition" SG_ 269 MO_HYB_EMode_Info 0;
BA_ "GenSigSendType" SG_ 269 MO_HYB_Freigabe_VM_Eingr 0;
BA_ "GenSigSwitchedByIgnition" SG_ 269 MO_HYB_Freigabe_VM_Eingr 0;
BA_ "GenSigSendType" SG_ 269 MO_HYB_Komfortstufe 0;
BA_ "GenSigSendType" SG_ 269 MO_HYB_LowSpeedModus 0;
BA_ "GenSigSwitchedByIgnition" SG_ 269 MO_HYB_LowSpeedModus 0;
BA_ "GenSigSendType" SG_ 269 MO_HYB_max_ind_VM_Mom_02 0;
BA_ "GenSigStartValue" SG_ 269 MO_HYB_max_ind_VM_Mom_02 254;
BA_ "GenSigSwitchedByIgnition" SG_ 269 MO_HYB_max_ind_VM_Mom_02 0;
BA_ "Fehlerwert" SG_ 269 MO_HYB_max_ind_VM_Mom_02 255;
BA_ "GenSigSendType" SG_ 269 MO_HYB_Modus_Ankopplung_VM 0;
BA_ "GenSigSwitchedByIgnition" SG_ 269 MO_HYB_Modus_Ankopplung_VM 0;
BA_ "GenSigSendType" SG_ 269 MO_HYB_Schaltverhinderung 0;
BA_ "GenSigSendType" SG_ 269 MO_HYB_Sollstatus_K0 0;
BA_ "GenSigSwitchedByIgnition" SG_ 269 MO_HYB_Sollstatus_K0 0;
BA_ "GenSigSendType" SG_ 269 MO_HYB_Stoppmodus 0;
BA_ "GenSigSendType" SG_ 269 MO_HYB_VM_bereit 0;
BA_ "GenSigSwitchedByIgnition" SG_ 269 MO_HYB_VM_bereit 0;
BA_ "GenSigSendType" SG_ 269 MO_HYB_VM_Mom_oE_02 0;
BA_ "GenSigStartValue" SG_ 269 MO_HYB_VM_Mom_oE_02 254;
BA_ "GenSigSwitchedByIgnition" SG_ 269 MO_HYB_VM_Mom_oE_02 0;
BA_ "Fehlerwert" SG_ 269 MO_HYB_VM_Mom_oE_02 255;
BA_ "GenSigSendType" SG_ 269 MO_HYB_Zielzustand 0;
BA_ "GenSigSwitchedByIgnition" SG_ 269 MO_HYB_Zielzustand 0;
BA_ "Fehlerwert" SG_ 269 MO_HYB_Zielzustand 7;
BA_ "GenSigSendType" SG_ 269 MO_Luftpfad_Verzugszeit_praed 0;
BA_ "GenSigSwitchedByIgnition" SG_ 269 MO_Luftpfad_Verzugszeit_praed 0;
BA_ "GenSigSendType" SG_ 269 MO_Mom_Begr_Fahr 0;
BA_ "GenSigStartValue" SG_ 269 MO_Mom_Begr_Fahr 510;
BA_ "GenSigSwitchedByIgnition" SG_ 269 MO_Mom_Begr_Fahr 0;
BA_ "Fehlerwert" SG_ 269 MO_Mom_Begr_Fahr 511;
BA_ "GenSigSendType" SG_ 269 MO_Mom_Begr_Schalt 0;
BA_ "GenSigStartValue" SG_ 269 MO_Mom_Begr_Schalt 1022;
BA_ "GenSigSwitchedByIgnition" SG_ 269 MO_Mom_Begr_Schalt 0;
BA_ "GenSigSendType" SG_ 269 MO_Mom_Ist_Summe 0;
BA_ "GenSigStartValue" SG_ 269 MO_Mom_Ist_Summe 1022;
BA_ "GenSigSwitchedByIgnition" SG_ 269 MO_Mom_Ist_Summe 0;
BA_ "GenSigSendType" SG_ 269 MO_Mom_neg_verfuegbar 0;
BA_ "GenSigStartValue" SG_ 269 MO_Mom_neg_verfuegbar 510;
BA_ "GenSigSwitchedByIgnition" SG_ 269 MO_Mom_neg_verfuegbar 0;
BA_ "Fehlerwert" SG_ 269 MO_Mom_neg_verfuegbar 511;
BA_ "GenSigSendType" SG_ 269 MO_Mom_Schub 0;
BA_ "GenSigStartValue" SG_ 269 MO_Mom_Schub 510;
BA_ "GenSigSwitchedByIgnition" SG_ 269 MO_Mom_Schub 0;
BA_ "GenSigSendType" SG_ 269 MO_Mom_Soll_gefiltert 0;
BA_ "GenSigStartValue" SG_ 269 MO_Mom_Soll_gefiltert 1022;
BA_ "GenSigSwitchedByIgnition" SG_ 269 MO_Mom_Soll_gefiltert 0;
BA_ "GenSigSendType" SG_ 269 MO_Mom_Soll_Roh 0;
BA_ "GenSigStartValue" SG_ 269 MO_Mom_Soll_Roh 1022;
BA_ "GenSigSwitchedByIgnition" SG_ 269 MO_Mom_Soll_Roh 0;
BA_ "GenSigSendType" SG_ 269 MO_Mom_Traegheit_Summe 0;
BA_ "GenSigStartValue" SG_ 269 MO_Mom_Traegheit_Summe 1022;
BA_ "GenSigSwitchedByIgnition" SG_ 269 MO_Mom_Traegheit_Summe 0;
BA_ "GenSigSendType" SG_ 269 MO_Momentenintegral_02 0;
BA_ "GenSigSwitchedByIgnition" SG_ 269 MO_Momentenintegral_02 0;
BA_ "GenSigSendType" SG_ 269 MO_QBit_Drehzahl_01 0;
BA_ "GenSigStartValue" SG_ 269 MO_QBit_Drehzahl_01 1;
BA_ "GenSigSwitchedByIgnition" SG_ 269 MO_QBit_Drehzahl_01 0;
BA_ "GenSigSendType" SG_ 269 MO_QBit_Motormomente 0;
BA_ "GenSigStartValue" SG_ 269 MO_QBit_Motormomente 1;
BA_ "GenSigSwitchedByIgnition" SG_ 269 MO_QBit_Motormomente 0;
BA_ "GenSigSendType" SG_ 269 MO_Status_Normalbetrieb_01 0;
BA_ "GenSigSwitchedByIgnition" SG_ 269 MO_Status_Normalbetrieb_01 0;
BA_ "GenSigSendType" SG_ 269 MO_TNW_Max_Strom_Lim 0;
BA_ "GenSigStartValue" SG_ 269 MO_TNW_Max_Strom_Lim 8190;
BA_ "GenSigSwitchedByIgnition" SG_ 269 MO_TNW_Max_Strom_Lim 0;
BA_ "GenSigSendType" SG_ 269 MO_TNW_Min_Strom_Lim 0;
BA_ "GenSigStartValue" SG_ 269 MO_TNW_Min_Strom_Lim 8190;
BA_ "GenSigSwitchedByIgnition" SG_ 269 MO_TNW_Min_Strom_Lim 0;
BA_ "GenSigSendType" SG_ 269 Motor_50_BZ 0;
BA_ "GenSigFuncType" SG_ 269 Motor_50_BZ 1;
BA_ "GenSigSwitchedByIgnition" SG_ 269 Motor_50_BZ 0;
BA_ "GenSigSendType" SG_ 269 Motor_50_CRC 0;
BA_ "GenSigFuncType" SG_ 269 Motor_50_CRC 2;
BA_ "GenSigSwitchedByIgnition" SG_ 269 Motor_50_CRC 0;
BA_ "GenSigSendType" SG_ 332 CE_FlgLnchCtlPreCnd 0;
BA_ "GenSigSwitchedByIgnition" SG_ 332 CE_FlgLnchCtlPreCnd 0;
BA_ "GenSigSendType" SG_ 332 FoD_DTC_TSK_ACC 0;
BA_ "GenSigSwitchedByIgnition" SG_ 332 FoD_DTC_TSK_ACC 0;
BA_ "GenSigSendType" SG_ 332 FoD_DTC_TSK_GRA 0;
BA_ "GenSigSwitchedByIgnition" SG_ 332 FoD_DTC_TSK_GRA 0;
BA_ "GenSigSendType" SG_ 332 ISA_Regelung_aktiv 3;
BA_ "GenSigSwitchedByIgnition" SG_ 332 ISA_Regelung_aktiv 0;
BA_ "GenSigSendType" SG_ 332 ISA_Status 3;
BA_ "GenSigStartValue" SG_ 332 ISA_Status 1;
BA_ "GenSigSwitchedByIgnition" SG_ 332 ISA_Status 0;
BA_ "GenSigSendType" SG_ 332 ISA_Tempolimitwarnung 3;
BA_ "GenSigSwitchedByIgnition" SG_ 332 ISA_Tempolimitwarnung 0;
BA_ "GenSigSendType" SG_ 332 MO_Anforderung_HMS 3;
BA_ "GenSigSwitchedByIgnition" SG_ 332 MO_Anforderung_HMS 0;
BA_ "GenSigSendType" SG_ 332 MO_EBoost_verf_praed 0;
BA_ "GenSigSwitchedByIgnition" SG_ 332 MO_EBoost_verf_praed 0;
BA_ "GenSigSendType" SG_ 332 MO_eLaunch_verf 0;
BA_ "GenSigSwitchedByIgnition" SG_ 332 MO_eLaunch_verf 0;
BA_ "GenSigSendType" SG_ 332 MO_EMG_Max_Leistung 0;
BA_ "GenSigStartValue" SG_ 332 MO_EMG_Max_Leistung 2046;
BA_ "GenSigSwitchedByIgnition" SG_ 332 MO_EMG_Max_Leistung 0;
BA_ "Fehlerwert" SG_ 332 MO_EMG_Max_Leistung 2047;
BA_ "GenSigSendType" SG_ 332 MO_EMG_Min_Leistung 0;
BA_ "GenSigStartValue" SG_ 332 MO_EMG_Min_Leistung 2046;
BA_ "GenSigSwitchedByIgnition" SG_ 332 MO_EMG_Min_Leistung 0;
BA_ "Fehlerwert" SG_ 332 MO_EMG_Min_Leistung 2047;
BA_ "GenSigSendType" SG_ 332 MO_Fahrbereitschaft 3;
BA_ "GenSigSwitchedByIgnition" SG_ 332 MO_Fahrbereitschaft 0;
BA_ "GenSigSendType" SG_ 332 MO_Freilauf_Info 3;
BA_ "GenSigSwitchedByIgnition" SG_ 332 MO_Freilauf_Info 0;
BA_ "GenSigSendType" SG_ 332 MO_Freilauf_Status 3;
BA_ "GenSigSwitchedByIgnition" SG_ 332 MO_Freilauf_Status 0;
BA_ "Fehlerwert" SG_ 332 MO_Freilauf_Status 7;
BA_ "GenSigSendType" SG_ 332 MO_Heckspoiler_Anf 0;
BA_ "GenSigSwitchedByIgnition" SG_ 332 MO_Heckspoiler_Anf 0;
BA_ "GenSigSendType" SG_ 332 MO_Klima_Regelmodus 0;
BA_ "GenSigSwitchedByIgnition" SG_ 332 MO_Klima_Regelmodus 0;
BA_ "GenSigSendType" SG_ 332 MO_Krit_Heckobjekt 0;
BA_ "GenSigSwitchedByIgnition" SG_ 332 MO_Krit_Heckobjekt 0;
BA_ "Fehlerwert" SG_ 332 MO_Krit_Heckobjekt 7;
BA_ "GenSigSendType" SG_ 332 MO_Kuppl_betaetigt 3;
BA_ "GenSigSwitchedByIgnition" SG_ 332 MO_Kuppl_betaetigt 0;
BA_ "GenSigSendType" SG_ 332 MO_LaunchControl 0;
BA_ "GenSigSwitchedByIgnition" SG_ 332 MO_LaunchControl 0;
BA_ "GenSigSendType" SG_ 332 MO_MVEM_MaxLeistung_MVVerbrauch 0;
BA_ "GenSigStartValue" SG_ 332 MO_MVEM_MaxLeistung_MVVerbrauch 1022;
BA_ "GenSigSwitchedByIgnition" SG_ 332 MO_MVEM_MaxLeistung_MVVerbrauch 0;
BA_ "Fehlerwert" SG_ 332 MO_MVEM_MaxLeistung_MVVerbrauch 1023;
BA_ "GenSigSendType" SG_ 332 MO_MVEM_MinLeistung_MVVerbrauch 0;
BA_ "GenSigStartValue" SG_ 332 MO_MVEM_MinLeistung_MVVerbrauch 1022;
BA_ "GenSigSwitchedByIgnition" SG_ 332 MO_MVEM_MinLeistung_MVVerbrauch 0;
BA_ "Fehlerwert" SG_ 332 MO_MVEM_MinLeistung_MVVerbrauch 1023;
BA_ "GenSigSendType" SG_ 332 MO_NGS_Gangpos 3;
BA_ "GenSigSwitchedByIgnition" SG_ 332 MO_NGS_Gangpos 0;
BA_ "Fehlerwert" SG_ 332 MO_NGS_Gangpos 7;
BA_ "GenSigSendType" SG_ 332 MO_Positionierung_aktiv 0;
BA_ "GenSigSwitchedByIgnition" SG_ 332 MO_Positionierung_aktiv 0;
BA_ "GenSigSendType" SG_ 332 MO_QBit_Aussen_Temp 0;
BA_ "GenSigStartValue" SG_ 332 MO_QBit_Aussen_Temp 1;
BA_ "GenSigSwitchedByIgnition" SG_ 332 MO_QBit_Aussen_Temp 0;
BA_ "GenSigSendType" SG_ 332 MO_QBit_Kuppl_betaetigt 3;
BA_ "GenSigSwitchedByIgnition" SG_ 332 MO_QBit_Kuppl_betaetigt 0;
BA_ "GenSigSendType" SG_ 332 MO_Red_El_Fahrleistung 0;
BA_ "GenSigSwitchedByIgnition" SG_ 332 MO_Red_El_Fahrleistung 0;
BA_ "GenSigSendType" SG_ 332 MO_Servicemodus 0;
BA_ "GenSigSwitchedByIgnition" SG_ 332 MO_Servicemodus 0;
BA_ "GenSigSendType" SG_ 332 MO_Startwunsch 3;
BA_ "GenSigSwitchedByIgnition" SG_ 332 MO_Startwunsch 0;
BA_ "GenSigSendType" SG_ 332 MO_UBE_Hybrid_Reserve 0;
BA_ "GenSigStartValue" SG_ 332 MO_UBE_Hybrid_Reserve 1023;
BA_ "GenSigSwitchedByIgnition" SG_ 332 MO_UBE_Hybrid_Reserve 0;
BA_ "GenSigSendType" SG_ 332 MO_UBE_Reserve 0;
BA_ "GenSigStartValue" SG_ 332 MO_UBE_Reserve 1023;
BA_ "GenSigSwitchedByIgnition" SG_ 332 MO_UBE_Reserve 0;
BA_ "GenSigSendType" SG_ 332 MO_Veto_Launchcontrol 0;
BA_ "GenSigSwitchedByIgnition" SG_ 332 MO_Veto_Launchcontrol 0;
BA_ "GenSigSendType" SG_ 332 Motor_54_BZ 0;
BA_ "GenSigFuncType" SG_ 332 Motor_54_BZ 1;
BA_ "GenSigSwitchedByIgnition" SG_ 332 Motor_54_BZ 0;
BA_ "GenSigSendType" SG_ 332 Motor_54_CRC 0;
BA_ "GenSigFuncType" SG_ 332 Motor_54_CRC 2;
BA_ "GenSigSwitchedByIgnition" SG_ 332 Motor_54_CRC 0;
BA_ "GenSigSendType" SG_ 332 OBD_Abs_Load_Val 0;
BA_ "GenSigStartValue" SG_ 332 OBD_Abs_Load_Val 65535;
BA_ "GenSigSwitchedByIgnition" SG_ 332 OBD_Abs_Load_Val 0;
BA_ "GenSigSendType" SG_ 332 OBD_Abs_Pedal_Pos 0;
BA_ "GenSigStartValue" SG_ 332 OBD_Abs_Pedal_Pos 255;
BA_ "GenSigSwitchedByIgnition" SG_ 332 OBD_Abs_Pedal_Pos 0;
BA_ "GenSigSendType" SG_ 332 OBD_Abs_Throttle_Pos 0;
BA_ "GenSigStartValue" SG_ 332 OBD_Abs_Throttle_Pos 255;
BA_ "GenSigSwitchedByIgnition" SG_ 332 OBD_Abs_Throttle_Pos 0;
BA_ "GenSigSendType" SG_ 332 OBD_Aussen_Temp_gef 0;
BA_ "GenSigStartValue" SG_ 332 OBD_Aussen_Temp_gef 254;
BA_ "GenSigSwitchedByIgnition" SG_ 332 OBD_Aussen_Temp_gef 0;
BA_ "Fehlerwert" SG_ 332 OBD_Aussen_Temp_gef 255;
BA_ "GenSigSendType" SG_ 332 OBD_Calc_Load_Val 0;
BA_ "GenSigStartValue" SG_ 332 OBD_Calc_Load_Val 255;
BA_ "GenSigSwitchedByIgnition" SG_ 332 OBD_Calc_Load_Val 0;
BA_ "GenSigSendType" SG_ 332 OBD_ClearMem_Inhibit 0;
BA_ "GenSigSwitchedByIgnition" SG_ 332 OBD_ClearMem_Inhibit 0;
BA_ "GenSigSendType" SG_ 332 OBD_Driving_Cycle 0;
BA_ "GenSigSwitchedByIgnition" SG_ 332 OBD_Driving_Cycle 0;
BA_ "GenSigSendType" SG_ 332 OBD_Eng_Cool_Temp 0;
BA_ "GenSigStartValue" SG_ 332 OBD_Eng_Cool_Temp 255;
BA_ "GenSigSwitchedByIgnition" SG_ 332 OBD_Eng_Cool_Temp 0;
BA_ "GenSigSendType" SG_ 332 OBD_Kaltstart_Denominator 0;
BA_ "GenSigSwitchedByIgnition" SG_ 332 OBD_Kaltstart_Denominator 0;
BA_ "GenSigSendType" SG_ 332 OBD_Minimum_Trip 0;
BA_ "GenSigSwitchedByIgnition" SG_ 332 OBD_Minimum_Trip 0;
BA_ "GenSigSendType" SG_ 332 OBD_Normed_Trip 0;
BA_ "GenSigSwitchedByIgnition" SG_ 332 OBD_Normed_Trip 0;
BA_ "GenSigSendType" SG_ 332 OBD_Sperrung_IUMPR 0;
BA_ "GenSigSwitchedByIgnition" SG_ 332 OBD_Sperrung_IUMPR 0;
BA_ "GenSigSendType" SG_ 332 OBD_Sperrung_Kaltstart_Denom 0;
BA_ "GenSigSwitchedByIgnition" SG_ 332 OBD_Sperrung_Kaltstart_Denom 0;
BA_ "GenSigSendType" SG_ 332 OBD_Warm_Up_Cycle 0;
BA_ "GenSigSwitchedByIgnition" SG_ 332 OBD_Warm_Up_Cycle 0;
BA_ "GenSigSendType" SG_ 332 OBDProtocol_req 0;
BA_ "GenSigSwitchedByIgnition" SG_ 332 OBDProtocol_req 0;
BA_ "Fehlerwert" SG_ 332 OBDProtocol_req 255;
BA_ "GenSigSendType" SG_ 332 TSK_ACC_FoD_Status 0;
BA_ "GenSigSwitchedByIgnition" SG_ 332 TSK_ACC_FoD_Status 0;
BA_ "GenSigSendType" SG_ 332 TSK_aktives_System 3;
BA_ "GenSigSwitchedByIgnition" SG_ 332 TSK_aktives_System 0;
BA_ "GenSigSendType" SG_ 332 TSK_aktives_System_02 3;
BA_ "GenSigSwitchedByIgnition" SG_ 332 TSK_aktives_System_02 0;
BA_ "GenSigSendType" SG_ 332 TSK_Anf_Antriebsmoment 3;
BA_ "GenSigSwitchedByIgnition" SG_ 332 TSK_Anf_Antriebsmoment 0;
BA_ "GenSigSendType" SG_ 332 TSK_Einheit_vMax_Fahrerassistenz 0;
BA_ "GenSigSwitchedByIgnition" SG_ 332 TSK_Einheit_vMax_Fahrerassistenz 0;
BA_ "GenSigSendType" SG_ 332 TSK_erhoehter_Fahrwiderstand 3;
BA_ "GenSigSwitchedByIgnition" SG_ 332 TSK_erhoehter_Fahrwiderstand 0;
BA_ "GenSigSendType" SG_ 332 TSK_GRA_FoD_Status 0;
BA_ "GenSigSwitchedByIgnition" SG_ 332 TSK_GRA_FoD_Status 0;
BA_ "GenSigSendType" SG_ 332 TSK_Status_ARA 3;
BA_ "GenSigStartValue" SG_ 332 TSK_Status_ARA 1;
BA_ "GenSigSwitchedByIgnition" SG_ 332 TSK_Status_ARA 0;
BA_ "Fehlerwert" SG_ 332 TSK_Status_ARA 7;
BA_ "GenSigSendType" SG_ 332 TSK_Status_EA 3;
BA_ "GenSigStartValue" SG_ 332 TSK_Status_EA 1;
BA_ "GenSigSwitchedByIgnition" SG_ 332 TSK_Status_EA 0;
BA_ "Fehlerwert" SG_ 332 TSK_Status_EA 7;
BA_ "GenSigSendType" SG_ 332 TSK_Status_IPA 3;
BA_ "GenSigStartValue" SG_ 332 TSK_Status_IPA 1;
BA_ "GenSigSwitchedByIgnition" SG_ 332 TSK_Status_IPA 0;
BA_ "Fehlerwert" SG_ 332 TSK_Status_IPA 7;
BA_ "GenSigSendType" SG_ 332 TSK_Status_PLA 3;
BA_ "GenSigStartValue" SG_ 332 TSK_Status_PLA 1;
BA_ "GenSigSwitchedByIgnition" SG_ 332 TSK_Status_PLA 0;
BA_ "Fehlerwert" SG_ 332 TSK_Status_PLA 7;
BA_ "GenSigSendType" SG_ 332 TSK_Status_RHP 3;
BA_ "GenSigStartValue" SG_ 332 TSK_Status_RHP 1;
BA_ "GenSigSwitchedByIgnition" SG_ 332 TSK_Status_RHP 0;
BA_ "GenSigSendType" SG_ 332 TSK_vMax_aktuell 0;
BA_ "GenSigStartValue" SG_ 332 TSK_vMax_aktuell 255;
BA_ "GenSigSendType" SG_ 332 TSK_vMax_Fahrerassistenz 0;
BA_ "GenSigStartValue" SG_ 332 TSK_vMax_Fahrerassistenz 511;
BA_ "GenSigSwitchedByIgnition" SG_ 332 TSK_vMax_Fahrerassistenz 0;
BA_ "GenSigSendType" SG_ 553 SOK_Motor_54_Signatur 0;
BA_ "GenSigFuncType" SG_ 553 SOK_Motor_54_Signatur 15;
BA_ "GenSigSwitchedByIgnition" SG_ 553 SOK_Motor_54_Signatur 0;
BA_ "GenSigSendType" SG_ 190 MO_CluAxs_Set 0;
BA_ "GenSigSwitchedByIgnition" SG_ 190 MO_CluAxs_Set 0;
BA_ "GenSigSendType" SG_ 190 MO_CluEng_Set 0;
BA_ "GenSigSwitchedByIgnition" SG_ 190 MO_CluEng_Set 0;
BA_ "GenSigSendType" SG_ 190 MO_DC_Max_Strom_HV 0;
BA_ "GenSigStartValue" SG_ 190 MO_DC_Max_Strom_HV 255;
BA_ "GenSigSwitchedByIgnition" SG_ 190 MO_DC_Max_Strom_HV 0;
BA_ "GenSigSendType" SG_ 190 MO_DC_SollSpannung_HV 0;
BA_ "GenSigStartValue" SG_ 190 MO_DC_SollSpannung_HV 255;
BA_ "GenSigSwitchedByIgnition" SG_ 190 MO_DC_SollSpannung_HV 0;
BA_ "GenSigSendType" SG_ 190 MO_EM1_AR_Anf 0;
BA_ "GenSigSwitchedByIgnition" SG_ 190 MO_EM1_AR_Anf 0;
BA_ "GenSigSendType" SG_ 190 MO_EM1_DynLimit_AR 0;
BA_ "GenSigStartValue" SG_ 190 MO_EM1_DynLimit_AR 255;
BA_ "GenSigSwitchedByIgnition" SG_ 190 MO_EM1_DynLimit_AR 0;
BA_ "GenSigSendType" SG_ 190 MO_EM1_Kp_AR 0;
BA_ "GenSigStartValue" SG_ 190 MO_EM1_Kp_AR 511;
BA_ "GenSigSwitchedByIgnition" SG_ 190 MO_EM1_Kp_AR 0;
BA_ "GenSigSendType" SG_ 190 MO_EM1_Max_Leistung 0;
BA_ "GenSigStartValue" SG_ 190 MO_EM1_Max_Leistung 16382;
BA_ "GenSigSwitchedByIgnition" SG_ 190 MO_EM1_Max_Leistung 0;
BA_ "GenSigSendType" SG_ 190 MO_EM1_Max_Moment 0;
BA_ "GenSigStartValue" SG_ 190 MO_EM1_Max_Moment 4094;
BA_ "GenSigSwitchedByIgnition" SG_ 190 MO_EM1_Max_Moment 0;
BA_ "GenSigSendType" SG_ 190 MO_EM1_Max_Strom_Lim 0;
BA_ "GenSigStartValue" SG_ 190 MO_EM1_Max_Strom_Lim 8190;
BA_ "GenSigSwitchedByIgnition" SG_ 190 MO_EM1_Max_Strom_Lim 0;
BA_ "GenSigSendType" SG_ 190 MO_EM1_MaxDrehzahl 0;
BA_ "GenSigStartValue" SG_ 190 MO_EM1_MaxDrehzahl 16383;
BA_ "GenSigSwitchedByIgnition" SG_ 190 MO_EM1_MaxDrehzahl 0;
BA_ "GenSigSendType" SG_ 190 MO_EM1_Min_Leistung 0;
BA_ "GenSigStartValue" SG_ 190 MO_EM1_Min_Leistung 16382;
BA_ "GenSigSwitchedByIgnition" SG_ 190 MO_EM1_Min_Leistung 0;
BA_ "GenSigSendType" SG_ 190 MO_EM1_Min_Moment 0;
BA_ "GenSigStartValue" SG_ 190 MO_EM1_Min_Moment 4094;
BA_ "GenSigSwitchedByIgnition" SG_ 190 MO_EM1_Min_Moment 0;
BA_ "GenSigSendType" SG_ 190 MO_EM1_Min_Strom_Lim 0;
BA_ "GenSigStartValue" SG_ 190 MO_EM1_Min_Strom_Lim 8190;
BA_ "GenSigSwitchedByIgnition" SG_ 190 MO_EM1_Min_Strom_Lim 0;
BA_ "GenSigSendType" SG_ 190 MO_EM1_MinDrehzahl 0;
BA_ "GenSigStartValue" SG_ 190 MO_EM1_MinDrehzahl 16383;
BA_ "GenSigSwitchedByIgnition" SG_ 190 MO_EM1_MinDrehzahl 0;
BA_ "GenSigSendType" SG_ 190 MO_EM1_Periode_AR 0;
BA_ "GenSigStartValue" SG_ 190 MO_EM1_Periode_AR 255;
BA_ "GenSigSwitchedByIgnition" SG_ 190 MO_EM1_Periode_AR 0;
BA_ "GenSigSendType" SG_ 190 MO_EM1_Sollmodus 0;
BA_ "GenSigStartValue" SG_ 190 MO_EM1_Sollmodus 15;
BA_ "GenSigSwitchedByIgnition" SG_ 190 MO_EM1_Sollmodus 0;
BA_ "GenSigSendType" SG_ 190 MO_EM1_SollMoment 0;
BA_ "GenSigStartValue" SG_ 190 MO_EM1_SollMoment 4094;
BA_ "GenSigSwitchedByIgnition" SG_ 190 MO_EM1_SollMoment 0;
BA_ "GenSigSendType" SG_ 190 MO_EM1_SollSpannung 0;
BA_ "GenSigStartValue" SG_ 190 MO_EM1_SollSpannung 4095;
BA_ "GenSigSwitchedByIgnition" SG_ 190 MO_EM1_SollSpannung 0;
BA_ "GenSigSendType" SG_ 190 MO_EM2_AR_Anf 0;
BA_ "GenSigSwitchedByIgnition" SG_ 190 MO_EM2_AR_Anf 0;
BA_ "GenSigSendType" SG_ 190 MO_EM2_DynLimit_AR 0;
BA_ "GenSigStartValue" SG_ 190 MO_EM2_DynLimit_AR 255;
BA_ "GenSigSwitchedByIgnition" SG_ 190 MO_EM2_DynLimit_AR 0;
BA_ "GenSigSendType" SG_ 190 MO_EM2_Kp_AR 0;
BA_ "GenSigStartValue" SG_ 190 MO_EM2_Kp_AR 511;
BA_ "GenSigSwitchedByIgnition" SG_ 190 MO_EM2_Kp_AR 0;
BA_ "GenSigSendType" SG_ 190 MO_EM2_Max_Leistung 0;
BA_ "GenSigStartValue" SG_ 190 MO_EM2_Max_Leistung 16382;
BA_ "GenSigSwitchedByIgnition" SG_ 190 MO_EM2_Max_Leistung 0;
BA_ "GenSigSendType" SG_ 190 MO_EM2_Max_Moment 0;
BA_ "GenSigStartValue" SG_ 190 MO_EM2_Max_Moment 4094;
BA_ "GenSigSwitchedByIgnition" SG_ 190 MO_EM2_Max_Moment 0;
BA_ "Fehlerwert" SG_ 190 MO_EM2_Max_Moment 4095;
BA_ "GenSigSendType" SG_ 190 MO_EM2_Max_Strom_Lim 0;
BA_ "GenSigStartValue" SG_ 190 MO_EM2_Max_Strom_Lim 8190;
BA_ "GenSigSwitchedByIgnition" SG_ 190 MO_EM2_Max_Strom_Lim 0;
BA_ "GenSigSendType" SG_ 190 MO_EM2_MaxDrehzahl 0;
BA_ "GenSigStartValue" SG_ 190 MO_EM2_MaxDrehzahl 16383;
BA_ "GenSigSwitchedByIgnition" SG_ 190 MO_EM2_MaxDrehzahl 0;
BA_ "GenSigSendType" SG_ 190 MO_EM2_Min_Leistung 0;
BA_ "GenSigStartValue" SG_ 190 MO_EM2_Min_Leistung 16382;
BA_ "GenSigSwitchedByIgnition" SG_ 190 MO_EM2_Min_Leistung 0;
BA_ "GenSigSendType" SG_ 190 MO_EM2_Min_Moment 0;
BA_ "GenSigStartValue" SG_ 190 MO_EM2_Min_Moment 4094;
BA_ "GenSigSwitchedByIgnition" SG_ 190 MO_EM2_Min_Moment 0;
BA_ "Fehlerwert" SG_ 190 MO_EM2_Min_Moment 4095;
BA_ "GenSigSendType" SG_ 190 MO_EM2_Min_Strom_Lim 0;
BA_ "GenSigStartValue" SG_ 190 MO_EM2_Min_Strom_Lim 8190;
BA_ "GenSigSwitchedByIgnition" SG_ 190 MO_EM2_Min_Strom_Lim 0;
BA_ "GenSigSendType" SG_ 190 MO_EM2_MinDrehzahl 0;
BA_ "GenSigStartValue" SG_ 190 MO_EM2_MinDrehzahl 16383;
BA_ "GenSigSwitchedByIgnition" SG_ 190 MO_EM2_MinDrehzahl 0;
BA_ "GenSigSendType" SG_ 190 MO_EM2_Periode_AR 0;
BA_ "GenSigStartValue" SG_ 190 MO_EM2_Periode_AR 255;
BA_ "GenSigSwitchedByIgnition" SG_ 190 MO_EM2_Periode_AR 0;
BA_ "GenSigSendType" SG_ 190 MO_EM2_Sollmodus 0;
BA_ "GenSigStartValue" SG_ 190 MO_EM2_Sollmodus 15;
BA_ "GenSigSwitchedByIgnition" SG_ 190 MO_EM2_Sollmodus 0;
BA_ "GenSigSendType" SG_ 190 MO_EM2_SollMoment 0;
BA_ "GenSigStartValue" SG_ 190 MO_EM2_SollMoment 4094;
BA_ "GenSigSwitchedByIgnition" SG_ 190 MO_EM2_SollMoment 0;
BA_ "Fehlerwert" SG_ 190 MO_EM2_SollMoment 4095;
BA_ "GenSigSendType" SG_ 190 MO_EM2_SollSpannung 0;
BA_ "GenSigStartValue" SG_ 190 MO_EM2_SollSpannung 4095;
BA_ "GenSigSwitchedByIgnition" SG_ 190 MO_EM2_SollSpannung 0;
BA_ "GenSigSendType" SG_ 190 Motor_56_BZ 0;
BA_ "GenSigFuncType" SG_ 190 Motor_56_BZ 1;
BA_ "GenSigSwitchedByIgnition" SG_ 190 Motor_56_BZ 0;
BA_ "GenSigSendType" SG_ 190 Motor_56_CRC 0;
BA_ "GenSigFuncType" SG_ 190 Motor_56_CRC 2;
BA_ "GenSigSwitchedByIgnition" SG_ 190 Motor_56_CRC 0;
BA_ "GenSigSendType" SG_ 190 SOK_MO_SollMoment_Signatur 0;
BA_ "GenSigFuncType" SG_ 190 SOK_MO_SollMoment_Signatur 15;
BA_ "GenSigSwitchedByIgnition" SG_ 190 SOK_MO_SollMoment_Signatur 0;
BA_ "GenSigSendType" SG_ 1601 MO_Ansaugsystem 0;
BA_ "GenSigFuncType" SG_ 1601 MO_Ansaugsystem 8;
BA_ "GenSigSwitchedByIgnition" SG_ 1601 MO_Ansaugsystem 0;
BA_ "GenSigSendType" SG_ 1601 MO_Anzahl_Zyl 0;
BA_ "GenSigFuncType" SG_ 1601 MO_Anzahl_Zyl 8;
BA_ "GenSigSwitchedByIgnition" SG_ 1601 MO_Anzahl_Zyl 0;
BA_ "GenSigSendType" SG_ 1601 MO_Anzeige_StSt_gueltig 0;
BA_ "GenSigSwitchedByIgnition" SG_ 1601 MO_Anzeige_StSt_gueltig 0;
BA_ "GenSigSendType" SG_ 1601 MO_Code 0;
BA_ "GenSigSwitchedByIgnition" SG_ 1601 MO_Code 0;
BA_ "GenSigSendType" SG_ 1601 MO_DPF_verbaut 0;
BA_ "GenSigFuncType" SG_ 1601 MO_DPF_verbaut 8;
BA_ "GenSigSwitchedByIgnition" SG_ 1601 MO_DPF_verbaut 0;
BA_ "GenSigSendType" SG_ 1601 MO_Faktor_Momente_02 0;
BA_ "GenSigFuncType" SG_ 1601 MO_Faktor_Momente_02 8;
BA_ "GenSigSwitchedByIgnition" SG_ 1601 MO_Faktor_Momente_02 0;
BA_ "GenSigSendType" SG_ 1601 MO_Getriebe_Code 0;
BA_ "GenSigSwitchedByIgnition" SG_ 1601 MO_Getriebe_Code 0;
BA_ "GenSigSendType" SG_ 1601 MO_Hubraum 0;
BA_ "GenSigFuncType" SG_ 1601 MO_Hubraum 8;
BA_ "GenSigSwitchedByIgnition" SG_ 1601 MO_Hubraum 0;
BA_ "GenSigSendType" SG_ 1601 MO_Hybridfahrzeug 0;
BA_ "GenSigFuncType" SG_ 1601 MO_Hybridfahrzeug 8;
BA_ "GenSigSwitchedByIgnition" SG_ 1601 MO_Hybridfahrzeug 0;
BA_ "GenSigSendType" SG_ 1601 MO_Kraftstoffart 0;
BA_ "GenSigFuncType" SG_ 1601 MO_Kraftstoffart 8;
BA_ "GenSigSwitchedByIgnition" SG_ 1601 MO_Kraftstoffart 0;
BA_ "GenSigSendType" SG_ 1601 MO_Leistung 0;
BA_ "GenSigSwitchedByIgnition" SG_ 1601 MO_Leistung 0;
BA_ "GenSigSendType" SG_ 1601 MO_OBD_Typ 0;
BA_ "GenSigSwitchedByIgnition" SG_ 1601 MO_OBD_Typ 0;
BA_ "GenSigSendType" SG_ 1601 MO_StartStopp_Codiert 0;
BA_ "GenSigFuncType" SG_ 1601 MO_StartStopp_Codiert 8;
BA_ "GenSigSwitchedByIgnition" SG_ 1601 MO_StartStopp_Codiert 0;
BA_ "GenSigSendType" SG_ 1601 Motor_Code_01_BZ 0;
BA_ "GenSigFuncType" SG_ 1601 Motor_Code_01_BZ 1;
BA_ "GenSigSwitchedByIgnition" SG_ 1601 Motor_Code_01_BZ 0;
BA_ "GenSigSendType" SG_ 1601 Motor_Code_01_CRC 0;
BA_ "GenSigFuncType" SG_ 1601 Motor_Code_01_CRC 2;
BA_ "GenSigSwitchedByIgnition" SG_ 1601 Motor_Code_01_CRC 0;
BA_ "GenSigSendType" SG_ 1601 TSK_Codierung 0;
BA_ "GenSigStartValue" SG_ 1601 TSK_Codierung 7;
BA_ "GenSigSwitchedByIgnition" SG_ 1601 TSK_Codierung 0;
BA_ "GenSigSendType" SG_ 391 EV_Rekuperationsstufe 0;
BA_ "GenSigSwitchedByIgnition" SG_ 391 EV_Rekuperationsstufe 0;
BA_ "GenSigSendType" SG_ 391 MO_Drehzahl_VM 0;
BA_ "GenSigSwitchedByIgnition" SG_ 391 MO_Drehzahl_VM 0;
BA_ "GenSigSendType" SG_ 391 MO_Fehler_Notabschaltung_Klima 3;
BA_ "GenSigSwitchedByIgnition" SG_ 391 MO_Fehler_Notabschaltung_Klima 0;
BA_ "GenSigSendType" SG_ 391 MO_Fehler_NTKreis 0;
BA_ "GenSigSwitchedByIgnition" SG_ 391 MO_Fehler_NTKreis 0;
BA_ "Fehlerwert" SG_ 391 MO_Fehler_NTKreis 1;
BA_ "GenSigSendType" SG_ 391 MO_KLE_FStatus 0;
BA_ "GenSigSwitchedByIgnition" SG_ 391 MO_KLE_FStatus 0;
BA_ "Fehlerwert" SG_ 391 MO_KLE_FStatus 3;
BA_ "GenSigSendType" SG_ 391 MO_Tankbereitschaft_Status 0;
BA_ "GenSigSwitchedByIgnition" SG_ 391 MO_Tankbereitschaft_Status 0;
BA_ "GenSigSendType" SG_ 391 MO_Tankklappensteuerung 0;
BA_ "GenSigSwitchedByIgnition" SG_ 391 MO_Tankklappensteuerung 0;
BA_ "GenSigSendType" SG_ 391 MO_Waehlpos 3;
BA_ "GenSigSwitchedByIgnition" SG_ 391 MO_Waehlpos 0;
BA_ "Fehlerwert" SG_ 391 MO_Waehlpos 7;
BA_ "GenSigSendType" SG_ 391 MO_WH_Texte 3;
BA_ "GenSigSwitchedByIgnition" SG_ 391 MO_WH_Texte 0;
BA_ "GenSigSendType" SG_ 391 Motor_EV_01_BZ 0;
BA_ "GenSigFuncType" SG_ 391 Motor_EV_01_BZ 1;
BA_ "GenSigSwitchedByIgnition" SG_ 391 Motor_EV_01_BZ 0;
BA_ "GenSigSendType" SG_ 391 Motor_EV_01_CRC 0;
BA_ "GenSigFuncType" SG_ 391 Motor_EV_01_CRC 2;
BA_ "GenSigSwitchedByIgnition" SG_ 391 Motor_EV_01_CRC 0;
BA_ "GenSigSendType" SG_ 339 MO_ErwGrenzen_Anf 3;
BA_ "GenSigSwitchedByIgnition" SG_ 339 MO_ErwGrenzen_Anf 0;
BA_ "GenSigSendType" SG_ 339 MO_Fehler_Notentladung_Anf 3;
BA_ "GenSigSwitchedByIgnition" SG_ 339 MO_Fehler_Notentladung_Anf 0;
BA_ "GenSigSendType" SG_ 339 MO_HVEM_Eskalation 3;
BA_ "GenSigSwitchedByIgnition" SG_ 339 MO_HVEM_Eskalation 0;
BA_ "GenSigSendType" SG_ 339 MO_HVEM_MaxLeistung 0;
BA_ "GenSigStartValue" SG_ 339 MO_HVEM_MaxLeistung 510;
BA_ "GenSigSwitchedByIgnition" SG_ 339 MO_HVEM_MaxLeistung 0;
BA_ "GenSigSendType" SG_ 339 MO_HVK_AntriebFehlerstatus 3;
BA_ "GenSigStartValue" SG_ 339 MO_HVK_AntriebFehlerstatus 7;
BA_ "GenSigSwitchedByIgnition" SG_ 339 MO_HVK_AntriebFehlerstatus 0;
BA_ "GenSigSendType" SG_ 339 MO_HVK_AntriebZustand 3;
BA_ "GenSigStartValue" SG_ 339 MO_HVK_AntriebZustand 7;
BA_ "GenSigSwitchedByIgnition" SG_ 339 MO_HVK_AntriebZustand 0;
BA_ "GenSigSendType" SG_ 339 MO_HVK_EmFehlerstatus 3;
BA_ "GenSigStartValue" SG_ 339 MO_HVK_EmFehlerstatus 7;
BA_ "GenSigSwitchedByIgnition" SG_ 339 MO_HVK_EmFehlerstatus 0;
BA_ "GenSigSendType" SG_ 339 MO_HVK_EmIstzustand 3;
BA_ "GenSigStartValue" SG_ 339 MO_HVK_EmIstzustand 255;
BA_ "GenSigSwitchedByIgnition" SG_ 339 MO_HVK_EmIstzustand 0;
BA_ "GenSigSendType" SG_ 339 MO_MVK_AntriebFehlerstatus 3;
BA_ "GenSigStartValue" SG_ 339 MO_MVK_AntriebFehlerstatus 7;
BA_ "GenSigSwitchedByIgnition" SG_ 339 MO_MVK_AntriebFehlerstatus 0;
BA_ "GenSigSendType" SG_ 339 MO_MVK_AntriebZustand 3;
BA_ "GenSigStartValue" SG_ 339 MO_MVK_AntriebZustand 7;
BA_ "GenSigSwitchedByIgnition" SG_ 339 MO_MVK_AntriebZustand 0;
BA_ "GenSigSendType" SG_ 339 MO_MVK_Bordnetz_Anf 3;
BA_ "GenSigSwitchedByIgnition" SG_ 339 MO_MVK_Bordnetz_Anf 0;
BA_ "GenSigSendType" SG_ 339 MO_MVK_EmFehlerstatus 3;
BA_ "GenSigStartValue" SG_ 339 MO_MVK_EmFehlerstatus 7;
BA_ "GenSigSwitchedByIgnition" SG_ 339 MO_MVK_EmFehlerstatus 0;
BA_ "GenSigSendType" SG_ 339 MO_MVK_EmIstzustand 3;
BA_ "GenSigStartValue" SG_ 339 MO_MVK_EmIstzustand 255;
BA_ "GenSigSwitchedByIgnition" SG_ 339 MO_MVK_EmIstzustand 0;
BA_ "GenSigSendType" SG_ 339 MSG_HYB_30_BZ 0;
BA_ "GenSigFuncType" SG_ 339 MSG_HYB_30_BZ 1;
BA_ "GenSigSwitchedByIgnition" SG_ 339 MSG_HYB_30_BZ 0;
BA_ "GenSigSendType" SG_ 339 MSG_HYB_30_CRC 0;
BA_ "GenSigFuncType" SG_ 339 MSG_HYB_30_CRC 2;
BA_ "GenSigSwitchedByIgnition" SG_ 339 MSG_HYB_30_CRC 0;
BA_ "GenSigSendType" SG_ 931 MVEM_DC_SollLeistung_MV 0;
BA_ "GenSigStartValue" SG_ 931 MVEM_DC_SollLeistung_MV 254;
BA_ "GenSigSwitchedByIgnition" SG_ 931 MVEM_DC_SollLeistung_MV 0;
BA_ "Fehlerwert" SG_ 931 MVEM_DC_SollLeistung_MV 255;
BA_ "GenSigSendType" SG_ 931 MVEM_DC_SollSpannung_MV 0;
BA_ "GenSigStartValue" SG_ 931 MVEM_DC_SollSpannung_MV 254;
BA_ "GenSigSwitchedByIgnition" SG_ 931 MVEM_DC_SollSpannung_MV 0;
BA_ "Fehlerwert" SG_ 931 MVEM_DC_SollSpannung_MV 255;
BA_ "GenSigSendType" SG_ 931 MVEM_EMG_MaxGenSpannung 0;
BA_ "GenSigStartValue" SG_ 931 MVEM_EMG_MaxGenSpannung 254;
BA_ "GenSigSwitchedByIgnition" SG_ 931 MVEM_EMG_MaxGenSpannung 0;
BA_ "Fehlerwert" SG_ 931 MVEM_EMG_MaxGenSpannung 255;
BA_ "GenSigSendType" SG_ 931 MVEM_EMG_MaxGenStrom 0;
BA_ "GenSigStartValue" SG_ 931 MVEM_EMG_MaxGenStrom 254;
BA_ "GenSigSwitchedByIgnition" SG_ 931 MVEM_EMG_MaxGenStrom 0;
BA_ "Fehlerwert" SG_ 931 MVEM_EMG_MaxGenStrom 255;
BA_ "GenSigSendType" SG_ 931 MVEM_IstStrom_MVVerbraucher 0;
BA_ "GenSigStartValue" SG_ 931 MVEM_IstStrom_MVVerbraucher 1022;
BA_ "GenSigSwitchedByIgnition" SG_ 931 MVEM_IstStrom_MVVerbraucher 0;
BA_ "Fehlerwert" SG_ 931 MVEM_IstStrom_MVVerbraucher 1023;
BA_ "GenSigSendType" SG_ 2589283456 MVEM_Kaltstart_StuetzLeistung 0;
BA_ "GenSigStartValue" SG_ 2589283456 MVEM_Kaltstart_StuetzLeistung 254;
BA_ "GenSigSwitchedByIgnition" SG_ 2589283456 MVEM_Kaltstart_StuetzLeistung 0;
BA_ "Fehlerwert" SG_ 2589283456 MVEM_Kaltstart_StuetzLeistung 255;
BA_ "GenSigSendType" SG_ 2589283456 MVEM_MO_USoll_Notbetrieb 0;
BA_ "GenSigStartValue" SG_ 2589283456 MVEM_MO_USoll_Notbetrieb 1022;
BA_ "GenSigSwitchedByIgnition" SG_ 2589283456 MVEM_MO_USoll_Notbetrieb 0;
BA_ "Fehlerwert" SG_ 2589283456 MVEM_MO_USoll_Notbetrieb 1023;
BA_ "GenSigSendType" SG_ 2589283456 MVEM_Umax_Rueckspeisung 0;
BA_ "GenSigStartValue" SG_ 2589283456 MVEM_Umax_Rueckspeisung 254;
BA_ "GenSigSwitchedByIgnition" SG_ 2589283456 MVEM_Umax_Rueckspeisung 0;
BA_ "Fehlerwert" SG_ 2589283456 MVEM_Umax_Rueckspeisung 255;
BA_ "GenSigSendType" SG_ 2589283456 MVEM_Umin_Funktionsgruppe_A 0;
BA_ "GenSigStartValue" SG_ 2589283456 MVEM_Umin_Funktionsgruppe_A 254;
BA_ "GenSigSwitchedByIgnition" SG_ 2589283456 MVEM_Umin_Funktionsgruppe_A 0;
BA_ "Fehlerwert" SG_ 2589283456 MVEM_Umin_Funktionsgruppe_A 255;
BA_ "GenSigSendType" SG_ 2589283456 MVEM_Umin_Funktionsgruppe_B 0;
BA_ "GenSigStartValue" SG_ 2589283456 MVEM_Umin_Funktionsgruppe_B 254;
BA_ "GenSigSwitchedByIgnition" SG_ 2589283456 MVEM_Umin_Funktionsgruppe_B 0;
BA_ "Fehlerwert" SG_ 2589283456 MVEM_Umin_Funktionsgruppe_B 255;
BA_ "GenSigSendType" SG_ 2589283456 MVEM_Umin_Funktionsgruppe_C 0;
BA_ "GenSigStartValue" SG_ 2589283456 MVEM_Umin_Funktionsgruppe_C 254;
BA_ "GenSigSwitchedByIgnition" SG_ 2589283456 MVEM_Umin_Funktionsgruppe_C 0;
BA_ "Fehlerwert" SG_ 2589283456 MVEM_Umin_Funktionsgruppe_C 255;
BA_ "GenSigSendType" SG_ 1284 MV_Bordnetz_aktiv 0;
BA_ "GenSigSwitchedByIgnition" SG_ 1284 MV_Bordnetz_aktiv 0;
BA_ "GenSigSendType" SG_ 1284 MV_Bordnetz_belastbar 3;
BA_ "GenSigSwitchedByIgnition" SG_ 1284 MV_Bordnetz_belastbar 0;
BA_ "GenSigSendType" SG_ 1284 MV_Bordnetz_Fehler 3;
BA_ "GenSigSwitchedByIgnition" SG_ 1284 MV_Bordnetz_Fehler 0;
BA_ "Fehlerwert" SG_ 1284 MV_Bordnetz_Fehler 1;
BA_ "GenSigSendType" SG_ 1284 MVK_01_BZ 0;
BA_ "GenSigFuncType" SG_ 1284 MVK_01_BZ 1;
BA_ "GenSigSwitchedByIgnition" SG_ 1284 MVK_01_BZ 0;
BA_ "GenSigSendType" SG_ 1284 MVK_01_CRC 0;
BA_ "GenSigFuncType" SG_ 1284 MVK_01_CRC 2;
BA_ "GenSigSwitchedByIgnition" SG_ 1284 MVK_01_CRC 0;
BA_ "GenSigSendType" SG_ 1284 MVK_BMS_Sollmodus 3;
BA_ "GenSigStartValue" SG_ 1284 MVK_BMS_Sollmodus 7;
BA_ "GenSigSwitchedByIgnition" SG_ 1284 MVK_BMS_Sollmodus 0;
BA_ "GenSigSendType" SG_ 1284 MVK_BOOST_Sollmodus 3;
BA_ "GenSigStartValue" SG_ 1284 MVK_BOOST_Sollmodus 7;
BA_ "GenSigSwitchedByIgnition" SG_ 1284 MVK_BOOST_Sollmodus 0;
BA_ "GenSigSendType" SG_ 1284 MVK_DCDC_Sollmodus 3;
BA_ "GenSigStartValue" SG_ 1284 MVK_DCDC_Sollmodus 7;
BA_ "GenSigSwitchedByIgnition" SG_ 1284 MVK_DCDC_Sollmodus 0;
BA_ "GenSigSendType" SG_ 1284 MVK_DCDC_Sollmodus_02 3;
BA_ "GenSigStartValue" SG_ 1284 MVK_DCDC_Sollmodus_02 7;
BA_ "GenSigSwitchedByIgnition" SG_ 1284 MVK_DCDC_Sollmodus_02 0;
BA_ "GenSigSendType" SG_ 1284 MVK_eABC_Sollmodus 3;
BA_ "GenSigStartValue" SG_ 1284 MVK_eABC_Sollmodus 7;
BA_ "GenSigSwitchedByIgnition" SG_ 1284 MVK_eABC_Sollmodus 0;
BA_ "GenSigSendType" SG_ 1284 MVK_eAWS_Sollmodus 3;
BA_ "GenSigStartValue" SG_ 1284 MVK_eAWS_Sollmodus 7;
BA_ "GenSigSwitchedByIgnition" SG_ 1284 MVK_eAWS_Sollmodus 0;
BA_ "GenSigSendType" SG_ 1284 MVK_Istmodus_Anf 3;
BA_ "GenSigSwitchedByIgnition" SG_ 1284 MVK_Istmodus_Anf 0;
BA_ "GenSigSendType" SG_ 1284 MVK_MO_EmSollzustand 3;
BA_ "GenSigStartValue" SG_ 1284 MVK_MO_EmSollzustand 255;
BA_ "GenSigSwitchedByIgnition" SG_ 1284 MVK_MO_EmSollzustand 0;
BA_ "GenSigSendType" SG_ 1284 MVK_MV_Batteriewarnung 3;
BA_ "GenSigSwitchedByIgnition" SG_ 1284 MVK_MV_Batteriewarnung 0;
BA_ "GenSigSendType" SG_ 1284 MVK_MV_Netz_Warnungen 3;
BA_ "GenSigSwitchedByIgnition" SG_ 1284 MVK_MV_Netz_Warnungen 0;
BA_ "GenSigSendType" SG_ 1284 MVK_MVPTC_Sollmodus 3;
BA_ "GenSigStartValue" SG_ 1284 MVK_MVPTC_Sollmodus 7;
BA_ "GenSigSwitchedByIgnition" SG_ 1284 MVK_MVPTC_Sollmodus 0;
BA_REL_ "GenSigTimeoutTime" BU_SG_REL_ BMS_NV_12V SG_ 1648 MO_Abstellzeit 5000;
BA_REL_ "GenSigTimeoutTime" BU_SG_REL_ BMS_NV_12V SG_ 1648 MO_Abstellzeit_Status 5000;
BA_REL_ "GenSigTimeoutTime" BU_SG_REL_ BMS_NV_12V SG_ 332 OBDProtocol_req 1000;
BA_REL_ "GenSigTimeoutTime" BU_SG_REL_ BMS_NV_12V SG_ 332 OBD_Calc_Load_Val 1000;
BA_REL_ "GenSigTimeoutTime" BU_SG_REL_ BMS_NV_12V SG_ 332 OBD_Eng_Cool_Temp 1000;
BA_REL_ "GenSigTimeoutTime" BU_SG_REL_ BMS_NV_12V SG_ 332 OBD_Abs_Throttle_Pos 1000;
BA_REL_ "GenSigTimeoutTime" BU_SG_REL_ BMS_NV_12V SG_ 332 OBD_Abs_Load_Val 1000;
BA_REL_ "GenSigTimeoutTime" BU_SG_REL_ BMS_NV_12V SG_ 332 OBD_Abs_Pedal_Pos 1000;
BA_REL_ "GenSigTimeoutTime" BU_SG_REL_ BMS_NV_12V SG_ 332 OBD_ClearMem_Inhibit 1000;
BA_REL_ "GenSigTimeoutTime" BU_SG_REL_ BMS_NV_12V SG_ 332 OBD_Sperrung_Kaltstart_Denom 1000;
BA_REL_ "GenSigTimeoutTime" BU_SG_REL_ BMS_NV_12V SG_ 332 OBD_Sperrung_IUMPR 1000;
BA_REL_ "GenSigTimeoutTime" BU_SG_REL_ BMS_NV_12V SG_ 332 OBD_Kaltstart_Denominator 1000;
BA_REL_ "GenSigTimeoutTime" BU_SG_REL_ BMS_NV_12V SG_ 332 OBD_Minimum_Trip 1000;
BA_REL_ "GenSigTimeoutTime" BU_SG_REL_ BMS_NV_12V SG_ 332 OBD_Driving_Cycle 1000;
BA_REL_ "GenSigTimeoutTime" BU_SG_REL_ BMS_NV_12V SG_ 332 OBD_Warm_Up_Cycle 1000;
BA_REL_ "GenSigTimeoutTime" BU_SG_REL_ BMS_NV_12V SG_ 332 OBD_Normed_Trip 1000;
BA_REL_ "GenSigTimeoutTime" BU_SG_REL_ BMS_NV_12V SG_ 332 OBD_Aussen_Temp_gef 1000;
BA_REL_ "GenSigTimeoutTime" BU_SG_REL_ BMS_NV_12V SG_ 1601 MO_OBD_Typ 5000;
BA_REL_ "GenSigTimeoutTime" BU_SG_REL_ BMS_NV_12V SG_ 391 MO_Drehzahl_VM 1000;
BA_REL_ "GenSigTimeoutTime" BU_SG_REL_ Klima SG_ 958 MO_StartStopp_Status 1000;
BA_REL_ "GenSigTimeoutTime" BU_SG_REL_ Klima SG_ 958 MO_StartStopp_Wiederstart 1000;
BA_REL_ "GenSigTimeoutTime" BU_SG_REL_ Klima SG_ 958 MO_StartStopp_Motorstopp 1000;
BA_REL_ "GenSigTimeoutTime" BU_SG_REL_ Klima SG_ 958 MO_Kl_75 1000;
BA_REL_ "GenSigTimeoutTime" BU_SG_REL_ Klima SG_ 958 MO_StartStopp_Fahrerwunsch 1000;
BA_REL_ "GenSigTimeoutTime" BU_SG_REL_ Klima SG_ 958 MO_HYB_Fahrbereitschaft 1000;
BA_REL_ "GenSigTimeoutTime" BU_SG_REL_ Klima SG_ 958 MO_Ext_E_Fahrt_aktiv 1000;
BA_REL_ "GenSigTimeoutTime" BU_SG_REL_ Klima SG_ 958 MO_Klima_Eingr 1000;
BA_REL_ "GenSigTimeoutTime" BU_SG_REL_ Klima SG_ 958 MO_Motor_laeuft 1000;
BA_REL_ "GenSigTimeoutTime" BU_SG_REL_ Klima SG_ 958 MO_EKlKomLeiRed 1000;
BA_REL_ "GenSigTimeoutTime" BU_SG_REL_ Klima SG_ 958 MO_HYB_VM_aktiv 1000;
BA_REL_ "GenSigTimeoutTime" BU_SG_REL_ Klima SG_ 1631 TSK_QBit_Steigung 5000;
BA_REL_ "GenSigTimeoutTime" BU_SG_REL_ Klima SG_ 1631 TSK_Steigung_02 5000;
BA_REL_ "GenSigTimeoutTime" BU_SG_REL_ Klima SG_ 967 MO_Kuehlerluefter_MUX 1000;
BA_REL_ "GenSigTimeoutTime" BU_SG_REL_ Klima SG_ 967 MO_Kuehlerluefter_1 1000;
BA_REL_ "GenSigTimeoutTime" BU_SG_REL_ Klima SG_ 967 MO_Kuehlerluefter_2 1000;
BA_REL_ "GenSigTimeoutTime" BU_SG_REL_ Klima SG_ 967 MO_Zustand_HWP 1000;
BA_REL_ "GenSigTimeoutTime" BU_SG_REL_ Klima SG_ 967 MO_RedFahrleistung_Lampe 1000;
BA_REL_ "GenSigTimeoutTime" BU_SG_REL_ Klima SG_ 1366 MO_Fahrzeugabstellzeit_Status 5000;
BA_REL_ "GenSigTimeoutTime" BU_SG_REL_ Klima SG_ 1366 MO_HV_Auszeit_Status 5000;
BA_REL_ "GenSigTimeoutTime" BU_SG_REL_ Klima SG_ 1366 MO_Fahrzeugabstellzeit 5000;
BA_REL_ "GenSigTimeoutTime" BU_SG_REL_ Klima SG_ 1366 MO_HV_Auszeit 5000;
BA_REL_ "GenSigTimeoutTime" BU_SG_REL_ Klima SG_ 269 MO_Drehzahl_01 500;
BA_REL_ "GenSigTimeoutTime" BU_SG_REL_ Klima SG_ 269 MO_Drehzahl_VM 500;
BA_REL_ "GenSigTimeoutTime" BU_SG_REL_ Klima SG_ 332 MO_Klima_Regelmodus 1000;
BA_REL_ "GenSigTimeoutTime" BU_SG_REL_ Klima SG_ 332 OBDProtocol_req 1000;
BA_REL_ "GenSigTimeoutTime" BU_SG_REL_ Klima SG_ 332 OBD_Calc_Load_Val 1000;
BA_REL_ "GenSigTimeoutTime" BU_SG_REL_ Klima SG_ 332 OBD_Eng_Cool_Temp 1000;
BA_REL_ "GenSigTimeoutTime" BU_SG_REL_ Klima SG_ 332 OBD_Abs_Throttle_Pos 1000;
BA_REL_ "GenSigTimeoutTime" BU_SG_REL_ Klima SG_ 332 OBD_Abs_Load_Val 1000;
BA_REL_ "GenSigTimeoutTime" BU_SG_REL_ Klima SG_ 332 OBD_Abs_Pedal_Pos 1000;
BA_REL_ "GenSigTimeoutTime" BU_SG_REL_ Klima SG_ 332 MO_QBit_Aussen_Temp 1000;
BA_REL_ "GenSigTimeoutTime" BU_SG_REL_ Klima SG_ 332 OBD_Sperrung_IUMPR 1000;
BA_REL_ "GenSigTimeoutTime" BU_SG_REL_ Klima SG_ 332 OBD_Kaltstart_Denominator 1000;
BA_REL_ "GenSigTimeoutTime" BU_SG_REL_ Klima SG_ 332 OBD_Minimum_Trip 1000;
BA_REL_ "GenSigTimeoutTime" BU_SG_REL_ Klima SG_ 332 OBD_Driving_Cycle 1000;
BA_REL_ "GenSigTimeoutTime" BU_SG_REL_ Klima SG_ 332 OBD_Warm_Up_Cycle 1000;
BA_REL_ "GenSigTimeoutTime" BU_SG_REL_ Klima SG_ 332 OBD_Normed_Trip 1000;
BA_REL_ "GenSigTimeoutTime" BU_SG_REL_ Klima SG_ 553 SOK_Motor_54_Signatur 1000;
BA_REL_ "GenSigTimeoutTime" BU_SG_REL_ Klima SG_ 1601 MO_Hybridfahrzeug 5000;
BA_REL_ "GenSigTimeoutTime" BU_SG_REL_ Klima SG_ 1601 MO_OBD_Typ 5000;
BA_REL_ "GenSigTimeoutTime" BU_SG_REL_ Klima SG_ 391 MO_KLE_FStatus 1000;
BA_REL_ "GenSigTimeoutTime" BU_SG_REL_ Klima SG_ 339 MO_HVEM_MaxLeistung 2000;
VAL_ 958 MO_StartStopp_Status 0 "System_in_diesem_KL15_Zyklus_nicht_verfuegbar" 1 "System_aktiv_keine_Freigabe_durch_StartStop_Koordinator" 2 "System_aktiv_alle_Freigaben_liegen_vor" 3 "System_aktiv_mindestens_eine_Freigabe_fehlt" ;
VAL_ 958 MO_StartStopp_Wiederstart 0 "Wiederstart_inaktiv" 1 "Wiederstart_aktiv" ;
VAL_ 958 MO_StartStopp_Motorstopp 0 "Motor_Stop_inaktiv" 1 "Motor_Stop_aktiv" ;
VAL_ 958 MO_Freig_Reku 0 "Rekuperations-Modus aus" 1 "Empfehlung Spannungsanhebung" 2 "Empfehlung Spannungsabsenkung" 3 "Rekuperationsmodus aktiv, Spannungsvariation nicht notwendig" ;
VAL_ 958 MO_Kl_75 0 "Aus" 1 "Ein" ;
VAL_ 958 MO_Kl_50 0 "aus" 1 "KL50_ein_Startausfuehrung_Fahrer" ;
VAL_ 958 MO_Gangposition 0 "Gang_N" 1 "Gang_1" 2 "Gang_2" 3 "Gang_3" 4 "Gang_4" 5 "Gang_5" 6 "Gang_6" 7 "Gang_7" 8 "Gang_8" 9 "Automat_P" 10 "Automat_Vorwaerts_S" 11 "Automat_Vorwaerts_D/E" 12 "Zwischenstellung" 13 "Gang_R" 14 "Istgang_nicht_definiert" 15 "Fehler" ;
VAL_ 958 MO_StartStopp_Fahrerwunsch 0 "Init" 1 "Stoppverbot_durch_Fahrer" 2 "Stoppfreigabe_durch_Fahrer" 3 "Stoppanforderung_durch_Fahrer" ;
VAL_ 958 MO_HYB_Fahrbereitschaft 0 "keine_Fahrbereitschaft" 1 "Fahrbereitschaft" ;
VAL_ 958 MO_Ext_E_Fahrt_aktiv 0 "Rueckmeldung_E_Taster_aus" 1 "Rueckmeldung_E_Taster_ein" ;
VAL_ 958 MO_Fahrer_bremst 0 "kein_Bremsen" 1 "Bremse_betaetigt" ;
VAL_ 958 MO_QBit_Fahrer_bremst 0 "gueltiger_Wert" 1 "Ersatz_Init_oder_Fehlerwert" ;
VAL_ 958 MO_BLS 0 "kein_Bremsen" 1 "Bremse_betaetigt" ;
VAL_ 958 MO_Konsistenz_Bremsped 0 "Bremspedalinformation_plausibel" 1 "Bremspedalinformation_unplausibel" ;
VAL_ 958 MO_Timeout_ESP 0 "Empfang_iO" 1 "Timeout" ;
VAL_ 958 MO_Klima_Eingr 0 "kein Eingriff" 1 "Klimakompressor ausschalten" 2 "Klimakompressor Leistungsreduzierung" 3 "Klimakompressor aufgrund der Heissleuchtenvorwarnung ausschalten" ;
VAL_ 958 MO_Aussp_Anlass 0 "Anlasser_darf_angesteuert_werden" 1 "Anlasser_ausspuren__Ansteuerung_nicht_moeglich" ;
VAL_ 958 MO_Freig_Anlass 0 "Start_nicht_zulaessig" 1 "Startfreigabe" ;
VAL_ 958 MO_Kuppl_schalter 0 "Schalter_sagt_ausgekuppelt" 1 "Schalter_sagt_eingekuppelt" ;
VAL_ 958 MO_Interlock 0 "Interlockschalter_nicht_betaetigt" 1 "Interlockschalter_betaetigt" ;
VAL_ 958 MO_Motor_laeuft 0 "Motor_laeuft_nicht" 1 "Motor_laeuft_autark_und_stabil_und_darf_mechanisch_belastet_werden" ;
VAL_ 958 MO_Kickdown 0 "kein_Kickdown" 1 "Kickdown" ;
VAL_ 958 MO_QBit_KL_75 0 "gueltiger_Wert" 1 "Ersatz_Init_oder_Fehlerwert" ;
VAL_ 958 MO_EKlKomLeiRed 0 "keine_Leistungsbegr" 1 "Leistungsbegr_75" 2 "Leistungsbegr_50" 3 "Leistungsbegr_25" ;
VAL_ 958 MO_Handshake_STH 0 "keine EKP-Ansteuerung durch STH-Anforderung" 1 "EKP-Ansteuerung durch STH-Anforderung" ;
VAL_ 958 MO_BKV_Unterdruckwarnung 0 "Unterdruckhaushalt_iO" 1 "Unterdruckhaushalt_niO" ;
VAL_ 958 MO_Freigabe_Segeln 0 "Segelbetrieb_nicht_freigegeben" 1 "Segelbetrieb_freigegeben" ;
VAL_ 958 MO_PTC_Status 0 "nicht_unterstuetzt" 1 "Stufe_0" 2 "Stufe_1" 3 "Stufe_2" 4 "Stufe_3" 7 "PTC_am_BCM" ;
VAL_ 958 MO_QBit_Gangposition 0 "gueltiger_Wert" 1 "Ersatz_Init_oder_Fehlerwert" ;
VAL_ 958 MO_Signalquelle_Gangposition 0 "Sensorsignal" 1 "Modellsignal" ;
VAL_ 958 MO_Remotestart_Betrieb 0 "MSG_nicht_bereit_fuer_RS_Betrieb" 1 "MSG_bereit_fuer_oder_im_RS_Betrieb" ;
VAL_ 958 MO_Remotestart_moeglich 0 "Remotestart_nicht_moeglich" 1 "Remotestart_moeglich" ;
VAL_ 958 MO_FMAus_aktiv 0 "inaktiv" 1 "Segeln_mit_Motor_aus_aktiv" ;
VAL_ 958 MO_FMAus_Startvariante 0 "kein_Motorstart" 1 "Motorstart_elektrischer_Starter" 2 "GetriebeAnschleppstart" 3 "GetriebeNotAnschleppstart" ;
VAL_ 958 MO_BMS_NV_Anf_stuetzen 0 "nicht_notwendig" 1 "notwendig" ;
VAL_ 958 MO_Zylinderabschaltung 0 "Vollmotorbetrieb_VMB" 1 "Uebergang_HMB_in_VMB" 2 "Uebergang_VMB_in_HMB" 3 "Halbmotorbetrieb_HMB" ;
VAL_ 958 MO_HYB_VM_aktiv 0 "VM_nicht_aktiv" 1 "VM_aktiv" ;
VAL_ 958 MO_StartVorauss_erfuellt 0 "Signal_nicht_bedient" 1 "StartVorauss_nicht_ueberpruefbar" 2 "StartVorauss_nicht_erfuellt" 3 "StartVorauss_erfuellt" ;
VAL_ 1631 TSK_QBit_Steigung 0 "gueltiger_Wert" 1 "Ersatz_Init_oder_Fehlerwert" ;
VAL_ 1631 TSK_QBit_Fahrzeugmasse 0 "gueltiger_Wert" 1 "Ersatz_Init_oder_Fehlerwert" ;
VAL_ 1631 MO_SpannungsAnf_02 0 "keine_Anforderung" 1 "Anforderung_Stufe_1" 2 "Anforderung_Stufe_2" 3 "Anforderung_Stufe_3" ;
VAL_ 1631 MO_DPF_reg 0 "DPF_regeneriert_nicht" 1 "DPF_regeneriert" ;
VAL_ 1631 MO_Heizstrom_EKAT 127 "Fehler" ;
VAL_ 1631 MO_Heizstrom_SCR 63 "Fehler" ;
VAL_ 1631 MO_Anzeige_Kaltleuchte 0 "Lampe_aus" 1 "Lampe_an" ;
VAL_ 1631 MO_P_Generator_ungefiltert_Anf 0 "nicht_angefordert" 1 "angefordert" ;
VAL_ 1631 MO_Energieinhalt_BMS 4094 "Init" 4095 "Fehler" ;
VAL_ 1631 TSK_Fahrzeugmasse_02 255 "Fehler" ;
VAL_ 1631 TSK_Steigung_02 0 "Init_oder_nicht_verbaut" 255 "Fehler" ;
VAL_ 1648 MO_ANC_Kennfeld_Anf 0 "Kennfeld_1" 1 "Uebergang_Kennfeld_2_nach_1" 2 "Uebergang_Kennfeld_1_nach_2" 3 "Kennfeld_2" ;
VAL_ 1648 MO_Bremslicht_Reku 0 "Aus" 1 "Ein" ;
VAL_ 1648 MO_StartStopp_PopUp 0 "Statuswechsel_ohne_Taster (Init)" 1 "StSt_per_Taster_deaktiviert" 2 "StSt_per_Taster_aktiviert" 3 "nicht verwendet" ;
VAL_ 1648 MO1_Sperr_Info_WFS 0 "nicht_gesperrt" 1 "gesperrt" ;
VAL_ 1648 MO1_Freigabe_Info_WFS 0 "ungueltig" 1 "gueltig" ;
VAL_ 1648 MO_EPCL 0 "EPCL_aus_kein_Text" 1 "EPCL_gelb_Stoerung" 2 "EPCL_gelb_Leistungsbeschraenkung" 3 "EPCL_rot_Fzg_sicher_abstellen" ;
VAL_ 1648 MO_Zylabsch_Texte_02 0 "ein_ZAS_generell_keine_ZAS_Anzeigen" 1 "ZAS_im_VMB" 2 "ZAS_im_ASB_1_Zyl_aktiv" 3 "ZAS_im_ASB_2_Zyl_aktiv" 4 "ZAS_im_ASB_3_Zyl_aktiv" 5 "ZAS_im_ASB_4_Zyl_aktiv" 6 "ZAS_im_ASB_5_Zyl_aktiv" 7 "ZAS_im_ASB_6_Zyl_aktiv" 8 "ZAS_im_ASB_8_Zyl_aktiv" 9 "ZAS_im_ASB_12_Zyl_aktiv" 13 "Uebergangsbetrieb" 14 "keine_ZAS_Anzeige_ggf_Stopp_Schub_Betrieb" 15 "ZAS_Stoerungs_Anzeige" ;
VAL_ 1648 MO_Fahrzeugtyp 0 "Verbrenner_Fahrzeug" 1 "Hybrid" 2 "E_Fahrzeug" 3 "E_Fahrzeug_mit_Range_Extender" 4 "Brennstoffzellenfahrzeug" 5 "tbd" 6 "tbd" 7 "tbd" ;
VAL_ 1648 MO_Abstellzeit 254 "Init" 255 "reserviert" ;
VAL_ 1648 MO_Abstellzeit_Status 0 "Abstellzeit_nicht_berechnet" 1 "Abstellzeit_berechnet" 2 "Abstellzeit_Minimalwert" 3 "Abstellzeit_ungueltig" ;
VAL_ 1648 MO1_Freigabe_Verfallsinfo_WFS 0 "verfaellt_nicht" 1 "verfaellt" ;
VAL_ 1648 MO_Hybrid_StartStopp_LED 0 "LED_aus_und_Blinken_aus" 1 "LED_ein_und_Blinken_aus" 2 "LED_ein_und_Blinken_ein_50_percent" 3 "reserviert" ;
VAL_ 1648 MO_Fehler_Zylabsch 0 "kein_Fehler" 1 "Notlauf_Vollmotorbetrieb" 2 "Notlauf_mindestens_einem_abgesch_Zylinder" ;
VAL_ 1648 MO_Anzahl_Abgesch_Zyl 0 "Vollmotorbetrieb" 1 "1_Zylinder_abgeschaltet" 2 "2_Zylinder_abgeschaltet" 3 "3_Zylinder_abgeschaltet" 4 "4_Zylinder_abgeschaltet" 5 "5_Zylinder_abgeschaltet" 6 "6_Zylinder_abgeschaltet" 7 "8_Zylinder_abgeschaltet" ;
VAL_ 1648 MO_Zylabsch_Texte 0 "keine_Texte" 1 "Zylinderabschaltung_deaktivieren" 2 "Zylinderabschaltung_aktivieren" 3 "Zylinderabschaltung_unruhig" ;
VAL_ 1648 MO_Ethanol_BS_Texte 0 "kein_Text" 1 "E85_Warm_Up" 2 "FlexFuel_Warnung_Stufe_3" 3 "Warmfahrempfehlung_MQB__FlexFuel_Warnung_Stufe_1" 4 "FlexFuel_Warnung_Stufe_2" 5 "FlexFuel_Warnung_Stufe_4" 6 "E25_Warm_Up" ;
VAL_ 1648 MO_Drehzahl_Warnung 0 "keinen_Warnhinweis_anzeigen" 1 "Warnhinweis_anzeigen" ;
VAL_ 1648 MO_obere_Drehzahlgrenze 0 "Init" ;
VAL_ 967 MO_Kuehlerluefter_MUX 0 "Kuehlerluefter_1" 1 "Kuehlerluefter_2" ;
VAL_ 967 MO_Kuehlerluefter_1 126 "Init" 127 "Fehler" ;
VAL_ 967 MO_Kuehlerluefter_2 126 "Init" 127 "Fehler" ;
VAL_ 967 MO_EFLEX_Lampe 0 "Lampe_aus" 1 "Lampe_ein" 2 "Lampe_blinkend" 3 "Lampe_blinkend_mit_Akustik" ;
VAL_ 967 MO_KJS_nicht_bereit 0 "kein_Fehler" 1 "Fehler" ;
VAL_ 967 MO_ITM_Warnung_Pumpe 0 "keine_Warnung" 1 "ITM_Warnung" ;
VAL_ 967 WIV_Anzeige_aktiv 0 "Anzeige aus" 1 "WIV Anzeige aktiv" ;
VAL_ 967 WIV_Oelmin_Warn 0 "in_Ordnung" 1 "Warnung" ;
VAL_ 967 WIV_Sensorfehler 0 "in_Ordnung" 1 "Sensor_defekt" ;
VAL_ 967 WIV_Schieflage 0 "Fahrzeug_gerade" 1 "Fahrzeug_in_Schieflage" ;
VAL_ 967 MO_Zustand_HWP 0 "HWP_nicht_schaltbar" 1 "HWP_foerdert_nicht" 2 "HWP_foerdert" 3 "reserviert" ;
VAL_ 967 OLEV_Systemstoerung 0 "Ölsystem i.O." 1 "Systemstörung Ölsystem" ;
VAL_ 967 MO_Oelwarnung_max 0 "keine_Warnung" 1 "Warnfall_aktiv" ;
VAL_ 967 WIV_Oelsystem_aktiv 0 "Anzeige_aus" 1 "Anzeige_aktiv" ;
VAL_ 967 WIV_nicht_betriebswarm 0 "Motor_warm" 1 "Motor_nicht_betriebswarm" ;
VAL_ 967 WIV_Ueberfuell_Warn 0 "in_Ordnung" 1 "Ueberfuellwarnung" ;
VAL_ 967 WIV_laufender_Motor 0 "Messung_moeglich" 1 "Messung_nicht_moeglich" ;
VAL_ 967 MO_E_Warnungen 0 "keine_Anzeige" 1 "Fehler_Elektrosystem_Anhalten" 2 "Fehler_Elektrosystem_Werkstatt" 3 "Elektrosystem_ueberhitzt_Stopp" 4 "Fehler_Hybridsystem_Anhalten" 5 "Fehler_Hybridsystem_Werkstatt" 6 "Fehler_Wasserstoffsystem_Anhalte" 7 "Fehler_Wasserstoffsystem_Werksta" 8 "reserviert_keine_Anzeige" 9 "reserviert_keine_Anzeige" 10 "reserviert_keine_Anzeige" 11 "reserviert_keine_Anzeige" 12 "reserviert_keine_Anzeige" 13 "reserviert_keine_Anzeige" 14 "reserviert_keine_Anzeige" 15 "reserviert_keine_Anzeige" ;
VAL_ 967 MO_Text_Motorstart 0 "keine_Anzeige" 1 "Motor_im_Stoppbetrieb" 2 "StartStopp_sicherheitsbedingt_deaktiviert" 3 "System_fordert_Wiederstart" 4 "Aufforderung_Motorstart" 5 "Motorlauf_noetig" 6 "Motorlaufwarnung" 9 "Unerwuenschter_Motorstillstand" 10 "Motorstart_nicht_moeglich" 11 "Fehler_Kupplungsschalter" 12 "Motor_startet" 13 "Kupplung_betaetigen" 14 "Waehlhebel_in_PN_Position" 15 "Bremse_treten" ;
VAL_ 967 MO_E_Texte 0 "keine_Anzeige" 1 "Batterie_fast_leer" 2 "Ladestecker_nicht_fahrbereit" 3 "VM_Betrieb_erforderlich" 4 "Batterie_laedt_Nicht_ausschalten" 5 "Bitte_Bremse_treten" 6 "manueller_Neustart_erforderlich" 7 "Stopp_Fahrzeug_nicht_abschleppen" 8 "kein_Neustart_Haube_nicht_oeffnen" 9 "Motorstart_im_naechsten_Zyklus" 10 "VM_erforderlich_EVMode_abwaehlen" 11 "laengerer_VMBetrieb_Bordbuch" 12 "Tank_leer_VM_nicht_verfuegbar" 13 "Bitte_warten_Motor_startet" 14 "kein_Start_Batterietemperatur" 15 "Ende_elektrische_Reichweite_erreicht" ;
VAL_ 967 WIV_Oeldyn_avl 0 "Oeldyn_nicht_vorhanden" 1 "Oeldyn_vorhanden" ;
VAL_ 967 OLEV_Oelstand_nicht_vorhanden 0 "Ölstand vorhanden" 1 "Ölstand nicht vorhanden" ;
VAL_ 967 MO_Systemlampe 0 "Lampe aus" 1 "Lampe ein" ;
VAL_ 967 MO_OBD2_Lampe 0 "Lampe aus" 1 "Lampe ein" ;
VAL_ 967 MO_Heissleuchte 0 "Lampe aus" 1 "Lampe ein" ;
VAL_ 967 MO_Partikel_Lampe 0 "Lampe aus" 1 "Lampe ein" ;
VAL_ 967 MO_RedFahrleistung_Lampe 0 "Lampe_aus" 1 "Lampe_ein" ;
VAL_ 967 WIV_Oelstand_nicht_vorhanden 0 "Ölstand vorhanden" 1 "Ölstand nicht vorhanden" ;
VAL_ 967 WIV_nachfuellanzeige_ein 0 "keine_Nachfuellanzeige" 1 "Nachfuellanzeige" ;
VAL_ 967 WIV_Ueberfuell_deaktiv 0 "Ueberfuellwarnung_am_Kombi_aktiv" 1 "Ueberfuellwarnung_am_Kombi_deaktiv" ;
VAL_ 967 WIV_Unterfuell_Warn 0 "in_Ordnung" 1 "Unterfuellwarnung" ;
VAL_ 967 MO_Tankdeckel_Lampe 0 "Lampe aus" 1 "Lampe ein" ;
VAL_ 967 MO_Text_Tankdeckelwarn 0 "kein_Text" 1 "Anzeige_Text_Tankdeckelwarnung_im_Kombi" ;
VAL_ 967 MO_Vorglueh_Lampe 0 "Lampe_aus" 1 "Lampe_ein" ;
VAL_ 967 WIV_Oeldr_Warn_Motor 0 "keine_Warnung" 1 "niedrige_Oeldruckstufe_nicht_erreicht" ;
VAL_ 967 MO_E_Mode 0 "keine_Anzeige" 1 "E_Mode_passiv" 2 "E_Mode_aktiv" 3 "E_Mode_inaktiv_nicht_verfuegbar" 4 "E_Mode_aktiv_nicht_verfuegbar" 5 "reserviert_keine_Anzeige" 6 "reserviert_keine_Anzeige" 7 "reserviert_keine_Anzeige" ;
VAL_ 1366 MO_Fahrzeugabstellzeit_Status 0 "Abstellzeit_nicht_berechnet" 1 "Abstellzeit_berechnet" 2 "Abstellzeit_Minimalwert" 3 "Abstellzeit_ungültig" ;
VAL_ 1366 MO_HV_Auszeit_Status 0 "Abstellzeit_nicht_berechnet" 1 "Abstellzeit_berechnet" 2 "Abstellzeit_Minimalwert" 3 "Abstellzeit_ungültig" ;
VAL_ 1366 MO_Fahrzeugabstellzeit 254 "Init" 255 "Fehler" ;
VAL_ 1366 MO_HV_Auszeit 510 "Init" 511 "Fehler" ;
VAL_ 1366 MO_Verbau_StartSys_Ritzelstarter 0 "nicht_verbaut" 1 "verbaut" ;
VAL_ 1366 MO_Verbau_StartSys_EM_MV 0 "nicht_verbaut" 1 "verbaut" ;
VAL_ 1366 MO_Verbau_StartSys_EM_HV 0 "nicht_verbaut" 1 "verbaut" ;
VAL_ 1366 MO_Verbau_StartSys_RSG_NV 0 "nicht_verbaut" 1 "verbaut" ;
VAL_ 1366 MO_Verbau_StartSys_Q_Diode 0 "nicht_verbaut" 1 "verbaut" ;
VAL_ 1366 MO_Verbau_StartSys_RSG_MV 0 "nicht_verbaut" 1 "verbaut" ;
VAL_ 1366 MO_Ziel_SoC_Fremdladung 254 "Init" ;
VAL_ 1367 Mo_Empf_Red_Genlast 0 "Keine_Empfehlung_Lastredukt_Gen" 1 "Empfehlung_zur_Lastreduktion_Gen" ;
VAL_ 1367 MO_Bordnetz_Anf 0 "Init" 1 "Max_Last" 2 "Max_Last_Verbraucher_aufschalt" 3 "Streckenprognose_verfuegbar" ;
VAL_ 1367 MO_Strecke_Reg_Anf 63 "Init" ;
VAL_ 1367 MO_FestSpannungsAnf 0 "keine_Anforderung" 1 "Anforderung_Aktiv" ;
VAL_ 1367 MO_El_Grundlast_Anf 0 "keine_Anforderung" 1 "Anforderung_aktiv" ;
VAL_ 1367 MO_Kaltstarttemperatur 254 "Init" 255 "Fehler" ;
VAL_ 1367 MO_Kaltstartleistung_Anf 126 "Init" 127 "Fehler" ;
VAL_ 1367 MO_Lastabwurf 0 "Stufe_0" 1 "Stufe_1" 2 "Stufe_2" 3 "Stufe_3" ;
VAL_ 1367 MO_Freilauf_Charisma_FahrPr 0 "keine_Funktion" 1 "Programm_1" 2 "Programm_2" 3 "Programm_3" 4 "Programm_4" 5 "Programm_5" 6 "Programm_6" 7 "Programm_7" 8 "Programm_8" 9 "Programm_9" 10 "Programm_10" 11 "Programm_11" 12 "Programm_12" 13 "Programm_13" 14 "Programm_14" 15 "Programm_15" ;
VAL_ 1367 MO_Freilauf_Charisma_Status 0 "Init" 1 "verfuegbar" 2 "nicht_verfuegbar" 3 "asynchron_durch_Fahrerwunsch" ;
VAL_ 1367 AGK_Charisma_Status 0 "Init" 1 "verfuegbar" 2 "nicht_verfuegbar" 3 "asynchron_durch_Fahrerwunsch" ;
VAL_ 1367 AGK_Charisma_FahrPr 0 "keine_Funktion" 1 "Programm_1" 2 "Programm_2" 3 "Programm_3" 4 "Programm_4" 5 "Programm_5" 6 "Programm_6" 7 "Programm_7" 8 "Programm_8" 9 "Programm_9" 10 "Programm_10" 11 "Programm_11" 12 "Programm_12" 13 "Programm_13" 14 "Programm_14" 15 "Programm_15" ;
VAL_ 269 MO_Mom_Soll_Roh 1022 "Init" ;
VAL_ 269 MO_Mom_Ist_Summe 1022 "Init" ;
VAL_ 269 MO_Mom_Traegheit_Summe 1022 "Init" ;
VAL_ 269 MO_Mom_Soll_gefiltert 1022 "Init" ;
VAL_ 269 MO_Mom_Schub 510 "Init" ;
VAL_ 269 MO_Status_Normalbetrieb_01 0 "kein_Normalbetrieb" 1 "Normalbetrieb_erreicht" ;
VAL_ 269 MO_erste_Ungenauschwelle 0 "genau" 1 "Momente ungenauer >8%" ;
VAL_ 269 MO_QBit_Motormomente 0 "gueltiger_Wert" 1 "Ersatz_Init_oder_Fehlerwert" ;
VAL_ 269 MO_Mom_neg_verfuegbar 510 "Init" 511 "Fehler" ;
VAL_ 269 MO_Mom_Begr_Fahr 510 "Init" 511 "Fehler" ;
VAL_ 269 MO_Mom_Begr_Schalt 1022 "Init" ;
VAL_ 269 MO_QBit_Drehzahl_01 0 "gueltiger_Wert" 1 "Ersatz_Init_oder_Fehlerwert" ;
VAL_ 269 MO_HYB_EMode_Info 0 "Normal_Mode" 1 "Depleting_Mode" 2 "Charge_Mode" 3 "Sonder_Schaltprogramm" ;
VAL_ 269 MO_HYB_max_ind_VM_Mom_02 254 "Init" 255 "Fehler" ;
VAL_ 269 MO_HYB_Zielzustand 0 "Init" 1 "Leerlauf_VM" 2 "hybridisch_Fahren" 3 "Fahren_EM" 4 "Fahrbereitschaft_EM" 5 "Fahrbereitschaft_VM" 7 "Fehler" ;
VAL_ 269 MO_HYB_Modus_Ankopplung_VM 0 "Schlupfankopplung" 1 "Direktankopplung" ;
VAL_ 269 MO_HYB_Freigabe_VM_Eingr 0 "kein_Wunsch" 1 "Eingriff_nicht_freigegeben" 2 "Eingriff_erwuenscht" ;
VAL_ 269 MO_HYB_Sollstatus_K0 0 "geschlossen" 1 "schlupfend" ;
VAL_ 269 MO_HYB_Komfortstufe 0 "normal" 1 "dynamisch" ;
VAL_ 269 MO_HYB_VM_bereit 0 "VM_nicht_bereit" 1 "VM_bereit" ;
VAL_ 269 MO_HYB_Stoppmodus 0 "Softstopp" 1 "Dynamikstopp" ;
VAL_ 269 MO_HYB_LowSpeedModus 0 "LowSpeed_mit_LLDZ" 1 "LowSpeed_ohne_LLDZ" ;
VAL_ 269 MO_HYB_Schaltverhinderung 0 "keine_Schaltverhinderung" 1 "Schaltverhinderung" ;
VAL_ 269 MO_HYB_E_Faktor 0 "null" 1 "plus_1" 2 "plus_2" 3 "plus_3" 4 "plus_4" 5 "plus_5" 6 "plus_6" 7 "plus_7" 8 "minus_8" 9 "minus_7" 10 "minus_6" 11 "minus_5" 12 "minus_4" 13 "minus_3" 14 "minus_2" 15 "minus_1" ;
VAL_ 269 MO_HYB_VM_Mom_oE_02 254 "Init" 255 "Fehler" ;
VAL_ 269 MO_EM1_SollDrehzahl 32767 "Init" ;
VAL_ 269 MO_Luftpfad_Verzugszeit_praed 0 "keine_Praediktion" ;
VAL_ 269 MO_EM2_SollDrehzahl 32767 "Init" ;
VAL_ 269 MO_TNW_Min_Strom_Lim 8190 "Init" ;
VAL_ 269 MO_TNW_Max_Strom_Lim 8190 "Init" ;
VAL_ 332 MO_Anforderung_HMS 0 "keine_Anforderung" 1 "halten" 2 "parken" 3 "halten_Standby" 4 "anfahren" 5 "Loesen_ueber_Rampe" 7 "HMS_uebernehmen" ;
VAL_ 332 FoD_DTC_TSK_GRA 0 "Kein_DTC" 1 "DTC_vorhanden_oder_in_Quali" ;
VAL_ 332 TSK_vMax_aktuell 254 "kein_Limit_aktiv" 255 "Init" ;
VAL_ 332 ISA_Status 0 "ISA_nicht_aktiv" 1 "Init" 2 "ISA_degradiert" 3 "ISA_aktiv" 4 "reserviert" 5 "reserviert" 6 "reserviert" 7 "reserviert" ;
VAL_ 332 ISA_Regelung_aktiv 0 "ISA_Regelung_nicht_aktiv" 1 "ISA_Regelung_aktiv" ;
VAL_ 332 ISA_Tempolimitwarnung 0 "ISA_keine_Warnung" 1 "ISA_Warnung_aktiv" ;
VAL_ 332 MO_Red_El_Fahrleistung 0 "keine_Anzeige" 1 "mehr_als_20Prcnt_Red" 2 "Reserve_1" 3 "Reserve_2" 4 "unter_GBB_Schwelle_Anhaenger" 5 "unter_GBB_Schwelle" 6 "unter_minimal_Schwelle" 7 "kein_Vortrieb" ;
VAL_ 332 TSK_Status_EA 0 "Aus" 1 "Init_oder_nicht_verbaut" 3 "Aktiv" 4 "Uebertreten" 5 "Abschaltung_laeuft" 6 "Reversibel_aus" 7 "Fehler" ;
VAL_ 332 FoD_DTC_TSK_ACC 0 "Kein_DTC" 1 "DTC_vorhanden_oder_in_Quali" ;
VAL_ 332 TSK_ACC_FoD_Status 0 "default" 1 "nicht_aktiv" 2 "aktiv" 3 "nicht_genutzt" ;
VAL_ 332 TSK_GRA_FoD_Status 0 "default" 1 "nicht_aktiv" 2 "aktiv" 3 "nicht_genutzt" ;
VAL_ 332 TSK_vMax_Fahrerassistenz 511 "Init_ungueltig_keine_Beschraenkung" ;
VAL_ 332 TSK_Einheit_vMax_Fahrerassistenz 0 "kmh" 1 "mph" ;
VAL_ 332 TSK_Status_PLA 0 "Aus_Funktionsbereit" 1 "Init_oder_nicht_verbaut" 2 "aktivierbar" 3 "aktiv" 5 "Abschaltung_laeuft" 6 "reversibel_aus" 7 "Fehler" ;
VAL_ 332 TSK_aktives_System 0 "keine_Funktion_aktiv" 1 "GRA_ACC" 2 "ARA" 3 "Speedlimiter" 4 "IPA" 5 "PLA" 6 "PEA_Ausrollassistent" 7 "EA" ;
VAL_ 332 TSK_erhoehter_Fahrwiderstand 0 "kein_erhoehter_Fahrwiderstand" 1 "erhoehter_Fahrwiderstand" ;
VAL_ 332 TSK_Anf_Antriebsmoment 0 "keine_Anforderung" 1 "Anforderung_aktiv" ;
VAL_ 332 TSK_Status_ARA 0 "Aus" 1 "Init_oder_nicht_verbaut" 2 "aktivierbar" 3 "aktiv" 5 "abschaltung_laeuft" 6 "reversibel_aus" 7 "Fehler" ;
VAL_ 332 TSK_Status_IPA 0 "Aus_Funktionsbereit" 1 "Init_oder_nicht_verbaut" 2 "aktivierbar" 3 "aktiv" 4 "Fahreruebernahme_angefordert" 5 "Abschaltung_laueft" 6 "reversibel_aus" 7 "Fehler" ;
VAL_ 332 TSK_aktives_System_02 0 "keine_Funktion_aktiv" 1 "GRA_ACC" 2 "ARA" 3 "Speedlimiter" 4 "IPA" 5 "PLA" 6 "PEA_Ausrollassistent" 7 "EA" 8 "Staupilot" 9 "RHP" ;
VAL_ 332 TSK_Status_RHP 0 "off" 1 "init" 2 "standby" 3 "active" 4 "driver_override" 5 "shutdown" 6 "reversible_failure" 7 "irreversible_failure" ;
VAL_ 332 MO_Kuppl_betaetigt 0 "Kupplung_nicht_betaetigt" 1 "Kupplung_betaetigt" ;
VAL_ 332 MO_QBit_Kuppl_betaetigt 0 "gueltiger_Wert" 1 "Ersatz_Init_oder_Fehlerwert" ;
VAL_ 332 MO_Klima_Regelmodus 0 "Init" 1 "Regelmodus_1" 2 "Regelmodus_2" 3 "Regelmodus_3" ;
VAL_ 332 MO_Fahrbereitschaft 0 "Fahrzykl_inaktiv__kein_Antrieb" 1 "Fahrzykl_aktiv__kein_Antrieb" 2 "Fahrzykl_aktiv__Antrieb_moeglich" ;
VAL_ 332 MO_Freilauf_Info 0 "Freilauf_freigegeben" 1 "Weiches_Veto_uebertippbar" 2 "Hartes_Veto_Abbruch" 3 "Freilauf_Anforderung" ;
VAL_ 332 CE_FlgLnchCtlPreCnd 0 "not_fulfilled" 1 "fulfilled" ;
VAL_ 332 MO_Krit_Heckobjekt 0 "Init_kein_relevantes_Objekt" 1 "Entfernung_grosser_Abstand" 2 "Annaeherung_grosser_Abstand" 3 "Entfernung_geringer_Abstand" 4 "Annaeherung_geringer_Abstand" 7 "Fehler" ;
VAL_ 332 MO_NGS_Gangpos 0 "nicht_bedient" 1 "1_3_oder_5" 2 "2_4_6_oder_R" 3 "R" 4 "Neutralposition" 5 "Zwischenposition" 6 "Sensor_temp_nicht_verfuegbar" 7 "Fehler" ;
VAL_ 332 MO_Freilauf_Status 0 "Freilauf_inaktiv_aber_moeglich" 1 "Freilauf_aktiv" 2 "Freilauf_nicht_moegl_1Verhinderer" 3 "Freilauf_nicht_moegl_gr_1Verhinderer" 7 "Fehler" ;
VAL_ 332 MO_EBoost_verf_praed 0 "Init_oder_nicht_verfuegbar" 1 "EBoost_kurzzeit_verfuegbar" 2 "EBoost_langzeit_verfuegbar" ;
VAL_ 332 MO_Heckspoiler_Anf 0 "nicht_angefordert" 1 "angefordert" ;
VAL_ 332 MO_eLaunch_verf 0 "Init" 1 "nicht_verfuegbar" 2 "verfuegbar" ;
VAL_ 332 MO_Positionierung_aktiv 0 "keine_Positionierung_aktiv" 1 "Positionierung_aktiv" ;
VAL_ 332 MO_Veto_Launchcontrol 0 "kein_Veto__LC_moeglich" 1 "Veto__LC_nicht_moeglich" ;
VAL_ 332 MO_Startwunsch 0 "kein_Startwunsch" 1 "Startwunsch" ;
VAL_ 332 MO_LaunchControl 0 "nicht_verfuegbar" 1 "verfuegbar" ;
VAL_ 332 MO_UBE_Hybrid_Reserve 1023 "Init" ;
VAL_ 332 OBDProtocol_req 0 "OBDonUDS" 1 "OBDclassic" 254 "Init" 255 "Fehler" ;
VAL_ 332 MO_Servicemodus 0 "nicht_aktiv" 1 "Service_Mode_1" 2 "Service_Mode_2" 3 "Service_Mode_3" 4 "Service_Mode_4" 5 "Service_Mode_5" 6 "Service_Mode_6" 7 "Service_Mode_7" 8 "Service_Mode_8" 9 "Service_Mode_9" 10 "Service_Mode_10" 11 "Service_Mode_11" 12 "Service_Mode_12" 13 "Service_Mode_13" 14 "Service_Mode_14" 15 "Service_Mode_15" ;
VAL_ 332 OBD_ClearMem_Inhibit 0 "FSP_Loeschen_zulaessig" 1 "FSP_Loeschen_nicht_zulaessig" ;
VAL_ 332 OBD_Sperrung_Kaltstart_Denom 0 "EVAP_Berechnung_freigegeben" 1 "EVAP_Berechnung_gesperrt" ;
VAL_ 332 MO_QBit_Aussen_Temp 0 "gueltiger_Wert" 1 "Ersatz_Init_oder_Fehlerwert" ;
VAL_ 332 OBD_Sperrung_IUMPR 0 "IUMPR_Berechnung_freigegeben" 1 "IUMPR_Berechnung_gesperrt" ;
VAL_ 332 OBD_Kaltstart_Denominator 0 "Denominator_nicht_hochzaehlen" 1 "Bedingungen_zum_Inkr_des_Kaltstart_Denom_erf" ;
VAL_ 332 OBD_Minimum_Trip 0 "kein_Min_Normed_Trip" 1 "Min_Normed_Trip" ;
VAL_ 332 OBD_Driving_Cycle 0 "kein_Driving_Cycle_erkannt" 1 "Driving_Cycle_erkannt" ;
VAL_ 332 OBD_Warm_Up_Cycle 0 "kein_Warm_Up_Cycle_erkannt" 1 "Warm_Up_Cycle_erkannt" ;
VAL_ 332 OBD_Normed_Trip 0 "kein_Normed_Trip" 1 "Normed_Trip" ;
VAL_ 332 MO_EMG_Min_Leistung 2046 "Init" 2047 "Fehler" ;
VAL_ 332 MO_EMG_Max_Leistung 2046 "Init" 2047 "Fehler" ;
VAL_ 332 MO_MVEM_MinLeistung_MVVerbrauch 1022 "Init" 1023 "Fehler" ;
VAL_ 332 MO_MVEM_MaxLeistung_MVVerbrauch 1022 "Init" 1023 "Fehler" ;
VAL_ 332 MO_UBE_Reserve 1023 "Init" ;
VAL_ 332 OBD_Aussen_Temp_gef 254 "Initwert" 255 "Fehler" ;
VAL_ 190 MO_EM1_MinDrehzahl 16383 "Init" ;
VAL_ 190 MO_EM1_MaxDrehzahl 16383 "Init" ;
VAL_ 190 MO_EM1_DynLimit_AR 255 "Init" ;
VAL_ 190 MO_EM1_Periode_AR 255 "Init" ;
VAL_ 190 MO_EM1_SollMoment 4094 "Init" ;
VAL_ 190 MO_EM1_Sollmodus 0 "Standby" 1 "Momentenreg" 2 "Int_Drehzahlreg" 3 "Spannungsreg" 4 "Ext_Drehzahlreg" 6 "Kalibrierung" 7 "Sonderbremsbetrieb" 8 "Freilauf" 9 "Autonome_Synchronisation" 15 "Initialisierung" ;
VAL_ 190 MO_EM1_Min_Leistung 16382 "Init" ;
VAL_ 190 MO_EM1_Max_Leistung 16382 "Init" ;
VAL_ 190 MO_EM1_Min_Strom_Lim 8190 "Init" ;
VAL_ 190 MO_EM1_Max_Strom_Lim 8190 "Init" ;
VAL_ 190 MO_EM1_AR_Anf 0 "AR_aus" 2 "AR_D2T2" 3 "AR_RDR" 4 "AR_IRDR" ;
VAL_ 190 MO_EM1_Kp_AR 511 "Init" ;
VAL_ 190 MO_EM1_SollSpannung 4095 "Init" ;
VAL_ 190 MO_CluEng_Set 0 "Init" 1 "offen" 2 "geschlossen" 3 "geschlossen_Notbetrieb" ;
VAL_ 190 MO_EM2_MinDrehzahl 16383 "Init" ;
VAL_ 190 MO_EM2_MaxDrehzahl 16383 "Init" ;
VAL_ 190 MO_EM2_DynLimit_AR 255 "Init" ;
VAL_ 190 MO_EM2_Periode_AR 255 "Init" ;
VAL_ 190 MO_EM2_SollMoment 4094 "Init" 4095 "Fehler" ;
VAL_ 190 MO_EM2_Sollmodus 0 "Standby" 1 "Momentenreg" 2 "Int_Drehzahlreg" 3 "Spannungsreg" 4 "Ext_Drehzahlreg" 6 "Kalibrierung" 7 "Sonderbremsbetrieb" 8 "Freilauf" 9 "Autonome_Synchronisation" 15 "Initialisierung" ;
VAL_ 190 MO_EM2_Min_Leistung 16382 "Init" ;
VAL_ 190 MO_EM2_Max_Leistung 16382 "Init" ;
VAL_ 190 MO_EM2_Min_Strom_Lim 8190 "Init" ;
VAL_ 190 MO_EM2_Max_Strom_Lim 8190 "Init" ;
VAL_ 190 MO_EM2_AR_Anf 0 "AR_aus" 2 "AR_D2T2" 3 "AR_RDR" 4 "AR_IRDR" ;
VAL_ 190 MO_EM2_Kp_AR 511 "Init" ;
VAL_ 190 MO_EM2_SollSpannung 4095 "Init" ;
VAL_ 190 MO_CluAxs_Set 0 "Init" 1 "offen" 2 "geschlossen" 3 "geschlossen_Notbetrieb" ;
VAL_ 190 MO_DC_Max_Strom_HV 255 "Init" ;
VAL_ 190 MO_DC_SollSpannung_HV 255 "Init" ;
VAL_ 190 MO_EM1_Max_Moment 4094 "Init" ;
VAL_ 190 MO_EM1_Min_Moment 4094 "Init" ;
VAL_ 190 MO_EM2_Max_Moment 4094 "Init" 4095 "Fehler" ;
VAL_ 190 MO_EM2_Min_Moment 4094 "Init" 4095 "Fehler" ;
VAL_ 1601 MO_Faktor_Momente_02 0 "nicht_belegt" ;
VAL_ 1601 MO_Hybridfahrzeug 0 "kein_Hybridfahrzeug" 1 "Mild_Hybrid" 2 "Full_Hybrid" 3 "PlugIn_Hybrid" ;
VAL_ 1601 MO_Getriebe_Code 0 "Init" 2 "DL501" 3 "DL800" 4 "VL381" 5 "DL382_Front" 6 "DL382_Allrad" 7 "DL702" 8 "AL552_Allrad" 9 "AL552_Front" 10 "AL651" 11 "AL551__AL951__AL1000_8A" 12 "PDK_PAG" 13 "AL551_Hybrid" 15 "Handschalter_konventionell" 16 "AQ250_160" 17 "AQ450" 18 "DQ200" 19 "DQ250" 20 "DQ500" 21 "SQ100" 22 "SQ200" 23 "DQ400E" 24 "DQ381" 25 "AL550" 26 "AQ300" 31 "DL800E" 32 "Single_Gear__ohne_GSG_WH_am_MSG" 33 "EQ550_2P" ;
VAL_ 1601 MO_StartStopp_Codiert 0 "Start_Stopp_nicht_verbaut" 1 "Start_Stopp_verbaut" ;
VAL_ 1601 MO_Anzeige_StSt_gueltig 0 "MO_Text_Motorstart_gueltig" 1 "Signale_MO_Anzeige_StSt_gueltig" ;
VAL_ 1601 MO_Anzahl_Zyl 0 "kein_Zylinder" 1 "1_Zylinder" 2 "2_Zylinder" 3 "3_Zylinder" 4 "4_Zylinder" 5 "5_Zylinder" 6 "6_Zylinder" 7 "7_Zylinder" 8 "8_Zylinder" 9 "9_Zylinder" 10 "10_Zylinder" 11 "11_Zylinder" 12 "12_Zylinder" 13 "15_Zylinder" 14 "16_Zylinder" 15 "18_Zylinder" ;
VAL_ 1601 MO_Kraftstoffart 0 "Diesel" 1 "Benzin_inkl_E25_E85" 2 "CNG" 3 "LPG" 4 "Wasserstoff" 5 "E100_Ethanol" 15 "kein_Verbrennungskraftstoff" ;
VAL_ 1601 MO_Ansaugsystem 0 "Turbo" 1 "Sauger" ;
VAL_ 1601 MO_OBD_Typ 0 "NoOBD_RdW" 1 "EOBD" 2 "US_OBD" 3 "reserviert" ;
VAL_ 1601 MO_DPF_verbaut 0 "kein_DPF_verbaut" 1 "DPF_verbaut" ;
VAL_ 1601 TSK_Codierung 0 "kein_Fahrgeschwindigkeitsregler" 1 "GRA" 2 "GRA_Plus" 3 "Basis_ACC" 4 "ACC_Follow_to_Stop" 5 "ACC_Stop_and_Go" 7 "Codierung_in_Plausibilisierungsphase" ;
VAL_ 391 EV_Rekuperationsstufe 0 "keine_Anzeige" 1 "1" 2 "2" 3 "3" 4 "4" 5 "5" ;
VAL_ 391 MO_Waehlpos 0 "Init_nicht_unterstuetzt" 1 "reserviert" 2 "P" 3 "R" 4 "N" 5 "D" 6 "B" 7 "Fehler" ;
VAL_ 391 MO_Fehler_NTKreis 0 "kein_Fehler" 1 "Fehler" ;
VAL_ 391 MO_Fehler_Notabschaltung_Klima 0 "Init" 1 "HVIL_ist_OK" 2 "HVIL_Fehler" 3 "ohne_Funktion" ;
VAL_ 391 MO_KLE_FStatus 0 "kein_Fehler" 2 "Fehlerentprellung" 3 "Fehler" ;
VAL_ 391 MO_WH_Texte 0 "keine_Anzeige" 1 "ShiftLock__Fussbremse_betaetigen" 3 "Wegrollgefahr_bitte_P_einlegen" 4 "Parksperre_Warnstufe_I" 5 "Parksperre_Warnstufe_II" 6 "P_nur_im_Stillstand_moeglich" ;
VAL_ 391 MO_Tankbereitschaft_Status 0 "keine_Aktion_Init" 1 "Tankbereitschaft_wird_hergestellt" 2 "Tankbereitschaft_ist_hergestellt" 3 "Tankbereitschaft_kann_nicht_hergestellt_werden" 4 "Tanksystem_Systemfehler" 5 "Tankklappe_pruefen_schliessen" 6 "Tankvorgang_abgebrochen" ;
VAL_ 391 MO_Tankklappensteuerung 0 "Init_nicht_verbaut" 1 "Tankklappe_soll_entriegeln" 2 "Tankklappe_soll_verriegeln" 3 "keine_Aktion" ;
VAL_ 339 MO_HVEM_Eskalation 0 "keine_Eskalation_HVEM" 1 "Eskalation_HVEM" ;
VAL_ 339 MO_ErwGrenzen_Anf 0 "normal" 1 "erweitert" ;
VAL_ 339 MO_Fehler_Notentladung_Anf 0 "Init" ;
VAL_ 339 MO_HVEM_MaxLeistung 510 "Init" ;
VAL_ 339 MO_HVK_EmIstzustand 0 "HvOff" 1 "HvStbyReq" 2 "HvStbyOk" 3 "HvBattOnReq" 4 "HvBattOnOk" 10 "HvOnIdle" 18 "HvOnDrvReq" 19 "HvOnDrvOk" 20 "HvOnDrvRdy" 28 "HvStepUpReq" 29 "HvStepUpOk" 30 "HvStepUp" 38 "HvStepDownReq" 39 "HvStepDownOk" 40 "HvStepDown" 46 "HvAcChPreReq" 47 "HvAcChPreOk" 48 "HvAcChReq" 49 "HvAcChOk" 50 "HvAcCh" 56 "HvDcChPreReq" 57 "HvDcChPreOk" 58 "HvDcChReq" 59 "HvDcChOk" 60 "HvDcCh" 67 "HvChOffReq" 68 "HvChOffOk" 69 "HvOnIdleReq" 70 "HvOnIdleOk" 96 "HvCpntOffReq" 97 "HvCpntOffOk" 98 "HvBattOffReq" 99 "HvBattOffOk" 109 "HvDcDcFailOffReq" 110 "HvDcDcFail" 119 "HvElmOffReq" 120 "HvElmOff" 126 "HvFailCpntOffReq" 127 "HvFailCpntOffOk" 128 "HvFailBattOffReq" 129 "HvFailBattOffOk" 130 "HvFailBattOff" 138 "HvFailUCtlReq" 139 "HvFailUCtlOk" 140 "HvFailUCtl" 150 "HvEmgcyOff" 255 "Init" ;
VAL_ 339 MO_HVK_AntriebFehlerstatus 0 "Komponente_IO" 6 "Keine_Komponentenfunktion" 7 "Init" ;
VAL_ 339 MO_MVK_Bordnetz_Anf 0 "keine_Anforderung" 1 "Bordnetzaktivitaet_gefordert" ;
VAL_ 339 MO_HVK_AntriebZustand 0 "Antrieb_AUS" 1 "Antrieb_Startphase" 2 "E_Fahren" 3 "Hybrid_Fahren" 7 "Init" ;
VAL_ 339 MO_HVK_EmFehlerstatus 0 "Komponente_IO" 1 "Eingeschr_KompFkt_Teilbetrieb" 3 "Eingeschr_KompFkt_Interlock" 6 "Keine_Komponentenfunktion" 7 "Init" ;
VAL_ 339 MO_MVK_AntriebFehlerstatus 0 "Komponente_IO" 6 "Keine_Komponentenfunktion" 7 "Init" ;
VAL_ 339 MO_MVK_AntriebZustand 0 "Antrieb_AUS" 1 "Antrieb_Startphase" 2 "FreilaufMotorAus" 7 "Init" ;
VAL_ 339 MO_MVK_EmFehlerstatus 0 "Komponente_IO" 1 "Eingeschr_KompFkt_Teilbetrieb" 6 "Keine_Komponentenfunktion" 7 "Init" ;
VAL_ 339 MO_MVK_EmIstzustand 0 "MvOff" 1 "MvStbyReq" 2 "MvStbyOk" 3 "MvBattOnReq" 4 "MvBattOnOk" 10 "MvOnIdle" 18 "MvOnDrvReq" 19 "MvOnDrvOk" 20 "MvOnDrv" 28 "MvStepUpReq" 29 "MvStepUpOk" 30 "MvStepUp" 38 "MvStepDownReq" 39 "MvStepDownOk" 40 "MvStepDown" 96 "MvCpntOffReq" 97 "MvCpntOffOk" 98 "MvBattOffReq" 99 "MvBattOffOk" 109 "MvDcDcFailOffReq" 110 "MvDcDcFail" 119 "MvElmFailOffReq" 120 "MvElmFail" 126 "MvFailCpntOffReq" 127 "MvFailCpntOffOk" 128 "MvFailBattOffReq" 129 "MvFailBattOffOk" 130 "MvFailBattOff" 138 "MvFailUCtlReq" 139 "MvFailUCtlOk" 140 "MvFailUCtl" 150 "MvEmgcyOff" 255 "Init" ;
VAL_ 931 MVEM_IstStrom_MVVerbraucher 1022 "Init" 1023 "Fehler" ;
VAL_ 931 MVEM_DC_SollSpannung_MV 254 "Init" 255 "Fehler" ;
VAL_ 931 MVEM_DC_SollLeistung_MV 254 "Init" 255 "Fehler" ;
VAL_ 931 MVEM_EMG_MaxGenStrom 254 "Init" 255 "Fehler" ;
VAL_ 931 MVEM_EMG_MaxGenSpannung 254 "Init" 255 "Fehler" ;
VAL_ 2589283456 MVEM_MO_USoll_Notbetrieb 1022 "Init" 1023 "Fehler" ;
VAL_ 2589283456 MVEM_Kaltstart_StuetzLeistung 254 "Init" 255 "Fehler" ;
VAL_ 2589283456 MVEM_Umax_Rueckspeisung 254 "Init" 255 "Fehler" ;
VAL_ 2589283456 MVEM_Umin_Funktionsgruppe_C 254 "Init" 255 "Fehler" ;
VAL_ 2589283456 MVEM_Umin_Funktionsgruppe_B 254 "Init" 255 "Fehler" ;
VAL_ 2589283456 MVEM_Umin_Funktionsgruppe_A 254 "Init" 255 "Fehler" ;
VAL_ 1284 MVK_DCDC_Sollmodus_02 0 "Standby" 1 "MV_On" 2 "Tiefsetzen" 3 "Hochsetzen" 4 "Startunterstuetzung_48V" 6 "Startunterstuetzung_12V" 7 "Init" 9 "MV_On_Notbetrieb" 10 "Tiefsetzen_Notbetrieb" 11 "Pruefpuls_12V" 13 "Reaktivierung_BMS" ;
VAL_ 1284 MVK_MV_Batteriewarnung 0 "Keine_Warnung" 1 "Warnung_Temperatur_Level1" 2 "Warnung_Temperatur_Level2" ;
VAL_ 1284 MV_Bordnetz_belastbar 0 "nicht_belastbar" 1 "belastbar" ;
VAL_ 1284 MV_Bordnetz_aktiv 0 "inaktiv" 1 "aktiv" ;
VAL_ 1284 MVK_BOOST_Sollmodus 0 "Keine_Freigabe" 1 "Freigabe" 7 "Init" ;
VAL_ 1284 MVK_eABC_Sollmodus 0 "Keine_Freigabe" 1 "Freigabe" 7 "Init" ;
VAL_ 1284 MVK_eAWS_Sollmodus 0 "Keine_Freigabe" 1 "Freigabe" 7 "Init" ;
VAL_ 1284 MV_Bordnetz_Fehler 0 "kein_Fehler" 1 "Fehler" ;
VAL_ 1284 MVK_MVPTC_Sollmodus 0 "Keine_Freigabe" 1 "Freigabe" 7 "Init" ;
VAL_ 1284 MVK_Istmodus_Anf 0 "nicht_angefordert" 1 "angefordert" ;
VAL_ 1284 MVK_MO_EmSollzustand 0 "MvOff" 1 "MvStbyReq" 2 "MvStbyWait" 3 "MvBattOnReq" 4 "MvBattOnWait" 10 "MvOnIdle" 18 "MvOnDrvReq" 19 "MvOnDrvWait" 20 "MvOnDrv" 28 "MvStepUpReq" 29 "MvStepUpWait" 30 "MvStepUp" 38 "MvStepDownReq" 39 "MvStepDownWait" 40 "MvStepDown" 96 "MvCpntOffReq" 97 "MvCpntOffWait" 98 "MvBattOffReq" 99 "MvBattOffWait" 109 "MvDcDcFailOffReq" 110 "MvDcDcFail" 119 "MvElmFailOffReq" 120 "MvElmFail" 126 "MvFailCpntOffReq" 127 "MvFailCpntOffWait" 128 "MvFailBattOffReq" 129 "MvFailBattOffWait" 130 "MvFailBattOff" 138 "MvFailUCtlReq" 139 "MvFailUCtlWait" 140 "MvFailUCtl" 150 "MvEmgcyOff" 255 "Init" ;
VAL_ 1284 MVK_BMS_Sollmodus 0 "MV_Off" 1 "MV_On" 7 "Init" ;
VAL_ 1284 MVK_DCDC_Sollmodus 0 "Standby" 1 "MV_On" 2 "Tiefsetzen" 3 "Hochsetzen" 4 "Startunterstuetzung_48V" 6 "Startunterstuetzung_12V" 7 "Init" ;
VAL_ 1284 MVK_MV_Netz_Warnungen 0 "Keine_Warnung" 1 "Warntext_MV_Netz_Anf" 2 "Fehlertext_MV_Netz_Anf" 3 "Warnung_Kein_Wiederstart_moeglic" ;
